VERSION ""

NS_ :

BS_:

BU_: AGSM BCM BSM CADM DMSM DTCM ECM EVCU2 GNMM HCP IPC RFHM SGW TCM
BO_ 1474 IPC_VEHICLE_SETUP2: 48 IPC
 SG_ AUX1_HLEnbl : 9|1@0+ (1,0) [0|1] "" BCM,SGW
 SG_ AUX1_PWRMD : 213|1@0+ (1,0) [0|1] "" BCM,SGW
 SG_ AUX1_TYPE : 13|1@0+ (1,0) [0|1] "" BCM,SGW
 SG_ AUX2_HLEnbl : 8|1@0+ (1,0) [0|1] "" BCM,SGW
 SG_ AUX2_PWRMD : 0|1@0+ (1,0) [0|1] "" BCM,SGW
 SG_ AUX2_TYPE : 12|1@0+ (1,0) [0|1] "" BCM,SGW
 SG_ AUX3_HLEnbl : 23|1@0+ (1,0) [0|1] "" BCM,SGW
 SG_ AUX3_PWRMD : 15|1@0+ (1,0) [0|1] "" BCM,SGW
 SG_ AUX3_TYPE : 11|1@0+ (1,0) [0|1] "" BCM,SGW
 SG_ AUX4_HLEnbl : 22|1@0+ (1,0) [0|1] "" BCM,SGW
 SG_ AUX4_PWRMD : 14|1@0+ (1,0) [0|1] "" BCM,SGW
 SG_ AUX4_TYPE : 10|1@0+ (1,0) [0|1] "" BCM,SGW
 SG_ AUX5_HLEnbl : 55|1@0+ (1,0) [0|1] "" BCM,SGW
 SG_ AUX5_PWRMD : 43|1@0+ (1,0) [0|1] "" BCM,SGW
 SG_ AUX5_TYPE : 41|1@0+ (1,0) [0|1] "" BCM,SGW
 SG_ AUX6_HLEnbl : 54|1@0+ (1,0) [0|1] "" BCM,SGW
 SG_ AUX6_PWRMD : 42|1@0+ (1,0) [0|1] "" BCM,SGW
 SG_ AUX6_TYPE : 40|1@0+ (1,0) [0|1] "" BCM,SGW
 SG_ CRC_IPCVS2 : 319|8@0+ (1,0) [0|255] "-" EVCU2
 SG_ Default_Ride_Height : 44|1@0+ (1,0) [0|1] "" BCM,SGW
 SG_ Display_Synch : 59|1@0+ (1,0) [0|1] "" SGW
 SG_ FOA_Alert_Type : 6|2@0+ (1,0) [0|3] "" BCM,SGW
 SG_ Fuel_Saver_Display : 26|1@0+ (1,0) [0|1] "" BCM,SGW
 SG_ MessageCounter_IPCVS2 : 307|4@0+ (1,0) [0|15] "-" EVCU2
 SG_ ParkSenseSignalView : 37|1@0+ (1,0) [0|1] "" BCM,SGW
 SG_ PFTM_Alert : 95|1@0+ (1,0) [0|1] "" BCM,SGW
 SG_ PFTM_Enable : 94|1@0+ (1,0) [0|1] "" SGW
 SG_ Power_Tailgate_Enable : 53|1@0+ (1,0) [0|1] "" BCM,SGW
 SG_ Rear_G_LGT_with_Cargo_Lights : 47|1@0+ (1,0) [0|1] "" BCM,SGW
 SG_ Rear_Guidance_Light_Status : 62|1@0+ (1,0) [0|1] "" BCM,SGW
 SG_ Rear_Lights_with_Approach : 50|1@0+ (1,0) [0|1] "" BCM,SGW
 SG_ SignatureLightingEnable : 93|1@0+ (1,0) [0|1] "" BCM,SGW
 SG_ Trailer_Light_Check : 7|1@0+ (1,0) [0|1] "" BCM,SGW
 SG_ TSI_Offset_Kph : 31|4@0+ (1,0) [0|15] "" BCM,SGW
 SG_ TSI_Offset_Mph : 19|4@0+ (1,0) [0|15] "" BCM,SGW
 SG_ TurnSignalView : 34|2@0+ (1,0) [0|3] "" BCM,SGW
 SG_ WorksiteINVM_Audible_LFW : 61|1@0+ (1,0) [0|1] "" BCM,SGW
 SG_ WorksiteINVM_Visual_LFW : 60|1@0+ (1,0) [0|1] "" BCM,SGW

BO_ 753 LV_CHARGER1: 32 HCP
 SG_ CRC_LV_CHARGER1 : 191|8@0+ (1,0) [0|255] "-" ECM
 SG_ DCDC_OperationModeSts : 7|4@0+ (1,0) [0|0] "-" ECM
 SG_ HVDC_CurrentFeedback : 3|12@0+ (0.1,-149) [-149|150] "Amp" ECM
 SG_ HVDC_VoltageFeedback : 35|12@0+ (0.125,0) [0|510] "V" ECM
 SG_ LVDC_CurrentFeedback : 19|12@0+ (0.15,-299) [-299|299.5] "Amp" ECM
 SG_ MessageCounter_LV_CHARGER1 : 179|4@0+ (1,0) [0|15] "-" ECM

BO_ 1062 MCPA_DATA2: 64 EVCU2
 SG_ MCPA_Temp : 7|8@0+ (1,-40) [-40|215] "°C" SGW

BO_ 125 MESS_TTPM1: 32 BCM
 SG_ MESS_TTPM1 : 7|64@0+ (1,0) [0|0] "" SGW

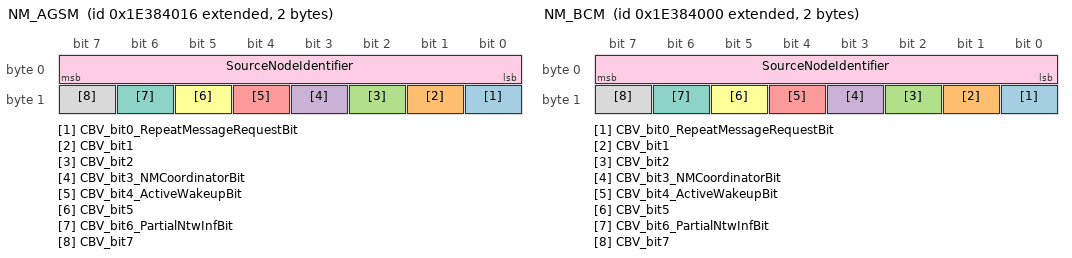
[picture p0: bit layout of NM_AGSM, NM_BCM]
BO_ 2654486550 NM_AGSM: 2 AGSM
 SG_ CBV_bit0_RepeatMessageRequestBit : 8|1@0+ (1,0) [0|1] "" BCM,BSM,CADM,DTCM,ECM,EVCU2,GNMM,HCP,IPC,RFHM,SGW,TCM
 SG_ CBV_bit1 : 9|1@0+ (1,0) [0|1] "" BCM,BSM,CADM,DTCM,ECM,EVCU2,GNMM,HCP,IPC,RFHM,SGW,TCM
 SG_ CBV_bit2 : 10|1@0+ (1,0) [0|1] "" BCM,BSM,CADM,DTCM,ECM,EVCU2,GNMM,HCP,IPC,RFHM,SGW,TCM
 SG_ CBV_bit3_NMCoordinatorBit : 11|1@0+ (1,0) [0|1] "" BCM,BSM,CADM,DTCM,ECM,EVCU2,GNMM,HCP,IPC,RFHM,SGW,TCM
 SG_ CBV_bit4_ActiveWakeupBit : 12|1@0+ (1,0) [0|1] "" BCM,BSM,CADM,DTCM,ECM,EVCU2,GNMM,HCP,IPC,RFHM,SGW,TCM
 SG_ CBV_bit5 : 13|1@0+ (1,0) [0|1] "" BCM,BSM,CADM,DTCM,ECM,EVCU2,GNMM,HCP,IPC,RFHM,SGW,TCM
 SG_ CBV_bit6_PartialNtwInfBit : 14|1@0+ (1,0) [0|1] "" BCM,BSM,CADM,DTCM,ECM,EVCU2,GNMM,HCP,IPC,RFHM,SGW,TCM
 SG_ CBV_bit7 : 15|1@0+ (1,0) [0|1] "" BCM,BSM,CADM,DTCM,ECM,EVCU2,GNMM,HCP,IPC,RFHM,SGW,TCM
 SG_ SourceNodeIdentifier : 7|8@0+ (1,0) [0|63] "-" BCM,BSM,CADM,DTCM,ECM,EVCU2,GNMM,HCP,IPC,RFHM,SGW,TCM

BO_ 2654486528 NM_BCM: 2 BCM
 SG_ CBV_bit0_RepeatMessageRequestBit : 8|1@0+ (1,0) [0|1] "" AGSM,BSM,CADM,DTCM,ECM,EVCU2,GNMM,HCP,IPC,RFHM,SGW,TCM
 SG_ CBV_bit1 : 9|1@0+ (1,0) [0|1] "" AGSM,BSM,CADM,DTCM,ECM,EVCU2,GNMM,HCP,IPC,RFHM,SGW,TCM
 SG_ CBV_bit2 : 10|1@0+ (1,0) [0|1] "" AGSM,BSM,CADM,DTCM,ECM,EVCU2,GNMM,HCP,IPC,RFHM,SGW,TCM
 SG_ CBV_bit3_NMCoordinatorBit : 11|1@0+ (1,0) [0|1] "" AGSM,BSM,CADM,DTCM,ECM,EVCU2,GNMM,HCP,IPC,RFHM,SGW,TCM
 SG_ CBV_bit4_ActiveWakeupBit : 12|1@0+ (1,0) [0|1] "" AGSM,BSM,CADM,DTCM,ECM,EVCU2,GNMM,HCP,IPC,RFHM,SGW,TCM
 SG_ CBV_bit5 : 13|1@0+ (1,0) [0|1] "" AGSM,BSM,CADM,DTCM,ECM,EVCU2,GNMM,HCP,IPC,RFHM,SGW,TCM
 SG_ CBV_bit6_PartialNtwInfBit : 14|1@0+ (1,0) [0|1] "" AGSM,BSM,CADM,DTCM,ECM,EVCU2,GNMM,HCP,IPC,RFHM,SGW,TCM
 SG_ CBV_bit7 : 15|1@0+ (1,0) [0|1] "" AGSM,BSM,CADM,DTCM,ECM,EVCU2,GNMM,HCP,IPC,RFHM,SGW,TCM
 SG_ SourceNodeIdentifier : 7|8@0+ (1,0) [0|255] "-" AGSM,BSM,CADM,DTCM,ECM,EVCU2,GNMM,HCP,IPC,RFHM,SGW,TCM

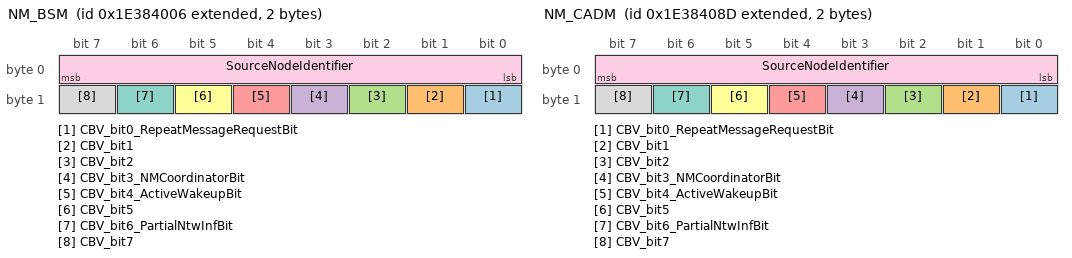
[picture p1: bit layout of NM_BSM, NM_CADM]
BO_ 2654486534 NM_BSM: 2 BSM
 SG_ CBV_bit0_RepeatMessageRequestBit : 8|1@0+ (1,0) [0|1] "" AGSM,BCM,CADM,DTCM,ECM,EVCU2,GNMM,HCP,IPC,RFHM,SGW,TCM
 SG_ CBV_bit1 : 9|1@0+ (1,0) [0|1] "" AGSM,BCM,CADM,DTCM,ECM,EVCU2,GNMM,HCP,IPC,RFHM,SGW,TCM
 SG_ CBV_bit2 : 10|1@0+ (1,0) [0|1] "" AGSM,BCM,CADM,DTCM,ECM,EVCU2,GNMM,HCP,IPC,RFHM,SGW,TCM
 SG_ CBV_bit3_NMCoordinatorBit : 11|1@0+ (1,0) [0|1] "" AGSM,BCM,CADM,DTCM,ECM,EVCU2,GNMM,HCP,IPC,RFHM,SGW,TCM
 SG_ CBV_bit4_ActiveWakeupBit : 12|1@0+ (1,0) [0|1] "" AGSM,BCM,CADM,DTCM,ECM,EVCU2,GNMM,HCP,IPC,RFHM,SGW,TCM
 SG_ CBV_bit5 : 13|1@0+ (1,0) [0|1] "" AGSM,BCM,CADM,DTCM,ECM,EVCU2,GNMM,HCP,IPC,RFHM,SGW,TCM
 SG_ CBV_bit6_PartialNtwInfBit : 14|1@0+ (1,0) [0|1] "" AGSM,BCM,CADM,DTCM,ECM,EVCU2,GNMM,HCP,IPC,RFHM,SGW,TCM
 SG_ CBV_bit7 : 15|1@0+ (1,0) [0|1] "" AGSM,BCM,CADM,DTCM,ECM,EVCU2,GNMM,HCP,IPC,RFHM,SGW,TCM
 SG_ SourceNodeIdentifier : 7|8@0+ (1,0) [0|255] "-" AGSM,BCM,CADM,DTCM,ECM,EVCU2,GNMM,HCP,IPC,RFHM,SGW,TCM

BO_ 2654486669 NM_CADM: 2 CADM
 SG_ CBV_bit0_RepeatMessageRequestBit : 8|1@0+ (1,0) [0|1] "" AGSM,BCM,BSM,DTCM,ECM,EVCU2,GNMM,HCP,IPC,RFHM,SGW,TCM
 SG_ CBV_bit1 : 9|1@0+ (1,0) [0|1] "" AGSM,BCM,BSM,DTCM,ECM,EVCU2,GNMM,HCP,IPC,RFHM,SGW,TCM
 SG_ CBV_bit2 : 10|1@0+ (1,0) [0|1] "" AGSM,BCM,BSM,DTCM,ECM,EVCU2,GNMM,HCP,IPC,RFHM,SGW,TCM
 SG_ CBV_bit3_NMCoordinatorBit : 11|1@0+ (1,0) [0|1] "" AGSM,BCM,BSM,DTCM,ECM,EVCU2,GNMM,HCP,IPC,RFHM,SGW,TCM
 SG_ CBV_bit4_ActiveWakeupBit : 12|1@0+ (1,0) [0|1] "" AGSM,BCM,BSM,DTCM,ECM,EVCU2,GNMM,HCP,IPC,RFHM,SGW,TCM
 SG_ CBV_bit5 : 13|1@0+ (1,0) [0|1] "" AGSM,BCM,BSM,DTCM,ECM,EVCU2,GNMM,HCP,IPC,RFHM,SGW,TCM
 SG_ CBV_bit6_PartialNtwInfBit : 14|1@0+ (1,0) [0|1] "" AGSM,BCM,BSM,DTCM,ECM,EVCU2,GNMM,HCP,IPC,RFHM,SGW,TCM
 SG_ CBV_bit7 : 15|1@0+ (1,0) [0|1] "" AGSM,BCM,BSM,DTCM,ECM,EVCU2,GNMM,HCP,IPC,RFHM,SGW,TCM
 SG_ SourceNodeIdentifier : 7|8@0+ (1,0) [0|255] "-" AGSM,BCM,BSM,DTCM,ECM,EVCU2,GNMM,HCP,IPC,RFHM,SGW,TCM

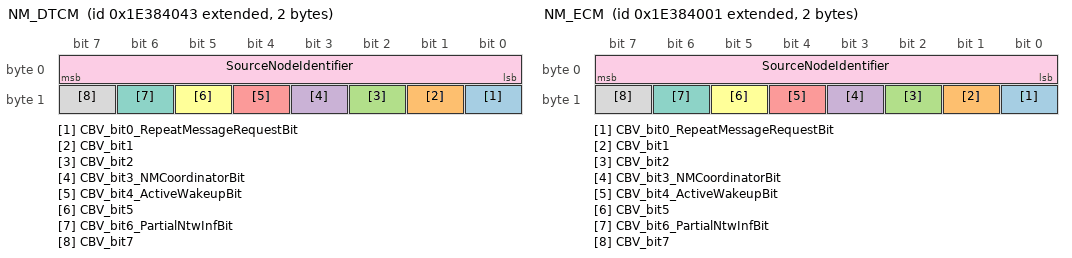
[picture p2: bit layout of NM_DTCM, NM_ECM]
BO_ 2654486595 NM_DTCM: 2 DTCM
 SG_ CBV_bit0_RepeatMessageRequestBit : 8|1@0+ (1,0) [0|1] "" AGSM,BCM,BSM,CADM,ECM,EVCU2,GNMM,HCP,IPC,RFHM,SGW,TCM
 SG_ CBV_bit1 : 9|1@0+ (1,0) [0|1] "" AGSM,BCM,BSM,CADM,ECM,EVCU2,GNMM,HCP,IPC,RFHM,SGW,TCM
 SG_ CBV_bit2 : 10|1@0+ (1,0) [0|1] "" AGSM,BCM,BSM,CADM,ECM,EVCU2,GNMM,HCP,IPC,RFHM,SGW,TCM
 SG_ CBV_bit3_NMCoordinatorBit : 11|1@0+ (1,0) [0|1] "" AGSM,BCM,BSM,CADM,ECM,EVCU2,GNMM,HCP,IPC,RFHM,SGW,TCM
 SG_ CBV_bit4_ActiveWakeupBit : 12|1@0+ (1,0) [0|1] "" AGSM,BCM,BSM,CADM,ECM,EVCU2,GNMM,HCP,IPC,RFHM,SGW,TCM
 SG_ CBV_bit5 : 13|1@0+ (1,0) [0|1] "" AGSM,BCM,BSM,CADM,ECM,EVCU2,GNMM,HCP,IPC,RFHM,SGW,TCM
 SG_ CBV_bit6_PartialNtwInfBit : 14|1@0+ (1,0) [0|1] "" AGSM,BCM,BSM,CADM,ECM,EVCU2,GNMM,HCP,IPC,RFHM,SGW,TCM
 SG_ CBV_bit7 : 15|1@0+ (1,0) [0|1] "" AGSM,BCM,BSM,CADM,ECM,EVCU2,GNMM,HCP,IPC,RFHM,SGW,TCM
 SG_ SourceNodeIdentifier : 7|8@0+ (1,0) [0|255] "-" AGSM,BCM,BSM,CADM,ECM,EVCU2,GNMM,HCP,IPC,RFHM,SGW,TCM

BO_ 2654486529 NM_ECM: 2 ECM
 SG_ CBV_bit0_RepeatMessageRequestBit : 8|1@0+ (1,0) [0|1] "" AGSM,BCM,BSM,CADM,DTCM,EVCU2,GNMM,HCP,IPC,RFHM,SGW,TCM
 SG_ CBV_bit1 : 9|1@0+ (1,0) [0|1] "" AGSM,BCM,BSM,CADM,DTCM,EVCU2,GNMM,HCP,IPC,RFHM,SGW,TCM
 SG_ CBV_bit2 : 10|1@0+ (1,0) [0|1] "" AGSM,BCM,BSM,CADM,DTCM,EVCU2,GNMM,HCP,IPC,RFHM,SGW,TCM
 SG_ CBV_bit3_NMCoordinatorBit : 11|1@0+ (1,0) [0|1] "" AGSM,BCM,BSM,CADM,DTCM,EVCU2,GNMM,HCP,IPC,RFHM,SGW,TCM
 SG_ CBV_bit4_ActiveWakeupBit : 12|1@0+ (1,0) [0|1] "" AGSM,BCM,BSM,CADM,DTCM,EVCU2,GNMM,HCP,IPC,RFHM,SGW,TCM
 SG_ CBV_bit5 : 13|1@0+ (1,0) [0|1] "" AGSM,BCM,BSM,CADM,DTCM,EVCU2,GNMM,HCP,IPC,RFHM,SGW,TCM
 SG_ CBV_bit6_PartialNtwInfBit : 14|1@0+ (1,0) [0|1] "" AGSM,BCM,BSM,CADM,DTCM,EVCU2,GNMM,HCP,IPC,RFHM,SGW,TCM
 SG_ CBV_bit7 : 15|1@0+ (1,0) [0|1] "" AGSM,BCM,BSM,CADM,DTCM,EVCU2,GNMM,HCP,IPC,RFHM,SGW,TCM
 SG_ SourceNodeIdentifier : 7|8@0+ (1,0) [0|255] "-" AGSM,BCM,BSM,CADM,DTCM,EVCU2,GNMM,HCP,IPC,RFHM,SGW,TCM

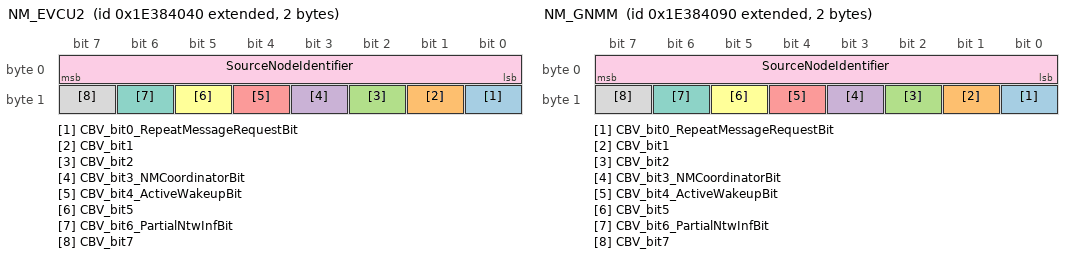
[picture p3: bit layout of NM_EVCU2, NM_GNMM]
BO_ 2654486592 NM_EVCU2: 2 EVCU2
 SG_ CBV_bit0_RepeatMessageRequestBit : 8|1@0+ (1,0) [0|1] "" AGSM,BCM,BSM,CADM,DTCM,ECM,GNMM,HCP,IPC,RFHM,SGW,TCM
 SG_ CBV_bit1 : 9|1@0+ (1,0) [0|1] "" AGSM,BCM,BSM,CADM,DTCM,ECM,GNMM,HCP,IPC,RFHM,SGW,TCM
 SG_ CBV_bit2 : 10|1@0+ (1,0) [0|1] "" AGSM,BCM,BSM,CADM,DTCM,ECM,GNMM,HCP,IPC,RFHM,SGW,TCM
 SG_ CBV_bit3_NMCoordinatorBit : 11|1@0+ (1,0) [0|1] "" AGSM,BCM,BSM,CADM,DTCM,ECM,GNMM,HCP,IPC,RFHM,SGW,TCM
 SG_ CBV_bit4_ActiveWakeupBit : 12|1@0+ (1,0) [0|1] "" AGSM,BCM,BSM,CADM,DTCM,ECM,GNMM,HCP,IPC,RFHM,SGW,TCM
 SG_ CBV_bit5 : 13|1@0+ (1,0) [0|1] "" AGSM,BCM,BSM,CADM,DTCM,ECM,GNMM,HCP,IPC,RFHM,SGW,TCM
 SG_ CBV_bit6_PartialNtwInfBit : 14|1@0+ (1,0) [0|1] "" AGSM,BCM,BSM,CADM,DTCM,ECM,GNMM,HCP,IPC,RFHM,SGW,TCM
 SG_ CBV_bit7 : 15|1@0+ (1,0) [0|1] "" AGSM,BCM,BSM,CADM,DTCM,ECM,GNMM,HCP,IPC,RFHM,SGW,TCM
 SG_ SourceNodeIdentifier : 7|8@0+ (1,0) [0|255] "-" AGSM,BCM,BSM,CADM,DTCM,ECM,GNMM,HCP,IPC,RFHM,SGW,TCM

BO_ 2654486672 NM_GNMM: 2 GNMM
 SG_ CBV_bit0_RepeatMessageRequestBit : 8|1@0+ (1,0) [0|1] "" AGSM,BCM,BSM,CADM,DTCM,ECM,EVCU2,HCP,IPC,RFHM,SGW,TCM
 SG_ CBV_bit1 : 9|1@0+ (1,0) [0|1] "" AGSM,BCM,BSM,CADM,DTCM,ECM,EVCU2,HCP,IPC,RFHM,SGW,TCM
 SG_ CBV_bit2 : 10|1@0+ (1,0) [0|1] "" AGSM,BCM,BSM,CADM,DTCM,ECM,EVCU2,HCP,IPC,RFHM,SGW,TCM
 SG_ CBV_bit3_NMCoordinatorBit : 11|1@0+ (1,0) [0|1] "" AGSM,BCM,BSM,CADM,DTCM,ECM,EVCU2,HCP,IPC,RFHM,SGW,TCM
 SG_ CBV_bit4_ActiveWakeupBit : 12|1@0+ (1,0) [0|1] "" AGSM,BCM,BSM,CADM,DTCM,ECM,EVCU2,HCP,IPC,RFHM,SGW,TCM
 SG_ CBV_bit5 : 13|1@0+ (1,0) [0|1] "" AGSM,BCM,BSM,CADM,DTCM,ECM,EVCU2,HCP,IPC,RFHM,SGW,TCM
 SG_ CBV_bit6_PartialNtwInfBit : 14|1@0+ (1,0) [0|1] "" AGSM,BCM,BSM,CADM,DTCM,ECM,EVCU2,HCP,IPC,RFHM,SGW,TCM
 SG_ CBV_bit7 : 15|1@0+ (1,0) [0|1] "" AGSM,BCM,BSM,CADM,DTCM,ECM,EVCU2,HCP,IPC,RFHM,SGW,TCM
 SG_ SourceNodeIdentifier : 7|8@0+ (1,0) [0|255] "-" AGSM,BCM,BSM,CADM,DTCM,ECM,EVCU2,HCP,IPC,RFHM,SGW,TCM

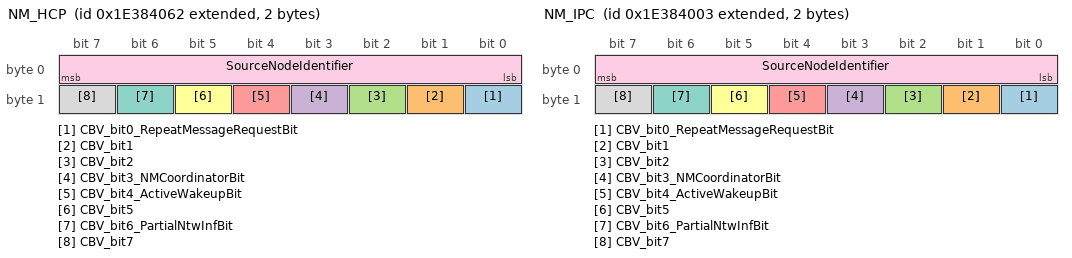
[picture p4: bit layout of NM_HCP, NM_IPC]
BO_ 2654486626 NM_HCP: 2 HCP
 SG_ CBV_bit0_RepeatMessageRequestBit : 8|1@0+ (1,0) [0|1] "" AGSM,BCM,BSM,CADM,DTCM,ECM,EVCU2,GNMM,IPC,RFHM,SGW,TCM
 SG_ CBV_bit1 : 9|1@0+ (1,0) [0|1] "" AGSM,BCM,BSM,CADM,DTCM,ECM,EVCU2,GNMM,IPC,RFHM,SGW,TCM
 SG_ CBV_bit2 : 10|1@0+ (1,0) [0|1] "" AGSM,BCM,BSM,CADM,DTCM,ECM,EVCU2,GNMM,IPC,RFHM,SGW,TCM
 SG_ CBV_bit3_NMCoordinatorBit : 11|1@0+ (1,0) [0|1] "" AGSM,BCM,BSM,CADM,DTCM,ECM,EVCU2,GNMM,IPC,RFHM,SGW,TCM
 SG_ CBV_bit4_ActiveWakeupBit : 12|1@0+ (1,0) [0|1] "" AGSM,BCM,BSM,CADM,DTCM,ECM,EVCU2,GNMM,IPC,RFHM,SGW,TCM
 SG_ CBV_bit5 : 13|1@0+ (1,0) [0|1] "" AGSM,BCM,BSM,CADM,DTCM,ECM,EVCU2,GNMM,IPC,RFHM,SGW,TCM
 SG_ CBV_bit6_PartialNtwInfBit : 14|1@0+ (1,0) [0|1] "" AGSM,BCM,BSM,CADM,DTCM,ECM,EVCU2,GNMM,IPC,RFHM,SGW,TCM
 SG_ CBV_bit7 : 15|1@0+ (1,0) [0|1] "" AGSM,BCM,BSM,CADM,DTCM,ECM,EVCU2,GNMM,IPC,RFHM,SGW,TCM
 SG_ SourceNodeIdentifier : 7|8@0+ (1,0) [0|255] "-" AGSM,BCM,BSM,CADM,DTCM,ECM,EVCU2,GNMM,IPC,RFHM,SGW,TCM

BO_ 2654486531 NM_IPC: 2 IPC
 SG_ CBV_bit0_RepeatMessageRequestBit : 8|1@0+ (1,0) [0|1] "" AGSM,BCM,BSM,CADM,DTCM,ECM,EVCU2,GNMM,HCP,RFHM,SGW,TCM
 SG_ CBV_bit1 : 9|1@0+ (1,0) [0|1] "" AGSM,BCM,BSM,CADM,DTCM,ECM,EVCU2,GNMM,HCP,RFHM,SGW,TCM
 SG_ CBV_bit2 : 10|1@0+ (1,0) [0|1] "" AGSM,BCM,BSM,CADM,DTCM,ECM,EVCU2,GNMM,HCP,RFHM,SGW,TCM
 SG_ CBV_bit3_NMCoordinatorBit : 11|1@0+ (1,0) [0|1] "" AGSM,BCM,BSM,CADM,DTCM,ECM,EVCU2,GNMM,HCP,RFHM,SGW,TCM
 SG_ CBV_bit4_ActiveWakeupBit : 12|1@0+ (1,0) [0|1] "" AGSM,BCM,BSM,CADM,DTCM,ECM,EVCU2,GNMM,HCP,RFHM,SGW,TCM
 SG_ CBV_bit5 : 13|1@0+ (1,0) [0|1] "" AGSM,BCM,BSM,CADM,DTCM,ECM,EVCU2,GNMM,HCP,RFHM,SGW,TCM
 SG_ CBV_bit6_PartialNtwInfBit : 14|1@0+ (1,0) [0|1] "" AGSM,BCM,BSM,CADM,DTCM,ECM,EVCU2,GNMM,HCP,RFHM,SGW,TCM
 SG_ CBV_bit7 : 15|1@0+ (1,0) [0|1] "" AGSM,BCM,BSM,CADM,DTCM,ECM,EVCU2,GNMM,HCP,RFHM,SGW,TCM
 SG_ SourceNodeIdentifier : 7|8@0+ (1,0) [0|255] "-" AGSM,BCM,BSM,CADM,DTCM,ECM,EVCU2,GNMM,HCP,RFHM,SGW,TCM

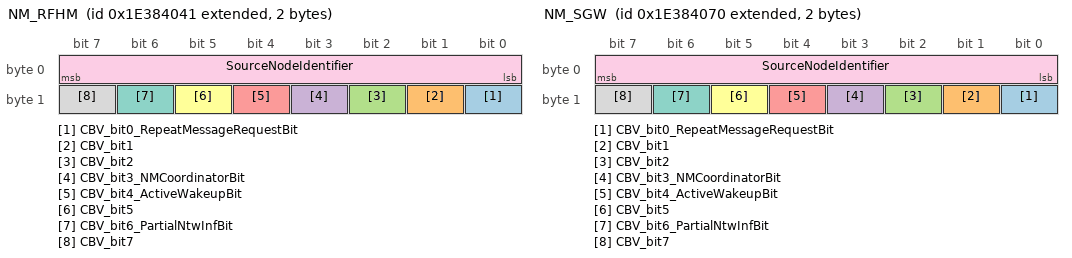
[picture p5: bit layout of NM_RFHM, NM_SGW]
BO_ 2654486593 NM_RFHM: 2 RFHM
 SG_ CBV_bit0_RepeatMessageRequestBit : 8|1@0+ (1,0) [0|1] "" AGSM,BCM,BSM,CADM,DTCM,ECM,EVCU2,GNMM,HCP,IPC,SGW,TCM
 SG_ CBV_bit1 : 9|1@0+ (1,0) [0|1] "" AGSM,BCM,BSM,CADM,DTCM,ECM,EVCU2,GNMM,HCP,IPC,SGW,TCM
 SG_ CBV_bit2 : 10|1@0+ (1,0) [0|1] "" AGSM,BCM,BSM,CADM,DTCM,ECM,EVCU2,GNMM,HCP,IPC,SGW,TCM
 SG_ CBV_bit3_NMCoordinatorBit : 11|1@0+ (1,0) [0|1] "" AGSM,BCM,BSM,CADM,DTCM,ECM,EVCU2,GNMM,HCP,IPC,SGW,TCM
 SG_ CBV_bit4_ActiveWakeupBit : 12|1@0+ (1,0) [0|1] "" AGSM,BCM,BSM,CADM,DTCM,ECM,EVCU2,GNMM,HCP,IPC,SGW,TCM
 SG_ CBV_bit5 : 13|1@0+ (1,0) [0|1] "" AGSM,BCM,BSM,CADM,DTCM,ECM,EVCU2,GNMM,HCP,IPC,SGW,TCM
 SG_ CBV_bit6_PartialNtwInfBit : 14|1@0+ (1,0) [0|1] "" AGSM,BCM,BSM,CADM,DTCM,ECM,EVCU2,GNMM,HCP,IPC,SGW,TCM
 SG_ CBV_bit7 : 15|1@0+ (1,0) [0|1] "" AGSM,BCM,BSM,CADM,DTCM,ECM,EVCU2,GNMM,HCP,IPC,SGW,TCM
 SG_ SourceNodeIdentifier : 7|8@0+ (1,0) [0|255] "-" AGSM,BCM,BSM,CADM,DTCM,ECM,EVCU2,GNMM,HCP,IPC,SGW,TCM

BO_ 2654486640 NM_SGW: 2 SGW
 SG_ CBV_bit0_RepeatMessageRequestBit : 8|1@0+ (1,0) [0|1] "" AGSM,BCM,BSM,CADM,DTCM,ECM,EVCU2,GNMM,HCP,IPC,RFHM,TCM
 SG_ CBV_bit1 : 9|1@0+ (1,0) [0|1] "" AGSM,BCM,BSM,CADM,DTCM,ECM,EVCU2,GNMM,HCP,IPC,RFHM,TCM
 SG_ CBV_bit2 : 10|1@0+ (1,0) [0|1] "" AGSM,BCM,BSM,CADM,DTCM,ECM,EVCU2,GNMM,HCP,IPC,RFHM,TCM
 SG_ CBV_bit3_NMCoordinatorBit : 11|1@0+ (1,0) [0|1] "" AGSM,BCM,BSM,CADM,DTCM,ECM,EVCU2,GNMM,HCP,IPC,RFHM,TCM
 SG_ CBV_bit4_ActiveWakeupBit : 12|1@0+ (1,0) [0|1] "" AGSM,BCM,BSM,CADM,DTCM,ECM,EVCU2,GNMM,HCP,IPC,RFHM,TCM
 SG_ CBV_bit5 : 13|1@0+ (1,0) [0|1] "" AGSM,BCM,BSM,CADM,DTCM,ECM,EVCU2,GNMM,HCP,IPC,RFHM,TCM
 SG_ CBV_bit6_PartialNtwInfBit : 14|1@0+ (1,0) [0|1] "" AGSM,BCM,BSM,CADM,DTCM,ECM,EVCU2,GNMM,HCP,IPC,RFHM,TCM
 SG_ CBV_bit7 : 15|1@0+ (1,0) [0|1] "" AGSM,BCM,BSM,CADM,DTCM,ECM,EVCU2,GNMM,HCP,IPC,RFHM,TCM
 SG_ SourceNodeIdentifier : 7|8@0+ (1,0) [0|255] "-" AGSM,BCM,BSM,CADM,DTCM,ECM,EVCU2,GNMM,HCP,IPC,RFHM,TCM

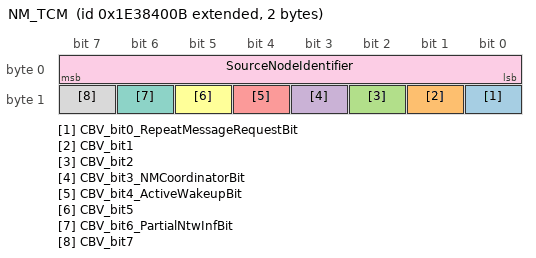
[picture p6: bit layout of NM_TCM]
BO_ 2654486539 NM_TCM: 2 TCM
 SG_ CBV_bit0_RepeatMessageRequestBit : 8|1@0+ (1,0) [0|1] "" AGSM,BCM,BSM,CADM,DTCM,ECM,EVCU2,GNMM,HCP,IPC,RFHM,SGW
 SG_ CBV_bit1 : 9|1@0+ (1,0) [0|1] "" AGSM,BCM,BSM,CADM,DTCM,ECM,EVCU2,GNMM,HCP,IPC,RFHM,SGW
 SG_ CBV_bit2 : 10|1@0+ (1,0) [0|1] "" AGSM,BCM,BSM,CADM,DTCM,ECM,EVCU2,GNMM,HCP,IPC,RFHM,SGW
 SG_ CBV_bit3_NMCoordinatorBit : 11|1@0+ (1,0) [0|1] "" AGSM,BCM,BSM,CADM,DTCM,ECM,EVCU2,GNMM,HCP,IPC,RFHM,SGW
 SG_ CBV_bit4_ActiveWakeupBit : 12|1@0+ (1,0) [0|1] "" AGSM,BCM,BSM,CADM,DTCM,ECM,EVCU2,GNMM,HCP,IPC,RFHM,SGW
 SG_ CBV_bit5 : 13|1@0+ (1,0) [0|1] "" AGSM,BCM,BSM,CADM,DTCM,ECM,EVCU2,GNMM,HCP,IPC,RFHM,SGW
 SG_ CBV_bit6_PartialNtwInfBit : 14|1@0+ (1,0) [0|1] "" AGSM,BCM,BSM,CADM,DTCM,ECM,EVCU2,GNMM,HCP,IPC,RFHM,SGW
 SG_ CBV_bit7 : 15|1@0+ (1,0) [0|1] "" AGSM,BCM,BSM,CADM,DTCM,ECM,EVCU2,GNMM,HCP,IPC,RFHM,SGW
 SG_ SourceNodeIdentifier : 7|8@0+ (1,0) [0|255] "-" AGSM,BCM,BSM,CADM,DTCM,ECM,EVCU2,GNMM,HCP,IPC,RFHM,SGW

BO_TX_BU_ 125 : BCM,RFHM;
CM_ SG_ 1474 AUX1_HLEnbl "AUX Switch 1 Hold Last State";
CM_ SG_ 1474 AUX1_PWRMD "AUX Switch 1 Power Mode";
CM_ SG_ 1474 AUX1_TYPE "AUX Switch 1 Switch Type";
CM_ SG_ 1474 AUX2_HLEnbl "AUX Switch 2 Hold Last State";
CM_ SG_ 1474 AUX2_PWRMD "AUX Switch 2 Power Mode";
CM_ SG_ 1474 AUX2_TYPE "AUX Switch 2 Switch Type";
CM_ SG_ 1474 AUX3_HLEnbl "AUX Switch 3 Hold Last State";
CM_ SG_ 1474 AUX3_PWRMD "AUX Switch 3 Power Mode";
CM_ SG_ 1474 AUX3_TYPE "AUX Switch 3 Switch Type";
CM_ SG_ 1474 AUX4_HLEnbl "AUX Switch 4 Hold Last State";
CM_ SG_ 1474 AUX4_PWRMD "AUX Switch 4 Power Mode";
CM_ SG_ 1474 AUX4_TYPE "AUX Switch 4 Switch Type";
CM_ SG_ 1474 AUX5_HLEnbl "Aux switch 5 enable holding last state; enabled = [1]";
CM_ SG_ 1474 AUX5_PWRMD "Aux switch 5 power mode; ignition = [0], battery = [1]";
CM_ SG_ 1474 AUX5_TYPE "Aux switch 5 behavior; Latching = [0], Momentary = [1]";
CM_ SG_ 1474 AUX6_HLEnbl "Aux switch 6 enable holding last state; enabled = [1]";
CM_ SG_ 1474 AUX6_PWRMD "Aux switch 6 power mode; ignition = [0], battery = [1]";
CM_ SG_ 1474 AUX6_TYPE "Aux switch 6 behavior; Latching = [0], Momentary = [1]";
CM_ SG_ 1474 CRC_IPCVS2 "CRC according to SAE J1850 standard at each frame transmission.";
CM_ SG_ 1474 Default_Ride_Height "Default Ride Height setting; Enable Default Ride Height mode = [1]";
CM_ SG_ 1474 Display_Synch "Display Synch Customer Setting; ON = [1]";
CM_ SG_ 1474 FOA_Alert_Type "Forgotten Object Alert Type";
CM_ SG_ 1474 Fuel_Saver_Display "Fuel saver display indicator status (1=enabled)";
CM_ SG_ 1474 MessageCounter_IPCVS2 "This signal is a counter used for safety checks strategies. This counter is incremented of 1 (one) unit at each frame transmission.";
CM_ SG_ 1474 ParkSenseSignalView "ParkSense Based Camera Activation settings";
CM_ SG_ 1474 PFTM_Alert "Power Front Trunk Audible Alert Enable status, enabled =[1]";
CM_ SG_ 1474 PFTM_Enable "Power Front Trunk Enable status, enabled =[1]";
CM_ SG_ 1474 Power_Tailgate_Enable "Tailgate enable status; enabled = [1]";
CM_ SG_ 1474 Rear_G_LGT_with_Cargo_Lights "Rear Guidance Lights status information, Enable= 1";
CM_ SG_ 1474 Rear_Guidance_Light_Status "Rear Guidance Light Status Setting; ON = [1]";
CM_ SG_ 1474 Rear_Lights_with_Approach "Rear Guidance Lighting with approach setting; On with Approach = [1]";
CM_ SG_ 1474 SignatureLightingEnable "Signature Lighting Enable/Disable";
CM_ SG_ 1474 Trailer_Light_Check "Automatic trailer light sequence activation on connect";
CM_ SG_ 1474 TSI_Offset_Kph "TSI_Offset_Kph";
CM_ SG_ 1474 TSI_Offset_Mph "TSI_Offset_Mph";
CM_ SG_ 1474 TurnSignalView "Turn Signal Activated Blind Spot Camera View with and without Trailer Options";
CM_ SG_ 1474 WorksiteINVM_Audible_LFW "Worksite Inverter Low Fuel Warning audible setting; ON = [1]";
CM_ SG_ 1474 WorksiteINVM_Visual_LFW "Worksite Inverter Low Fuel Warning visual setting; ON = [1]";
CM_ SG_ 753 CRC_LV_CHARGER1 "CRC according to SAE J1850 standard at each frame transmission.";
CM_ SG_ 753 DCDC_OperationModeSts "APM Operation  mode  Status";
CM_ SG_ 753 HVDC_CurrentFeedback "High side current feedback";
CM_ SG_ 753 HVDC_VoltageFeedback "High side  voltage feedback";
CM_ SG_ 753 LVDC_CurrentFeedback "Low side current feedback";
CM_ SG_ 753 MessageCounter_LV_CHARGER1 "This signal is a counter used for safety checks strategies. This counter is incremented of 1 (one) unit at each frame transmission.";
CM_ SG_ 1062 MCPA_Temp "Motor A temperature";
CM_ SG_ 125 MESS_TTPM1 "Measurement data";
CM_ SG_ 2654486550 CBV_bit0_RepeatMessageRequestBit "Repeat Message Request Bit";
CM_ SG_ 2654486550 CBV_bit3_NMCoordinatorBit "NM Coordinator Sleep Bit";
CM_ SG_ 2654486550 CBV_bit4_ActiveWakeupBit "Active Wakeup Bit";
CM_ SG_ 2654486550 CBV_bit6_PartialNtwInfBit "Partial Network Information Bit (PNI)";
CM_ SG_ 2654486550 SourceNodeIdentifier "Source Node Identifier";
CM_ SG_ 2654486528 CBV_bit0_RepeatMessageRequestBit "Repeat Message Request Bit";
CM_ SG_ 2654486528 CBV_bit3_NMCoordinatorBit "NM Coordinator Sleep Bit";
CM_ SG_ 2654486528 CBV_bit4_ActiveWakeupBit "Active Wakeup Bit";
CM_ SG_ 2654486528 CBV_bit6_PartialNtwInfBit "Partial Network Information Bit (PNI)";
CM_ SG_ 2654486528 SourceNodeIdentifier "Source Node Identifier";
CM_ SG_ 2654486534 CBV_bit0_RepeatMessageRequestBit "Repeat Message Request Bit";
CM_ SG_ 2654486534 CBV_bit3_NMCoordinatorBit "NM Coordinator Sleep Bit";
CM_ SG_ 2654486534 CBV_bit4_ActiveWakeupBit "Active Wakeup Bit";
CM_ SG_ 2654486534 CBV_bit6_PartialNtwInfBit "Partial Network Information Bit (PNI)";
CM_ SG_ 2654486534 SourceNodeIdentifier "Source Node Identifier";
CM_ SG_ 2654486669 CBV_bit0_RepeatMessageRequestBit "Repeat Message Request Bit";
CM_ SG_ 2654486669 CBV_bit3_NMCoordinatorBit "NM Coordinator Sleep Bit";
CM_ SG_ 2654486669 CBV_bit4_ActiveWakeupBit "Active Wakeup Bit";
CM_ SG_ 2654486669 CBV_bit6_PartialNtwInfBit "Partial Network Information Bit (PNI)";
CM_ SG_ 2654486669 SourceNodeIdentifier "Source Node Identifier";
CM_ SG_ 2654486595 CBV_bit0_RepeatMessageRequestBit "Repeat Message Request Bit";
CM_ SG_ 2654486595 CBV_bit3_NMCoordinatorBit "NM Coordinator Sleep Bit";
CM_ SG_ 2654486595 CBV_bit4_ActiveWakeupBit "Active Wakeup Bit";
CM_ SG_ 2654486595 CBV_bit6_PartialNtwInfBit "Partial Network Information Bit (PNI)";
CM_ SG_ 2654486595 SourceNodeIdentifier "Source Node Identifier";
CM_ SG_ 2654486529 CBV_bit0_RepeatMessageRequestBit "Repeat Message Request Bit";
CM_ SG_ 2654486529 CBV_bit3_NMCoordinatorBit "NM Coordinator Sleep Bit";
CM_ SG_ 2654486529 CBV_bit4_ActiveWakeupBit "Active Wakeup Bit";
CM_ SG_ 2654486529 CBV_bit6_PartialNtwInfBit "Partial Network Information Bit (PNI)";
CM_ SG_ 2654486529 SourceNodeIdentifier "Source Node Identifier";
CM_ SG_ 2654486672 CBV_bit0_RepeatMessageRequestBit "Repeat Message Request Bit";
CM_ SG_ 2654486672 CBV_bit3_NMCoordinatorBit "NM Coordinator Sleep Bit";
CM_ SG_ 2654486672 CBV_bit4_ActiveWakeupBit "Active Wakeup Bit";
CM_ SG_ 2654486672 CBV_bit6_PartialNtwInfBit "Partial Network Information Bit (PNI)";
CM_ SG_ 2654486672 SourceNodeIdentifier "Source Node Identifier";
CM_ SG_ 2654486626 CBV_bit0_RepeatMessageRequestBit "Repeat Message Request Bit";
CM_ SG_ 2654486626 CBV_bit3_NMCoordinatorBit "NM Coordinator Sleep Bit";
CM_ SG_ 2654486626 CBV_bit4_ActiveWakeupBit "Active Wakeup Bit";
CM_ SG_ 2654486626 CBV_bit6_PartialNtwInfBit "Partial Network Information Bit (PNI)";
CM_ SG_ 2654486626 SourceNodeIdentifier "Source Node Identifier";
CM_ SG_ 2654486531 CBV_bit0_RepeatMessageRequestBit "Repeat Message Request Bit";
CM_ SG_ 2654486531 CBV_bit3_NMCoordinatorBit "NM Coordinator Sleep Bit";
CM_ SG_ 2654486531 CBV_bit4_ActiveWakeupBit "Active Wakeup Bit";
CM_ SG_ 2654486531 CBV_bit6_PartialNtwInfBit "Partial Network Information Bit (PNI)";
CM_ SG_ 2654486531 SourceNodeIdentifier "Source Node Identifier";
CM_ SG_ 2654486593 CBV_bit0_RepeatMessageRequestBit "Repeat Message Request Bit";
CM_ SG_ 2654486593 CBV_bit3_NMCoordinatorBit "NM Coordinator Sleep Bit";
CM_ SG_ 2654486593 CBV_bit4_ActiveWakeupBit "Active Wakeup Bit";
CM_ SG_ 2654486593 CBV_bit6_PartialNtwInfBit "Partial Network Information Bit (PNI)";
CM_ SG_ 2654486593 SourceNodeIdentifier "Source Node Identifier";
CM_ SG_ 2654486640 CBV_bit0_RepeatMessageRequestBit "Repeat Message Request Bit";
CM_ SG_ 2654486640 CBV_bit3_NMCoordinatorBit "NM Coordinator Sleep Bit";
CM_ SG_ 2654486640 CBV_bit4_ActiveWakeupBit "Active Wakeup Bit";
CM_ SG_ 2654486640 CBV_bit6_PartialNtwInfBit "Partial Network Information Bit (PNI)";
CM_ SG_ 2654486640 SourceNodeIdentifier "Source Node Identifier";
CM_ SG_ 2654486539 CBV_bit0_RepeatMessageRequestBit "Repeat Message Request Bit";
CM_ SG_ 2654486539 CBV_bit3_NMCoordinatorBit "NM Coordinator Sleep Bit";
CM_ SG_ 2654486539 CBV_bit4_ActiveWakeupBit "Active Wakeup Bit";
CM_ SG_ 2654486539 CBV_bit6_PartialNtwInfBit "Partial Network Information Bit (PNI)";
CM_ SG_ 2654486539 SourceNodeIdentifier "Source Node Identifier";

BA_DEF_ SG_ "GenSigStartValue" INT 0 2147483647;
BA_DEF_ SG_ "GenSigInactiveValue" INT 0 2147483647;
BA_DEF_ SG_ "GenSigSendType" ENUM "NotUsed","OnWrite","OnWriteWithRepetition","OnChange","OnChangeWithRepetition","IfActive","IfActiveWithRepetition","NoSigSendType";
BA_DEF_ SG_ "SystemSignalLongSymbol" STRING ;
BA_DEF_ SG_ "GenSigTimeoutTime_AGSM" INT 0 65535;
BA_DEF_ SG_ "GenSigTimeoutTime_BCM" INT 0 65535;
BA_DEF_ SG_ "GenSigTimeoutTime_BSM" INT 0 65535;
BA_DEF_ SG_ "GenSigTimeoutTime_CADM" INT 0 65535;
BA_DEF_ SG_ "GenSigTimeoutTime_DMSM" INT 0 65535;
BA_DEF_ SG_ "GenSigTimeoutTime_DTCM" INT 0 65535;
BA_DEF_ SG_ "GenSigTimeoutTime_ECM" INT 0 65535;
BA_DEF_ SG_ "GenSigTimeoutTime_EVCU2" INT 0 65535;
BA_DEF_ SG_ "GenSigTimeoutTime_GNMM" INT 0 65535;
BA_DEF_ SG_ "GenSigTimeoutTime_HCP" INT 0 65535;
BA_DEF_ SG_ "GenSigTimeoutTime_IPC" INT 0 65535;
BA_DEF_ SG_ "GenSigTimeoutTime_RFHM" INT 0 65535;
BA_DEF_ SG_ "GenSigTimeoutTime_SGW" INT 0 65535;
BA_DEF_ SG_ "GenSigTimeoutTime_TCM" INT 0 65535;
BA_DEF_ BO_ "DiagRequest" ENUM "No","Yes";
BA_DEF_ BO_ "Type" ENUM "P","C","PE","COC","PE_Cntrl","E","E_Cntrl","OC","S","BAF","DC","EM","MM","ISO-TP","-";
BA_DEF_ BO_ "DiagResponse" ENUM "No","Yes";
BA_DEF_ BO_ "NmMessage" ENUM "No","Yes";
BA_DEF_ BO_ "GenMsgSendType" ENUM "Cyclic","NotUsed","NotUsed","NotUsed","NotUsed","NotUsed","NotUsed","NotUsed","NoMsgSendType";
BA_DEF_ BO_ "GenMsgNrOfRepetition" INT 0 255;
BA_DEF_ BO_ "GenMsgILSupport" ENUM "No","Yes";
BA_DEF_ BO_ "GenMsgStartDelayTime" INT 0 65535;
BA_DEF_ BO_ "GenMsgCycleTimeFast" INT 0 65535;
BA_DEF_ BO_ "GenMsgCycleTime" INT 0 65535;
BA_DEF_ BO_ "GenMsgDelayTime" INT 0 65535;
BA_DEF_ BO_ "NmAsrMessage" ENUM "No","Yes";
BA_DEF_ BO_ "DiagState" ENUM "No","Yes";
BA_DEF_ BO_ "DiagConnection" HEX 0 65535;
BA_DEF_ BO_ "VFrameFormat" ENUM "StandardCAN","ExtendedCAN","reserved","reserved","reserved","reserved","reserved","reserved","reserved","reserved","reserved","reserved","reserved","reserved","StandardCAN_FD","ExtendedCAN_FD";
BA_DEF_ BO_ "CANFD_BRS" ENUM "0","1";
BA_DEF_DEF_ "DiagRequest" "No";
BA_DEF_DEF_ "Type" "-";
BA_DEF_DEF_ "DiagResponse" "No";
BA_DEF_DEF_ "NmMessage" "No";
BA_DEF_DEF_ "GenMsgSendType" "NoMsgSendType";
BA_DEF_DEF_ "GenMsgNrOfRepetition" 0;
BA_DEF_DEF_ "GenMsgILSupport" "No";
BA_DEF_DEF_ "GenMsgStartDelayTime" 0;
BA_DEF_DEF_ "GenMsgCycleTimeFast" 0;
BA_DEF_DEF_ "GenMsgCycleTime" 0;
BA_DEF_DEF_ "GenMsgDelayTime" 0;
BA_DEF_DEF_ "NmAsrMessage" "No";
BA_DEF_DEF_ "DiagState" "No";
BA_DEF_DEF_ "DiagConnection" 0;
BA_DEF_DEF_ "VFrameFormat" "StandardCAN_FD";
BA_DEF_DEF_ "CANFD_BRS" "0";
BA_DEF_DEF_ "GenSigStartValue" 0;
BA_DEF_DEF_ "GenSigInactiveValue" 0;
BA_DEF_DEF_ "GenSigSendType" "NoSigSendType";
BA_DEF_DEF_ "SystemSignalLongSymbol" "";
BA_DEF_DEF_ "GenSigTimeoutTime_AGSM" 2500;
BA_DEF_DEF_ "GenSigTimeoutTime_BCM" 2500;
BA_DEF_DEF_ "GenSigTimeoutTime_BSM" 2500;
BA_DEF_DEF_ "GenSigTimeoutTime_CADM" 2500;
BA_DEF_DEF_ "GenSigTimeoutTime_DMSM" 2500;
BA_DEF_DEF_ "GenSigTimeoutTime_DTCM" 2500;
BA_DEF_DEF_ "GenSigTimeoutTime_ECM" 2500;
BA_DEF_DEF_ "GenSigTimeoutTime_EVCU2" 2500;
BA_DEF_DEF_ "GenSigTimeoutTime_GNMM" 2500;
BA_DEF_DEF_ "GenSigTimeoutTime_HCP" 2500;
BA_DEF_DEF_ "GenSigTimeoutTime_IPC" 2500;
BA_DEF_DEF_ "GenSigTimeoutTime_RFHM" 2500;
BA_DEF_DEF_ "GenSigTimeoutTime_SGW" 2500;
BA_DEF_DEF_ "GenSigTimeoutTime_TCM" 2500;
BA_ "Type" BO_ 1474 3;
BA_ "GenMsgSendType" BO_ 1474 0;
BA_ "GenMsgNrOfRepetition" BO_ 1474 2;
BA_ "GenMsgILSupport" BO_ 1474 1;
BA_ "GenMsgCycleTimeFast" BO_ 1474 20;
BA_ "GenMsgCycleTime" BO_ 1474 1000;
BA_ "GenMsgDelayTime" BO_ 1474 20;
BA_ "CANFD_BRS" BO_ 1474 1;
BA_ "Type" BO_ 753 1;
BA_ "GenMsgSendType" BO_ 753 0;
BA_ "GenMsgILSupport" BO_ 753 1;
BA_ "GenMsgCycleTime" BO_ 753 50;
BA_ "CANFD_BRS" BO_ 753 1;
BA_ "Type" BO_ 1062 1;
BA_ "GenMsgSendType" BO_ 1062 0;
BA_ "GenMsgILSupport" BO_ 1062 1;
BA_ "GenMsgCycleTime" BO_ 1062 100;
BA_ "CANFD_BRS" BO_ 1062 1;
BA_ "Type" BO_ 125 8;
BA_ "GenMsgNrOfRepetition" BO_ 125 2;
BA_ "GenMsgILSupport" BO_ 125 1;
BA_ "GenMsgCycleTimeFast" BO_ 125 20;
BA_ "GenMsgDelayTime" BO_ 125 20;
BA_ "CANFD_BRS" BO_ 125 1;
BA_ "Type" BO_ 2654486550 8;
BA_ "NmMessage" BO_ 2654486550 1;
BA_ "NmAsrMessage" BO_ 2654486550 1;
BA_ "VFrameFormat" BO_ 2654486550 15;
BA_ "CANFD_BRS" BO_ 2654486550 1;
BA_ "Type" BO_ 2654486528 8;
BA_ "NmMessage" BO_ 2654486528 1;
BA_ "NmAsrMessage" BO_ 2654486528 1;
BA_ "VFrameFormat" BO_ 2654486528 15;
BA_ "CANFD_BRS" BO_ 2654486528 1;
BA_ "Type" BO_ 2654486534 8;
BA_ "NmMessage" BO_ 2654486534 1;
BA_ "NmAsrMessage" BO_ 2654486534 1;
BA_ "VFrameFormat" BO_ 2654486534 15;
BA_ "CANFD_BRS" BO_ 2654486534 1;
BA_ "Type" BO_ 2654486669 8;
BA_ "NmMessage" BO_ 2654486669 1;
BA_ "NmAsrMessage" BO_ 2654486669 1;
BA_ "VFrameFormat" BO_ 2654486669 15;
BA_ "CANFD_BRS" BO_ 2654486669 1;
BA_ "Type" BO_ 2654486595 8;
BA_ "NmMessage" BO_ 2654486595 1;
BA_ "NmAsrMessage" BO_ 2654486595 1;
BA_ "VFrameFormat" BO_ 2654486595 15;
BA_ "CANFD_BRS" BO_ 2654486595 1;
BA_ "Type" BO_ 2654486529 8;
BA_ "NmMessage" BO_ 2654486529 1;
BA_ "NmAsrMessage" BO_ 2654486529 1;
BA_ "VFrameFormat" BO_ 2654486529 15;
BA_ "CANFD_BRS" BO_ 2654486529 1;
BA_ "Type" BO_ 2654486592 8;
BA_ "NmMessage" BO_ 2654486592 1;
BA_ "NmAsrMessage" BO_ 2654486592 1;
BA_ "VFrameFormat" BO_ 2654486592 15;
BA_ "CANFD_BRS" BO_ 2654486592 1;
BA_ "Type" BO_ 2654486672 8;
BA_ "NmMessage" BO_ 2654486672 1;
BA_ "NmAsrMessage" BO_ 2654486672 1;
BA_ "VFrameFormat" BO_ 2654486672 15;
BA_ "CANFD_BRS" BO_ 2654486672 1;
BA_ "Type" BO_ 2654486626 8;
BA_ "NmMessage" BO_ 2654486626 1;
BA_ "NmAsrMessage" BO_ 2654486626 1;
BA_ "VFrameFormat" BO_ 2654486626 15;
BA_ "CANFD_BRS" BO_ 2654486626 1;
BA_ "Type" BO_ 2654486531 8;
BA_ "NmMessage" BO_ 2654486531 1;
BA_ "NmAsrMessage" BO_ 2654486531 1;
BA_ "VFrameFormat" BO_ 2654486531 15;
BA_ "CANFD_BRS" BO_ 2654486531 1;
BA_ "Type" BO_ 2654486593 8;
BA_ "NmMessage" BO_ 2654486593 1;
BA_ "NmAsrMessage" BO_ 2654486593 1;
BA_ "VFrameFormat" BO_ 2654486593 15;
BA_ "CANFD_BRS" BO_ 2654486593 1;
BA_ "Type" BO_ 2654486640 8;
BA_ "NmMessage" BO_ 2654486640 1;
BA_ "NmAsrMessage" BO_ 2654486640 1;
BA_ "VFrameFormat" BO_ 2654486640 15;
BA_ "CANFD_BRS" BO_ 2654486640 1;
BA_ "Type" BO_ 2654486539 8;
BA_ "NmMessage" BO_ 2654486539 1;
BA_ "NmAsrMessage" BO_ 2654486539 1;
BA_ "VFrameFormat" BO_ 2654486539 15;
BA_ "CANFD_BRS" BO_ 2654486539 1;
BA_ "GenSigSendType" SG_ 1474 AUX1_HLEnbl 3;
BA_ "GenSigTimeoutTime_AGSM" SG_ 1474 AUX1_HLEnbl 0;
BA_ "GenSigTimeoutTime_BSM" SG_ 1474 AUX1_HLEnbl 0;
BA_ "GenSigTimeoutTime_CADM" SG_ 1474 AUX1_HLEnbl 0;
BA_ "GenSigTimeoutTime_DMSM" SG_ 1474 AUX1_HLEnbl 0;
BA_ "GenSigTimeoutTime_DTCM" SG_ 1474 AUX1_HLEnbl 0;
BA_ "GenSigTimeoutTime_ECM" SG_ 1474 AUX1_HLEnbl 0;
BA_ "GenSigTimeoutTime_EVCU2" SG_ 1474 AUX1_HLEnbl 0;
BA_ "GenSigTimeoutTime_GNMM" SG_ 1474 AUX1_HLEnbl 0;
BA_ "GenSigTimeoutTime_HCP" SG_ 1474 AUX1_HLEnbl 0;
BA_ "GenSigTimeoutTime_IPC" SG_ 1474 AUX1_HLEnbl 0;
BA_ "GenSigTimeoutTime_RFHM" SG_ 1474 AUX1_HLEnbl 0;
BA_ "GenSigTimeoutTime_TCM" SG_ 1474 AUX1_HLEnbl 0;
BA_ "GenSigSendType" SG_ 1474 AUX1_PWRMD 3;
BA_ "GenSigTimeoutTime_AGSM" SG_ 1474 AUX1_PWRMD 0;
BA_ "GenSigTimeoutTime_BSM" SG_ 1474 AUX1_PWRMD 0;
BA_ "GenSigTimeoutTime_CADM" SG_ 1474 AUX1_PWRMD 0;
BA_ "GenSigTimeoutTime_DMSM" SG_ 1474 AUX1_PWRMD 0;
BA_ "GenSigTimeoutTime_DTCM" SG_ 1474 AUX1_PWRMD 0;
BA_ "GenSigTimeoutTime_ECM" SG_ 1474 AUX1_PWRMD 0;
BA_ "GenSigTimeoutTime_EVCU2" SG_ 1474 AUX1_PWRMD 0;
BA_ "GenSigTimeoutTime_GNMM" SG_ 1474 AUX1_PWRMD 0;
BA_ "GenSigTimeoutTime_HCP" SG_ 1474 AUX1_PWRMD 0;
BA_ "GenSigTimeoutTime_IPC" SG_ 1474 AUX1_PWRMD 0;
BA_ "GenSigTimeoutTime_RFHM" SG_ 1474 AUX1_PWRMD 0;
BA_ "GenSigTimeoutTime_TCM" SG_ 1474 AUX1_PWRMD 0;
BA_ "GenSigSendType" SG_ 1474 AUX1_TYPE 3;
BA_ "GenSigTimeoutTime_AGSM" SG_ 1474 AUX1_TYPE 0;
BA_ "GenSigTimeoutTime_BSM" SG_ 1474 AUX1_TYPE 0;
BA_ "GenSigTimeoutTime_CADM" SG_ 1474 AUX1_TYPE 0;
BA_ "GenSigTimeoutTime_DMSM" SG_ 1474 AUX1_TYPE 0;
BA_ "GenSigTimeoutTime_DTCM" SG_ 1474 AUX1_TYPE 0;
BA_ "GenSigTimeoutTime_ECM" SG_ 1474 AUX1_TYPE 0;
BA_ "GenSigTimeoutTime_EVCU2" SG_ 1474 AUX1_TYPE 0;
BA_ "GenSigTimeoutTime_GNMM" SG_ 1474 AUX1_TYPE 0;
BA_ "GenSigTimeoutTime_HCP" SG_ 1474 AUX1_TYPE 0;
BA_ "GenSigTimeoutTime_IPC" SG_ 1474 AUX1_TYPE 0;
BA_ "GenSigTimeoutTime_RFHM" SG_ 1474 AUX1_TYPE 0;
BA_ "GenSigTimeoutTime_TCM" SG_ 1474 AUX1_TYPE 0;
BA_ "GenSigSendType" SG_ 1474 AUX2_HLEnbl 3;
BA_ "GenSigTimeoutTime_AGSM" SG_ 1474 AUX2_HLEnbl 0;
BA_ "GenSigTimeoutTime_BSM" SG_ 1474 AUX2_HLEnbl 0;
BA_ "GenSigTimeoutTime_CADM" SG_ 1474 AUX2_HLEnbl 0;
BA_ "GenSigTimeoutTime_DMSM" SG_ 1474 AUX2_HLEnbl 0;
BA_ "GenSigTimeoutTime_DTCM" SG_ 1474 AUX2_HLEnbl 0;
BA_ "GenSigTimeoutTime_ECM" SG_ 1474 AUX2_HLEnbl 0;
BA_ "GenSigTimeoutTime_EVCU2" SG_ 1474 AUX2_HLEnbl 0;
BA_ "GenSigTimeoutTime_GNMM" SG_ 1474 AUX2_HLEnbl 0;
BA_ "GenSigTimeoutTime_HCP" SG_ 1474 AUX2_HLEnbl 0;
BA_ "GenSigTimeoutTime_IPC" SG_ 1474 AUX2_HLEnbl 0;
BA_ "GenSigTimeoutTime_RFHM" SG_ 1474 AUX2_HLEnbl 0;
BA_ "GenSigTimeoutTime_TCM" SG_ 1474 AUX2_HLEnbl 0;
BA_ "GenSigSendType" SG_ 1474 AUX2_PWRMD 3;
BA_ "GenSigTimeoutTime_AGSM" SG_ 1474 AUX2_PWRMD 0;
BA_ "GenSigTimeoutTime_BSM" SG_ 1474 AUX2_PWRMD 0;
BA_ "GenSigTimeoutTime_CADM" SG_ 1474 AUX2_PWRMD 0;
BA_ "GenSigTimeoutTime_DMSM" SG_ 1474 AUX2_PWRMD 0;
BA_ "GenSigTimeoutTime_DTCM" SG_ 1474 AUX2_PWRMD 0;
BA_ "GenSigTimeoutTime_ECM" SG_ 1474 AUX2_PWRMD 0;
BA_ "GenSigTimeoutTime_EVCU2" SG_ 1474 AUX2_PWRMD 0;
BA_ "GenSigTimeoutTime_GNMM" SG_ 1474 AUX2_PWRMD 0;
BA_ "GenSigTimeoutTime_HCP" SG_ 1474 AUX2_PWRMD 0;
BA_ "GenSigTimeoutTime_IPC" SG_ 1474 AUX2_PWRMD 0;
BA_ "GenSigTimeoutTime_RFHM" SG_ 1474 AUX2_PWRMD 0;
BA_ "GenSigTimeoutTime_TCM" SG_ 1474 AUX2_PWRMD 0;
BA_ "GenSigSendType" SG_ 1474 AUX2_TYPE 3;
BA_ "GenSigTimeoutTime_AGSM" SG_ 1474 AUX2_TYPE 0;
BA_ "GenSigTimeoutTime_BSM" SG_ 1474 AUX2_TYPE 0;
BA_ "GenSigTimeoutTime_CADM" SG_ 1474 AUX2_TYPE 0;
BA_ "GenSigTimeoutTime_DMSM" SG_ 1474 AUX2_TYPE 0;
BA_ "GenSigTimeoutTime_DTCM" SG_ 1474 AUX2_TYPE 0;
BA_ "GenSigTimeoutTime_ECM" SG_ 1474 AUX2_TYPE 0;
BA_ "GenSigTimeoutTime_EVCU2" SG_ 1474 AUX2_TYPE 0;
BA_ "GenSigTimeoutTime_GNMM" SG_ 1474 AUX2_TYPE 0;
BA_ "GenSigTimeoutTime_HCP" SG_ 1474 AUX2_TYPE 0;
BA_ "GenSigTimeoutTime_IPC" SG_ 1474 AUX2_TYPE 0;
BA_ "GenSigTimeoutTime_RFHM" SG_ 1474 AUX2_TYPE 0;
BA_ "GenSigTimeoutTime_TCM" SG_ 1474 AUX2_TYPE 0;
BA_ "GenSigSendType" SG_ 1474 AUX3_HLEnbl 3;
BA_ "GenSigTimeoutTime_AGSM" SG_ 1474 AUX3_HLEnbl 0;
BA_ "GenSigTimeoutTime_BSM" SG_ 1474 AUX3_HLEnbl 0;
BA_ "GenSigTimeoutTime_CADM" SG_ 1474 AUX3_HLEnbl 0;
BA_ "GenSigTimeoutTime_DMSM" SG_ 1474 AUX3_HLEnbl 0;
BA_ "GenSigTimeoutTime_DTCM" SG_ 1474 AUX3_HLEnbl 0;
BA_ "GenSigTimeoutTime_ECM" SG_ 1474 AUX3_HLEnbl 0;
BA_ "GenSigTimeoutTime_EVCU2" SG_ 1474 AUX3_HLEnbl 0;
BA_ "GenSigTimeoutTime_GNMM" SG_ 1474 AUX3_HLEnbl 0;
BA_ "GenSigTimeoutTime_HCP" SG_ 1474 AUX3_HLEnbl 0;
BA_ "GenSigTimeoutTime_IPC" SG_ 1474 AUX3_HLEnbl 0;
BA_ "GenSigTimeoutTime_RFHM" SG_ 1474 AUX3_HLEnbl 0;
BA_ "GenSigTimeoutTime_TCM" SG_ 1474 AUX3_HLEnbl 0;
BA_ "GenSigSendType" SG_ 1474 AUX3_PWRMD 3;
BA_ "GenSigTimeoutTime_AGSM" SG_ 1474 AUX3_PWRMD 0;
BA_ "GenSigTimeoutTime_BSM" SG_ 1474 AUX3_PWRMD 0;
BA_ "GenSigTimeoutTime_CADM" SG_ 1474 AUX3_PWRMD 0;
BA_ "GenSigTimeoutTime_DMSM" SG_ 1474 AUX3_PWRMD 0;
BA_ "GenSigTimeoutTime_DTCM" SG_ 1474 AUX3_PWRMD 0;
BA_ "GenSigTimeoutTime_ECM" SG_ 1474 AUX3_PWRMD 0;
BA_ "GenSigTimeoutTime_EVCU2" SG_ 1474 AUX3_PWRMD 0;
BA_ "GenSigTimeoutTime_GNMM" SG_ 1474 AUX3_PWRMD 0;
BA_ "GenSigTimeoutTime_HCP" SG_ 1474 AUX3_PWRMD 0;
BA_ "GenSigTimeoutTime_IPC" SG_ 1474 AUX3_PWRMD 0;
BA_ "GenSigTimeoutTime_RFHM" SG_ 1474 AUX3_PWRMD 0;
BA_ "GenSigTimeoutTime_TCM" SG_ 1474 AUX3_PWRMD 0;
BA_ "GenSigSendType" SG_ 1474 AUX3_TYPE 3;
BA_ "GenSigTimeoutTime_AGSM" SG_ 1474 AUX3_TYPE 0;
BA_ "GenSigTimeoutTime_BSM" SG_ 1474 AUX3_TYPE 0;
BA_ "GenSigTimeoutTime_CADM" SG_ 1474 AUX3_TYPE 0;
BA_ "GenSigTimeoutTime_DMSM" SG_ 1474 AUX3_TYPE 0;
BA_ "GenSigTimeoutTime_DTCM" SG_ 1474 AUX3_TYPE 0;
BA_ "GenSigTimeoutTime_ECM" SG_ 1474 AUX3_TYPE 0;
BA_ "GenSigTimeoutTime_EVCU2" SG_ 1474 AUX3_TYPE 0;
BA_ "GenSigTimeoutTime_GNMM" SG_ 1474 AUX3_TYPE 0;
BA_ "GenSigTimeoutTime_HCP" SG_ 1474 AUX3_TYPE 0;
BA_ "GenSigTimeoutTime_IPC" SG_ 1474 AUX3_TYPE 0;
BA_ "GenSigTimeoutTime_RFHM" SG_ 1474 AUX3_TYPE 0;
BA_ "GenSigTimeoutTime_TCM" SG_ 1474 AUX3_TYPE 0;
BA_ "GenSigSendType" SG_ 1474 AUX4_HLEnbl 3;
BA_ "GenSigTimeoutTime_AGSM" SG_ 1474 AUX4_HLEnbl 0;
BA_ "GenSigTimeoutTime_BSM" SG_ 1474 AUX4_HLEnbl 0;
BA_ "GenSigTimeoutTime_CADM" SG_ 1474 AUX4_HLEnbl 0;
BA_ "GenSigTimeoutTime_DMSM" SG_ 1474 AUX4_HLEnbl 0;
BA_ "GenSigTimeoutTime_DTCM" SG_ 1474 AUX4_HLEnbl 0;
BA_ "GenSigTimeoutTime_ECM" SG_ 1474 AUX4_HLEnbl 0;
BA_ "GenSigTimeoutTime_EVCU2" SG_ 1474 AUX4_HLEnbl 0;
BA_ "GenSigTimeoutTime_GNMM" SG_ 1474 AUX4_HLEnbl 0;
BA_ "GenSigTimeoutTime_HCP" SG_ 1474 AUX4_HLEnbl 0;
BA_ "GenSigTimeoutTime_IPC" SG_ 1474 AUX4_HLEnbl 0;
BA_ "GenSigTimeoutTime_RFHM" SG_ 1474 AUX4_HLEnbl 0;
BA_ "GenSigTimeoutTime_TCM" SG_ 1474 AUX4_HLEnbl 0;
BA_ "GenSigSendType" SG_ 1474 AUX4_PWRMD 3;
BA_ "GenSigTimeoutTime_AGSM" SG_ 1474 AUX4_PWRMD 0;
BA_ "GenSigTimeoutTime_BSM" SG_ 1474 AUX4_PWRMD 0;
BA_ "GenSigTimeoutTime_CADM" SG_ 1474 AUX4_PWRMD 0;
BA_ "GenSigTimeoutTime_DMSM" SG_ 1474 AUX4_PWRMD 0;
BA_ "GenSigTimeoutTime_DTCM" SG_ 1474 AUX4_PWRMD 0;
BA_ "GenSigTimeoutTime_ECM" SG_ 1474 AUX4_PWRMD 0;
BA_ "GenSigTimeoutTime_EVCU2" SG_ 1474 AUX4_PWRMD 0;
BA_ "GenSigTimeoutTime_GNMM" SG_ 1474 AUX4_PWRMD 0;
BA_ "GenSigTimeoutTime_HCP" SG_ 1474 AUX4_PWRMD 0;
BA_ "GenSigTimeoutTime_IPC" SG_ 1474 AUX4_PWRMD 0;
BA_ "GenSigTimeoutTime_RFHM" SG_ 1474 AUX4_PWRMD 0;
BA_ "GenSigTimeoutTime_TCM" SG_ 1474 AUX4_PWRMD 0;
BA_ "GenSigSendType" SG_ 1474 AUX4_TYPE 3;
BA_ "GenSigTimeoutTime_AGSM" SG_ 1474 AUX4_TYPE 0;
BA_ "GenSigTimeoutTime_BSM" SG_ 1474 AUX4_TYPE 0;
BA_ "GenSigTimeoutTime_CADM" SG_ 1474 AUX4_TYPE 0;
BA_ "GenSigTimeoutTime_DMSM" SG_ 1474 AUX4_TYPE 0;
BA_ "GenSigTimeoutTime_DTCM" SG_ 1474 AUX4_TYPE 0;
BA_ "GenSigTimeoutTime_ECM" SG_ 1474 AUX4_TYPE 0;
BA_ "GenSigTimeoutTime_EVCU2" SG_ 1474 AUX4_TYPE 0;
BA_ "GenSigTimeoutTime_GNMM" SG_ 1474 AUX4_TYPE 0;
BA_ "GenSigTimeoutTime_HCP" SG_ 1474 AUX4_TYPE 0;
BA_ "GenSigTimeoutTime_IPC" SG_ 1474 AUX4_TYPE 0;
BA_ "GenSigTimeoutTime_RFHM" SG_ 1474 AUX4_TYPE 0;
BA_ "GenSigTimeoutTime_TCM" SG_ 1474 AUX4_TYPE 0;
BA_ "GenSigSendType" SG_ 1474 AUX5_HLEnbl 4;
BA_ "GenSigTimeoutTime_AGSM" SG_ 1474 AUX5_HLEnbl 0;
BA_ "GenSigTimeoutTime_BSM" SG_ 1474 AUX5_HLEnbl 0;
BA_ "GenSigTimeoutTime_CADM" SG_ 1474 AUX5_HLEnbl 0;
BA_ "GenSigTimeoutTime_DMSM" SG_ 1474 AUX5_HLEnbl 0;
BA_ "GenSigTimeoutTime_DTCM" SG_ 1474 AUX5_HLEnbl 0;
BA_ "GenSigTimeoutTime_ECM" SG_ 1474 AUX5_HLEnbl 0;
BA_ "GenSigTimeoutTime_EVCU2" SG_ 1474 AUX5_HLEnbl 0;
BA_ "GenSigTimeoutTime_GNMM" SG_ 1474 AUX5_HLEnbl 0;
BA_ "GenSigTimeoutTime_HCP" SG_ 1474 AUX5_HLEnbl 0;
BA_ "GenSigTimeoutTime_IPC" SG_ 1474 AUX5_HLEnbl 0;
BA_ "GenSigTimeoutTime_RFHM" SG_ 1474 AUX5_HLEnbl 0;
BA_ "GenSigTimeoutTime_TCM" SG_ 1474 AUX5_HLEnbl 0;
BA_ "GenSigStartValue" SG_ 1474 AUX5_PWRMD 1;
BA_ "GenSigSendType" SG_ 1474 AUX5_PWRMD 4;
BA_ "GenSigTimeoutTime_AGSM" SG_ 1474 AUX5_PWRMD 0;
BA_ "GenSigTimeoutTime_BSM" SG_ 1474 AUX5_PWRMD 0;
BA_ "GenSigTimeoutTime_CADM" SG_ 1474 AUX5_PWRMD 0;
BA_ "GenSigTimeoutTime_DMSM" SG_ 1474 AUX5_PWRMD 0;
BA_ "GenSigTimeoutTime_DTCM" SG_ 1474 AUX5_PWRMD 0;
BA_ "GenSigTimeoutTime_ECM" SG_ 1474 AUX5_PWRMD 0;
BA_ "GenSigTimeoutTime_EVCU2" SG_ 1474 AUX5_PWRMD 0;
BA_ "GenSigTimeoutTime_GNMM" SG_ 1474 AUX5_PWRMD 0;
BA_ "GenSigTimeoutTime_HCP" SG_ 1474 AUX5_PWRMD 0;
BA_ "GenSigTimeoutTime_IPC" SG_ 1474 AUX5_PWRMD 0;
BA_ "GenSigTimeoutTime_RFHM" SG_ 1474 AUX5_PWRMD 0;
BA_ "GenSigTimeoutTime_TCM" SG_ 1474 AUX5_PWRMD 0;
BA_ "GenSigStartValue" SG_ 1474 AUX5_TYPE 1;
BA_ "GenSigSendType" SG_ 1474 AUX5_TYPE 4;
BA_ "GenSigTimeoutTime_AGSM" SG_ 1474 AUX5_TYPE 0;
BA_ "GenSigTimeoutTime_BSM" SG_ 1474 AUX5_TYPE 0;
BA_ "GenSigTimeoutTime_CADM" SG_ 1474 AUX5_TYPE 0;
BA_ "GenSigTimeoutTime_DMSM" SG_ 1474 AUX5_TYPE 0;
BA_ "GenSigTimeoutTime_DTCM" SG_ 1474 AUX5_TYPE 0;
BA_ "GenSigTimeoutTime_ECM" SG_ 1474 AUX5_TYPE 0;
BA_ "GenSigTimeoutTime_EVCU2" SG_ 1474 AUX5_TYPE 0;
BA_ "GenSigTimeoutTime_GNMM" SG_ 1474 AUX5_TYPE 0;
BA_ "GenSigTimeoutTime_HCP" SG_ 1474 AUX5_TYPE 0;
BA_ "GenSigTimeoutTime_IPC" SG_ 1474 AUX5_TYPE 0;
BA_ "GenSigTimeoutTime_RFHM" SG_ 1474 AUX5_TYPE 0;
BA_ "GenSigTimeoutTime_TCM" SG_ 1474 AUX5_TYPE 0;
BA_ "GenSigSendType" SG_ 1474 AUX6_HLEnbl 4;
BA_ "GenSigTimeoutTime_AGSM" SG_ 1474 AUX6_HLEnbl 0;
BA_ "GenSigTimeoutTime_BSM" SG_ 1474 AUX6_HLEnbl 0;
BA_ "GenSigTimeoutTime_CADM" SG_ 1474 AUX6_HLEnbl 0;
BA_ "GenSigTimeoutTime_DMSM" SG_ 1474 AUX6_HLEnbl 0;
BA_ "GenSigTimeoutTime_DTCM" SG_ 1474 AUX6_HLEnbl 0;
BA_ "GenSigTimeoutTime_ECM" SG_ 1474 AUX6_HLEnbl 0;
BA_ "GenSigTimeoutTime_EVCU2" SG_ 1474 AUX6_HLEnbl 0;
BA_ "GenSigTimeoutTime_GNMM" SG_ 1474 AUX6_HLEnbl 0;
BA_ "GenSigTimeoutTime_HCP" SG_ 1474 AUX6_HLEnbl 0;
BA_ "GenSigTimeoutTime_IPC" SG_ 1474 AUX6_HLEnbl 0;
BA_ "GenSigTimeoutTime_RFHM" SG_ 1474 AUX6_HLEnbl 0;
BA_ "GenSigTimeoutTime_TCM" SG_ 1474 AUX6_HLEnbl 0;
BA_ "GenSigStartValue" SG_ 1474 AUX6_PWRMD 1;
BA_ "GenSigSendType" SG_ 1474 AUX6_PWRMD 4;
BA_ "GenSigTimeoutTime_AGSM" SG_ 1474 AUX6_PWRMD 0;
BA_ "GenSigTimeoutTime_BSM" SG_ 1474 AUX6_PWRMD 0;
BA_ "GenSigTimeoutTime_CADM" SG_ 1474 AUX6_PWRMD 0;
BA_ "GenSigTimeoutTime_DMSM" SG_ 1474 AUX6_PWRMD 0;
BA_ "GenSigTimeoutTime_DTCM" SG_ 1474 AUX6_PWRMD 0;
BA_ "GenSigTimeoutTime_ECM" SG_ 1474 AUX6_PWRMD 0;
BA_ "GenSigTimeoutTime_EVCU2" SG_ 1474 AUX6_PWRMD 0;
BA_ "GenSigTimeoutTime_GNMM" SG_ 1474 AUX6_PWRMD 0;
BA_ "GenSigTimeoutTime_HCP" SG_ 1474 AUX6_PWRMD 0;
BA_ "GenSigTimeoutTime_IPC" SG_ 1474 AUX6_PWRMD 0;
BA_ "GenSigTimeoutTime_RFHM" SG_ 1474 AUX6_PWRMD 0;
BA_ "GenSigTimeoutTime_TCM" SG_ 1474 AUX6_PWRMD 0;
BA_ "GenSigStartValue" SG_ 1474 AUX6_TYPE 1;
BA_ "GenSigSendType" SG_ 1474 AUX6_TYPE 4;
BA_ "GenSigTimeoutTime_AGSM" SG_ 1474 AUX6_TYPE 0;
BA_ "GenSigTimeoutTime_BSM" SG_ 1474 AUX6_TYPE 0;
BA_ "GenSigTimeoutTime_CADM" SG_ 1474 AUX6_TYPE 0;
BA_ "GenSigTimeoutTime_DMSM" SG_ 1474 AUX6_TYPE 0;
BA_ "GenSigTimeoutTime_DTCM" SG_ 1474 AUX6_TYPE 0;
BA_ "GenSigTimeoutTime_ECM" SG_ 1474 AUX6_TYPE 0;
BA_ "GenSigTimeoutTime_EVCU2" SG_ 1474 AUX6_TYPE 0;
BA_ "GenSigTimeoutTime_GNMM" SG_ 1474 AUX6_TYPE 0;
BA_ "GenSigTimeoutTime_HCP" SG_ 1474 AUX6_TYPE 0;
BA_ "GenSigTimeoutTime_IPC" SG_ 1474 AUX6_TYPE 0;
BA_ "GenSigTimeoutTime_RFHM" SG_ 1474 AUX6_TYPE 0;
BA_ "GenSigTimeoutTime_TCM" SG_ 1474 AUX6_TYPE 0;
BA_ "GenSigTimeoutTime_AGSM" SG_ 1474 CRC_IPCVS2 0;
BA_ "GenSigTimeoutTime_BCM" SG_ 1474 CRC_IPCVS2 0;
BA_ "GenSigTimeoutTime_BSM" SG_ 1474 CRC_IPCVS2 0;
BA_ "GenSigTimeoutTime_CADM" SG_ 1474 CRC_IPCVS2 0;
BA_ "GenSigTimeoutTime_DMSM" SG_ 1474 CRC_IPCVS2 0;
BA_ "GenSigTimeoutTime_DTCM" SG_ 1474 CRC_IPCVS2 0;
BA_ "GenSigTimeoutTime_ECM" SG_ 1474 CRC_IPCVS2 0;
BA_ "GenSigTimeoutTime_GNMM" SG_ 1474 CRC_IPCVS2 0;
BA_ "GenSigTimeoutTime_HCP" SG_ 1474 CRC_IPCVS2 0;
BA_ "GenSigTimeoutTime_IPC" SG_ 1474 CRC_IPCVS2 0;
BA_ "GenSigTimeoutTime_RFHM" SG_ 1474 CRC_IPCVS2 0;
BA_ "GenSigTimeoutTime_SGW" SG_ 1474 CRC_IPCVS2 0;
BA_ "GenSigTimeoutTime_TCM" SG_ 1474 CRC_IPCVS2 0;
BA_ "GenSigSendType" SG_ 1474 Default_Ride_Height 4;
BA_ "GenSigTimeoutTime_AGSM" SG_ 1474 Default_Ride_Height 0;
BA_ "GenSigTimeoutTime_BSM" SG_ 1474 Default_Ride_Height 0;
BA_ "GenSigTimeoutTime_CADM" SG_ 1474 Default_Ride_Height 0;
BA_ "GenSigTimeoutTime_DMSM" SG_ 1474 Default_Ride_Height 0;
BA_ "GenSigTimeoutTime_DTCM" SG_ 1474 Default_Ride_Height 0;
BA_ "GenSigTimeoutTime_ECM" SG_ 1474 Default_Ride_Height 0;
BA_ "GenSigTimeoutTime_EVCU2" SG_ 1474 Default_Ride_Height 0;
BA_ "GenSigTimeoutTime_GNMM" SG_ 1474 Default_Ride_Height 0;
BA_ "GenSigTimeoutTime_HCP" SG_ 1474 Default_Ride_Height 0;
BA_ "GenSigTimeoutTime_IPC" SG_ 1474 Default_Ride_Height 0;
BA_ "GenSigTimeoutTime_RFHM" SG_ 1474 Default_Ride_Height 0;
BA_ "GenSigTimeoutTime_TCM" SG_ 1474 Default_Ride_Height 0;
BA_ "GenSigStartValue" SG_ 1474 Display_Synch 1;
BA_ "GenSigSendType" SG_ 1474 Display_Synch 4;
BA_ "GenSigTimeoutTime_AGSM" SG_ 1474 Display_Synch 0;
BA_ "GenSigTimeoutTime_BCM" SG_ 1474 Display_Synch 0;
BA_ "GenSigTimeoutTime_BSM" SG_ 1474 Display_Synch 0;
BA_ "GenSigTimeoutTime_CADM" SG_ 1474 Display_Synch 0;
BA_ "GenSigTimeoutTime_DMSM" SG_ 1474 Display_Synch 0;
BA_ "GenSigTimeoutTime_DTCM" SG_ 1474 Display_Synch 0;
BA_ "GenSigTimeoutTime_ECM" SG_ 1474 Display_Synch 0;
BA_ "GenSigTimeoutTime_EVCU2" SG_ 1474 Display_Synch 0;
BA_ "GenSigTimeoutTime_GNMM" SG_ 1474 Display_Synch 0;
BA_ "GenSigTimeoutTime_HCP" SG_ 1474 Display_Synch 0;
BA_ "GenSigTimeoutTime_IPC" SG_ 1474 Display_Synch 0;
BA_ "GenSigTimeoutTime_RFHM" SG_ 1474 Display_Synch 0;
BA_ "GenSigTimeoutTime_TCM" SG_ 1474 Display_Synch 0;
BA_ "GenSigStartValue" SG_ 1474 FOA_Alert_Type 1;
BA_ "GenSigSendType" SG_ 1474 FOA_Alert_Type 3;
BA_ "GenSigTimeoutTime_AGSM" SG_ 1474 FOA_Alert_Type 0;
BA_ "GenSigTimeoutTime_BSM" SG_ 1474 FOA_Alert_Type 0;
BA_ "GenSigTimeoutTime_CADM" SG_ 1474 FOA_Alert_Type 0;
BA_ "GenSigTimeoutTime_DMSM" SG_ 1474 FOA_Alert_Type 0;
BA_ "GenSigTimeoutTime_DTCM" SG_ 1474 FOA_Alert_Type 0;
BA_ "GenSigTimeoutTime_ECM" SG_ 1474 FOA_Alert_Type 0;
BA_ "GenSigTimeoutTime_EVCU2" SG_ 1474 FOA_Alert_Type 0;
BA_ "GenSigTimeoutTime_GNMM" SG_ 1474 FOA_Alert_Type 0;
BA_ "GenSigTimeoutTime_HCP" SG_ 1474 FOA_Alert_Type 0;
BA_ "GenSigTimeoutTime_IPC" SG_ 1474 FOA_Alert_Type 0;
BA_ "GenSigTimeoutTime_RFHM" SG_ 1474 FOA_Alert_Type 0;
BA_ "GenSigTimeoutTime_TCM" SG_ 1474 FOA_Alert_Type 0;
BA_ "GenSigSendType" SG_ 1474 Fuel_Saver_Display 4;
BA_ "GenSigTimeoutTime_AGSM" SG_ 1474 Fuel_Saver_Display 0;
BA_ "GenSigTimeoutTime_BSM" SG_ 1474 Fuel_Saver_Display 0;
BA_ "GenSigTimeoutTime_CADM" SG_ 1474 Fuel_Saver_Display 0;
BA_ "GenSigTimeoutTime_DMSM" SG_ 1474 Fuel_Saver_Display 0;
BA_ "GenSigTimeoutTime_DTCM" SG_ 1474 Fuel_Saver_Display 0;
BA_ "GenSigTimeoutTime_ECM" SG_ 1474 Fuel_Saver_Display 0;
BA_ "GenSigTimeoutTime_EVCU2" SG_ 1474 Fuel_Saver_Display 0;
BA_ "GenSigTimeoutTime_GNMM" SG_ 1474 Fuel_Saver_Display 0;
BA_ "GenSigTimeoutTime_HCP" SG_ 1474 Fuel_Saver_Display 0;
BA_ "GenSigTimeoutTime_IPC" SG_ 1474 Fuel_Saver_Display 0;
BA_ "GenSigTimeoutTime_RFHM" SG_ 1474 Fuel_Saver_Display 0;
BA_ "GenSigTimeoutTime_TCM" SG_ 1474 Fuel_Saver_Display 0;
BA_ "GenSigTimeoutTime_AGSM" SG_ 1474 MessageCounter_IPCVS2 0;
BA_ "GenSigTimeoutTime_BCM" SG_ 1474 MessageCounter_IPCVS2 0;
BA_ "GenSigTimeoutTime_BSM" SG_ 1474 MessageCounter_IPCVS2 0;
BA_ "GenSigTimeoutTime_CADM" SG_ 1474 MessageCounter_IPCVS2 0;
BA_ "GenSigTimeoutTime_DMSM" SG_ 1474 MessageCounter_IPCVS2 0;
BA_ "GenSigTimeoutTime_DTCM" SG_ 1474 MessageCounter_IPCVS2 0;
BA_ "GenSigTimeoutTime_ECM" SG_ 1474 MessageCounter_IPCVS2 0;
BA_ "GenSigTimeoutTime_GNMM" SG_ 1474 MessageCounter_IPCVS2 0;
BA_ "GenSigTimeoutTime_HCP" SG_ 1474 MessageCounter_IPCVS2 0;
BA_ "GenSigTimeoutTime_IPC" SG_ 1474 MessageCounter_IPCVS2 0;
BA_ "GenSigTimeoutTime_RFHM" SG_ 1474 MessageCounter_IPCVS2 0;
BA_ "GenSigTimeoutTime_SGW" SG_ 1474 MessageCounter_IPCVS2 0;
BA_ "GenSigTimeoutTime_TCM" SG_ 1474 MessageCounter_IPCVS2 0;
BA_ "GenSigSendType" SG_ 1474 ParkSenseSignalView 4;
BA_ "GenSigTimeoutTime_AGSM" SG_ 1474 ParkSenseSignalView 0;
BA_ "GenSigTimeoutTime_BSM" SG_ 1474 ParkSenseSignalView 0;
BA_ "GenSigTimeoutTime_CADM" SG_ 1474 ParkSenseSignalView 0;
BA_ "GenSigTimeoutTime_DMSM" SG_ 1474 ParkSenseSignalView 0;
BA_ "GenSigTimeoutTime_DTCM" SG_ 1474 ParkSenseSignalView 0;
BA_ "GenSigTimeoutTime_ECM" SG_ 1474 ParkSenseSignalView 0;
BA_ "GenSigTimeoutTime_EVCU2" SG_ 1474 ParkSenseSignalView 0;
BA_ "GenSigTimeoutTime_GNMM" SG_ 1474 ParkSenseSignalView 0;
BA_ "GenSigTimeoutTime_HCP" SG_ 1474 ParkSenseSignalView 0;
BA_ "GenSigTimeoutTime_IPC" SG_ 1474 ParkSenseSignalView 0;
BA_ "GenSigTimeoutTime_RFHM" SG_ 1474 ParkSenseSignalView 0;
BA_ "GenSigTimeoutTime_TCM" SG_ 1474 ParkSenseSignalView 0;
BA_ "GenSigStartValue" SG_ 1474 PFTM_Alert 1;
BA_ "GenSigSendType" SG_ 1474 PFTM_Alert 4;
BA_ "GenSigTimeoutTime_AGSM" SG_ 1474 PFTM_Alert 0;
BA_ "GenSigTimeoutTime_BSM" SG_ 1474 PFTM_Alert 0;
BA_ "GenSigTimeoutTime_CADM" SG_ 1474 PFTM_Alert 0;
BA_ "GenSigTimeoutTime_DMSM" SG_ 1474 PFTM_Alert 0;
BA_ "GenSigTimeoutTime_DTCM" SG_ 1474 PFTM_Alert 0;
BA_ "GenSigTimeoutTime_ECM" SG_ 1474 PFTM_Alert 0;
BA_ "GenSigTimeoutTime_EVCU2" SG_ 1474 PFTM_Alert 0;
BA_ "GenSigTimeoutTime_GNMM" SG_ 1474 PFTM_Alert 0;
BA_ "GenSigTimeoutTime_HCP" SG_ 1474 PFTM_Alert 0;
BA_ "GenSigTimeoutTime_IPC" SG_ 1474 PFTM_Alert 0;
BA_ "GenSigTimeoutTime_RFHM" SG_ 1474 PFTM_Alert 0;
BA_ "GenSigTimeoutTime_TCM" SG_ 1474 PFTM_Alert 0;
BA_ "GenSigStartValue" SG_ 1474 PFTM_Enable 1;
BA_ "GenSigSendType" SG_ 1474 PFTM_Enable 4;
BA_ "GenSigTimeoutTime_AGSM" SG_ 1474 PFTM_Enable 0;
BA_ "GenSigTimeoutTime_BCM" SG_ 1474 PFTM_Enable 0;
BA_ "GenSigTimeoutTime_BSM" SG_ 1474 PFTM_Enable 0;
BA_ "GenSigTimeoutTime_CADM" SG_ 1474 PFTM_Enable 0;
BA_ "GenSigTimeoutTime_DMSM" SG_ 1474 PFTM_Enable 0;
BA_ "GenSigTimeoutTime_DTCM" SG_ 1474 PFTM_Enable 0;
BA_ "GenSigTimeoutTime_ECM" SG_ 1474 PFTM_Enable 0;
BA_ "GenSigTimeoutTime_EVCU2" SG_ 1474 PFTM_Enable 0;
BA_ "GenSigTimeoutTime_GNMM" SG_ 1474 PFTM_Enable 0;
BA_ "GenSigTimeoutTime_HCP" SG_ 1474 PFTM_Enable 0;
BA_ "GenSigTimeoutTime_IPC" SG_ 1474 PFTM_Enable 0;
BA_ "GenSigTimeoutTime_RFHM" SG_ 1474 PFTM_Enable 0;
BA_ "GenSigTimeoutTime_TCM" SG_ 1474 PFTM_Enable 0;
BA_ "GenSigStartValue" SG_ 1474 Power_Tailgate_Enable 1;
BA_ "GenSigSendType" SG_ 1474 Power_Tailgate_Enable 4;
BA_ "GenSigTimeoutTime_AGSM" SG_ 1474 Power_Tailgate_Enable 0;
BA_ "GenSigTimeoutTime_BSM" SG_ 1474 Power_Tailgate_Enable 0;
BA_ "GenSigTimeoutTime_CADM" SG_ 1474 Power_Tailgate_Enable 0;
BA_ "GenSigTimeoutTime_DMSM" SG_ 1474 Power_Tailgate_Enable 0;
BA_ "GenSigTimeoutTime_DTCM" SG_ 1474 Power_Tailgate_Enable 0;
BA_ "GenSigTimeoutTime_ECM" SG_ 1474 Power_Tailgate_Enable 0;
BA_ "GenSigTimeoutTime_EVCU2" SG_ 1474 Power_Tailgate_Enable 0;
BA_ "GenSigTimeoutTime_GNMM" SG_ 1474 Power_Tailgate_Enable 0;
BA_ "GenSigTimeoutTime_HCP" SG_ 1474 Power_Tailgate_Enable 0;
BA_ "GenSigTimeoutTime_IPC" SG_ 1474 Power_Tailgate_Enable 0;
BA_ "GenSigTimeoutTime_RFHM" SG_ 1474 Power_Tailgate_Enable 0;
BA_ "GenSigTimeoutTime_TCM" SG_ 1474 Power_Tailgate_Enable 0;
BA_ "GenSigStartValue" SG_ 1474 Rear_G_LGT_with_Cargo_Lights 1;
BA_ "GenSigSendType" SG_ 1474 Rear_G_LGT_with_Cargo_Lights 4;
BA_ "GenSigTimeoutTime_AGSM" SG_ 1474 Rear_G_LGT_with_Cargo_Lights 0;
BA_ "GenSigTimeoutTime_BSM" SG_ 1474 Rear_G_LGT_with_Cargo_Lights 0;
BA_ "GenSigTimeoutTime_CADM" SG_ 1474 Rear_G_LGT_with_Cargo_Lights 0;
BA_ "GenSigTimeoutTime_DMSM" SG_ 1474 Rear_G_LGT_with_Cargo_Lights 0;
BA_ "GenSigTimeoutTime_DTCM" SG_ 1474 Rear_G_LGT_with_Cargo_Lights 0;
BA_ "GenSigTimeoutTime_ECM" SG_ 1474 Rear_G_LGT_with_Cargo_Lights 0;
BA_ "GenSigTimeoutTime_EVCU2" SG_ 1474 Rear_G_LGT_with_Cargo_Lights 0;
BA_ "GenSigTimeoutTime_GNMM" SG_ 1474 Rear_G_LGT_with_Cargo_Lights 0;
BA_ "GenSigTimeoutTime_HCP" SG_ 1474 Rear_G_LGT_with_Cargo_Lights 0;
BA_ "GenSigTimeoutTime_IPC" SG_ 1474 Rear_G_LGT_with_Cargo_Lights 0;
BA_ "GenSigTimeoutTime_RFHM" SG_ 1474 Rear_G_LGT_with_Cargo_Lights 0;
BA_ "GenSigTimeoutTime_TCM" SG_ 1474 Rear_G_LGT_with_Cargo_Lights 0;
BA_ "GenSigSendType" SG_ 1474 Rear_Guidance_Light_Status 4;
BA_ "GenSigTimeoutTime_AGSM" SG_ 1474 Rear_Guidance_Light_Status 0;
BA_ "GenSigTimeoutTime_BSM" SG_ 1474 Rear_Guidance_Light_Status 0;
BA_ "GenSigTimeoutTime_CADM" SG_ 1474 Rear_Guidance_Light_Status 0;
BA_ "GenSigTimeoutTime_DMSM" SG_ 1474 Rear_Guidance_Light_Status 0;
BA_ "GenSigTimeoutTime_DTCM" SG_ 1474 Rear_Guidance_Light_Status 0;
BA_ "GenSigTimeoutTime_ECM" SG_ 1474 Rear_Guidance_Light_Status 0;
BA_ "GenSigTimeoutTime_EVCU2" SG_ 1474 Rear_Guidance_Light_Status 0;
BA_ "GenSigTimeoutTime_GNMM" SG_ 1474 Rear_Guidance_Light_Status 0;
BA_ "GenSigTimeoutTime_HCP" SG_ 1474 Rear_Guidance_Light_Status 0;
BA_ "GenSigTimeoutTime_IPC" SG_ 1474 Rear_Guidance_Light_Status 0;
BA_ "GenSigTimeoutTime_RFHM" SG_ 1474 Rear_Guidance_Light_Status 0;
BA_ "GenSigTimeoutTime_TCM" SG_ 1474 Rear_Guidance_Light_Status 0;
BA_ "GenSigSendType" SG_ 1474 Rear_Lights_with_Approach 4;
BA_ "GenSigTimeoutTime_AGSM" SG_ 1474 Rear_Lights_with_Approach 0;
BA_ "GenSigTimeoutTime_BSM" SG_ 1474 Rear_Lights_with_Approach 0;
BA_ "GenSigTimeoutTime_CADM" SG_ 1474 Rear_Lights_with_Approach 0;
BA_ "GenSigTimeoutTime_DMSM" SG_ 1474 Rear_Lights_with_Approach 0;
BA_ "GenSigTimeoutTime_DTCM" SG_ 1474 Rear_Lights_with_Approach 0;
BA_ "GenSigTimeoutTime_ECM" SG_ 1474 Rear_Lights_with_Approach 0;
BA_ "GenSigTimeoutTime_EVCU2" SG_ 1474 Rear_Lights_with_Approach 0;
BA_ "GenSigTimeoutTime_GNMM" SG_ 1474 Rear_Lights_with_Approach 0;
BA_ "GenSigTimeoutTime_HCP" SG_ 1474 Rear_Lights_with_Approach 0;
BA_ "GenSigTimeoutTime_IPC" SG_ 1474 Rear_Lights_with_Approach 0;
BA_ "GenSigTimeoutTime_RFHM" SG_ 1474 Rear_Lights_with_Approach 0;
BA_ "GenSigTimeoutTime_TCM" SG_ 1474 Rear_Lights_with_Approach 0;
BA_ "GenSigStartValue" SG_ 1474 SignatureLightingEnable 1;
BA_ "GenSigSendType" SG_ 1474 SignatureLightingEnable 4;
BA_ "GenSigTimeoutTime_AGSM" SG_ 1474 SignatureLightingEnable 0;
BA_ "GenSigTimeoutTime_BSM" SG_ 1474 SignatureLightingEnable 0;
BA_ "GenSigTimeoutTime_CADM" SG_ 1474 SignatureLightingEnable 0;
BA_ "GenSigTimeoutTime_DMSM" SG_ 1474 SignatureLightingEnable 0;
BA_ "GenSigTimeoutTime_DTCM" SG_ 1474 SignatureLightingEnable 0;
BA_ "GenSigTimeoutTime_ECM" SG_ 1474 SignatureLightingEnable 0;
BA_ "GenSigTimeoutTime_EVCU2" SG_ 1474 SignatureLightingEnable 0;
BA_ "GenSigTimeoutTime_GNMM" SG_ 1474 SignatureLightingEnable 0;
BA_ "GenSigTimeoutTime_HCP" SG_ 1474 SignatureLightingEnable 0;
BA_ "GenSigTimeoutTime_IPC" SG_ 1474 SignatureLightingEnable 0;
BA_ "GenSigTimeoutTime_RFHM" SG_ 1474 SignatureLightingEnable 0;
BA_ "GenSigTimeoutTime_TCM" SG_ 1474 SignatureLightingEnable 0;
BA_ "GenSigStartValue" SG_ 1474 Trailer_Light_Check 1;
BA_ "GenSigSendType" SG_ 1474 Trailer_Light_Check 3;
BA_ "GenSigTimeoutTime_AGSM" SG_ 1474 Trailer_Light_Check 0;
BA_ "GenSigTimeoutTime_BSM" SG_ 1474 Trailer_Light_Check 0;
BA_ "GenSigTimeoutTime_CADM" SG_ 1474 Trailer_Light_Check 0;
BA_ "GenSigTimeoutTime_DMSM" SG_ 1474 Trailer_Light_Check 0;
BA_ "GenSigTimeoutTime_DTCM" SG_ 1474 Trailer_Light_Check 0;
BA_ "GenSigTimeoutTime_ECM" SG_ 1474 Trailer_Light_Check 0;
BA_ "GenSigTimeoutTime_EVCU2" SG_ 1474 Trailer_Light_Check 0;
BA_ "GenSigTimeoutTime_GNMM" SG_ 1474 Trailer_Light_Check 0;
BA_ "GenSigTimeoutTime_HCP" SG_ 1474 Trailer_Light_Check 0;
BA_ "GenSigTimeoutTime_IPC" SG_ 1474 Trailer_Light_Check 0;
BA_ "GenSigTimeoutTime_RFHM" SG_ 1474 Trailer_Light_Check 0;
BA_ "GenSigTimeoutTime_TCM" SG_ 1474 Trailer_Light_Check 0;
BA_ "GenSigStartValue" SG_ 1474 TSI_Offset_Kph 1;
BA_ "GenSigSendType" SG_ 1474 TSI_Offset_Kph 3;
BA_ "GenSigTimeoutTime_AGSM" SG_ 1474 TSI_Offset_Kph 0;
BA_ "GenSigTimeoutTime_BSM" SG_ 1474 TSI_Offset_Kph 0;
BA_ "GenSigTimeoutTime_CADM" SG_ 1474 TSI_Offset_Kph 0;
BA_ "GenSigTimeoutTime_DMSM" SG_ 1474 TSI_Offset_Kph 0;
BA_ "GenSigTimeoutTime_DTCM" SG_ 1474 TSI_Offset_Kph 0;
BA_ "GenSigTimeoutTime_ECM" SG_ 1474 TSI_Offset_Kph 0;
BA_ "GenSigTimeoutTime_EVCU2" SG_ 1474 TSI_Offset_Kph 0;
BA_ "GenSigTimeoutTime_GNMM" SG_ 1474 TSI_Offset_Kph 0;
BA_ "GenSigTimeoutTime_HCP" SG_ 1474 TSI_Offset_Kph 0;
BA_ "GenSigTimeoutTime_IPC" SG_ 1474 TSI_Offset_Kph 0;
BA_ "GenSigTimeoutTime_RFHM" SG_ 1474 TSI_Offset_Kph 0;
BA_ "GenSigTimeoutTime_TCM" SG_ 1474 TSI_Offset_Kph 0;
BA_ "GenSigStartValue" SG_ 1474 TSI_Offset_Mph 1;
BA_ "GenSigSendType" SG_ 1474 TSI_Offset_Mph 3;
BA_ "GenSigTimeoutTime_AGSM" SG_ 1474 TSI_Offset_Mph 0;
BA_ "GenSigTimeoutTime_BSM" SG_ 1474 TSI_Offset_Mph 0;
BA_ "GenSigTimeoutTime_CADM" SG_ 1474 TSI_Offset_Mph 0;
BA_ "GenSigTimeoutTime_DMSM" SG_ 1474 TSI_Offset_Mph 0;
BA_ "GenSigTimeoutTime_DTCM" SG_ 1474 TSI_Offset_Mph 0;
BA_ "GenSigTimeoutTime_ECM" SG_ 1474 TSI_Offset_Mph 0;
BA_ "GenSigTimeoutTime_EVCU2" SG_ 1474 TSI_Offset_Mph 0;
BA_ "GenSigTimeoutTime_GNMM" SG_ 1474 TSI_Offset_Mph 0;
BA_ "GenSigTimeoutTime_HCP" SG_ 1474 TSI_Offset_Mph 0;
BA_ "GenSigTimeoutTime_IPC" SG_ 1474 TSI_Offset_Mph 0;
BA_ "GenSigTimeoutTime_RFHM" SG_ 1474 TSI_Offset_Mph 0;
BA_ "GenSigTimeoutTime_TCM" SG_ 1474 TSI_Offset_Mph 0;
BA_ "GenSigSendType" SG_ 1474 TurnSignalView 4;
BA_ "GenSigTimeoutTime_AGSM" SG_ 1474 TurnSignalView 0;
BA_ "GenSigTimeoutTime_BSM" SG_ 1474 TurnSignalView 0;
BA_ "GenSigTimeoutTime_CADM" SG_ 1474 TurnSignalView 0;
BA_ "GenSigTimeoutTime_DMSM" SG_ 1474 TurnSignalView 0;
BA_ "GenSigTimeoutTime_DTCM" SG_ 1474 TurnSignalView 0;
BA_ "GenSigTimeoutTime_ECM" SG_ 1474 TurnSignalView 0;
BA_ "GenSigTimeoutTime_EVCU2" SG_ 1474 TurnSignalView 0;
BA_ "GenSigTimeoutTime_GNMM" SG_ 1474 TurnSignalView 0;
BA_ "GenSigTimeoutTime_HCP" SG_ 1474 TurnSignalView 0;
BA_ "GenSigTimeoutTime_IPC" SG_ 1474 TurnSignalView 0;
BA_ "GenSigTimeoutTime_RFHM" SG_ 1474 TurnSignalView 0;
BA_ "GenSigTimeoutTime_TCM" SG_ 1474 TurnSignalView 0;
BA_ "GenSigStartValue" SG_ 1474 WorksiteINVM_Audible_LFW 1;
BA_ "GenSigSendType" SG_ 1474 WorksiteINVM_Audible_LFW 4;
BA_ "GenSigTimeoutTime_AGSM" SG_ 1474 WorksiteINVM_Audible_LFW 0;
BA_ "GenSigTimeoutTime_BSM" SG_ 1474 WorksiteINVM_Audible_LFW 0;
BA_ "GenSigTimeoutTime_CADM" SG_ 1474 WorksiteINVM_Audible_LFW 0;
BA_ "GenSigTimeoutTime_DMSM" SG_ 1474 WorksiteINVM_Audible_LFW 0;
BA_ "GenSigTimeoutTime_DTCM" SG_ 1474 WorksiteINVM_Audible_LFW 0;
BA_ "GenSigTimeoutTime_ECM" SG_ 1474 WorksiteINVM_Audible_LFW 0;
BA_ "GenSigTimeoutTime_EVCU2" SG_ 1474 WorksiteINVM_Audible_LFW 0;
BA_ "GenSigTimeoutTime_GNMM" SG_ 1474 WorksiteINVM_Audible_LFW 0;
BA_ "GenSigTimeoutTime_HCP" SG_ 1474 WorksiteINVM_Audible_LFW 0;
BA_ "GenSigTimeoutTime_IPC" SG_ 1474 WorksiteINVM_Audible_LFW 0;
BA_ "GenSigTimeoutTime_RFHM" SG_ 1474 WorksiteINVM_Audible_LFW 0;
BA_ "GenSigTimeoutTime_TCM" SG_ 1474 WorksiteINVM_Audible_LFW 0;
BA_ "GenSigStartValue" SG_ 1474 WorksiteINVM_Visual_LFW 1;
BA_ "GenSigSendType" SG_ 1474 WorksiteINVM_Visual_LFW 4;
BA_ "GenSigTimeoutTime_AGSM" SG_ 1474 WorksiteINVM_Visual_LFW 0;
BA_ "GenSigTimeoutTime_BSM" SG_ 1474 WorksiteINVM_Visual_LFW 0;
BA_ "GenSigTimeoutTime_CADM" SG_ 1474 WorksiteINVM_Visual_LFW 0;
BA_ "GenSigTimeoutTime_DMSM" SG_ 1474 WorksiteINVM_Visual_LFW 0;
BA_ "GenSigTimeoutTime_DTCM" SG_ 1474 WorksiteINVM_Visual_LFW 0;
BA_ "GenSigTimeoutTime_ECM" SG_ 1474 WorksiteINVM_Visual_LFW 0;
BA_ "GenSigTimeoutTime_EVCU2" SG_ 1474 WorksiteINVM_Visual_LFW 0;
BA_ "GenSigTimeoutTime_GNMM" SG_ 1474 WorksiteINVM_Visual_LFW 0;
BA_ "GenSigTimeoutTime_HCP" SG_ 1474 WorksiteINVM_Visual_LFW 0;
BA_ "GenSigTimeoutTime_IPC" SG_ 1474 WorksiteINVM_Visual_LFW 0;
BA_ "GenSigTimeoutTime_RFHM" SG_ 1474 WorksiteINVM_Visual_LFW 0;
BA_ "GenSigTimeoutTime_TCM" SG_ 1474 WorksiteINVM_Visual_LFW 0;
BA_ "GenSigTimeoutTime_AGSM" SG_ 753 CRC_LV_CHARGER1 0;
BA_ "GenSigTimeoutTime_BCM" SG_ 753 CRC_LV_CHARGER1 0;
BA_ "GenSigTimeoutTime_BSM" SG_ 753 CRC_LV_CHARGER1 0;
BA_ "GenSigTimeoutTime_CADM" SG_ 753 CRC_LV_CHARGER1 0;
BA_ "GenSigTimeoutTime_DMSM" SG_ 753 CRC_LV_CHARGER1 0;
BA_ "GenSigTimeoutTime_DTCM" SG_ 753 CRC_LV_CHARGER1 0;
BA_ "GenSigTimeoutTime_EVCU2" SG_ 753 CRC_LV_CHARGER1 0;
BA_ "GenSigTimeoutTime_GNMM" SG_ 753 CRC_LV_CHARGER1 0;
BA_ "GenSigTimeoutTime_HCP" SG_ 753 CRC_LV_CHARGER1 0;
BA_ "GenSigTimeoutTime_IPC" SG_ 753 CRC_LV_CHARGER1 0;
BA_ "GenSigTimeoutTime_RFHM" SG_ 753 CRC_LV_CHARGER1 0;
BA_ "GenSigTimeoutTime_SGW" SG_ 753 CRC_LV_CHARGER1 0;
BA_ "GenSigTimeoutTime_TCM" SG_ 753 CRC_LV_CHARGER1 0;
BA_ "GenSigTimeoutTime_AGSM" SG_ 753 DCDC_OperationModeSts 0;
BA_ "GenSigTimeoutTime_BCM" SG_ 753 DCDC_OperationModeSts 0;
BA_ "GenSigTimeoutTime_BSM" SG_ 753 DCDC_OperationModeSts 0;
BA_ "GenSigTimeoutTime_CADM" SG_ 753 DCDC_OperationModeSts 0;
BA_ "GenSigTimeoutTime_DMSM" SG_ 753 DCDC_OperationModeSts 0;
BA_ "GenSigTimeoutTime_DTCM" SG_ 753 DCDC_OperationModeSts 0;
BA_ "GenSigTimeoutTime_EVCU2" SG_ 753 DCDC_OperationModeSts 0;
BA_ "GenSigTimeoutTime_GNMM" SG_ 753 DCDC_OperationModeSts 0;
BA_ "GenSigTimeoutTime_HCP" SG_ 753 DCDC_OperationModeSts 0;
BA_ "GenSigTimeoutTime_IPC" SG_ 753 DCDC_OperationModeSts 0;
BA_ "GenSigTimeoutTime_RFHM" SG_ 753 DCDC_OperationModeSts 0;
BA_ "GenSigTimeoutTime_SGW" SG_ 753 DCDC_OperationModeSts 0;
BA_ "GenSigTimeoutTime_TCM" SG_ 753 DCDC_OperationModeSts 0;
BA_ "GenSigStartValue" SG_ 753 HVDC_CurrentFeedback 1021;
BA_ "GenSigTimeoutTime_AGSM" SG_ 753 HVDC_CurrentFeedback 0;
BA_ "GenSigTimeoutTime_BCM" SG_ 753 HVDC_CurrentFeedback 0;
BA_ "GenSigTimeoutTime_BSM" SG_ 753 HVDC_CurrentFeedback 0;
BA_ "GenSigTimeoutTime_CADM" SG_ 753 HVDC_CurrentFeedback 0;
BA_ "GenSigTimeoutTime_DMSM" SG_ 753 HVDC_CurrentFeedback 0;
BA_ "GenSigTimeoutTime_DTCM" SG_ 753 HVDC_CurrentFeedback 0;
BA_ "GenSigTimeoutTime_EVCU2" SG_ 753 HVDC_CurrentFeedback 0;
BA_ "GenSigTimeoutTime_GNMM" SG_ 753 HVDC_CurrentFeedback 0;
BA_ "GenSigTimeoutTime_HCP" SG_ 753 HVDC_CurrentFeedback 0;
BA_ "GenSigTimeoutTime_IPC" SG_ 753 HVDC_CurrentFeedback 0;
BA_ "GenSigTimeoutTime_RFHM" SG_ 753 HVDC_CurrentFeedback 0;
BA_ "GenSigTimeoutTime_SGW" SG_ 753 HVDC_CurrentFeedback 0;
BA_ "GenSigTimeoutTime_TCM" SG_ 753 HVDC_CurrentFeedback 0;
BA_ "GenSigTimeoutTime_AGSM" SG_ 753 HVDC_VoltageFeedback 0;
BA_ "GenSigTimeoutTime_BCM" SG_ 753 HVDC_VoltageFeedback 0;
BA_ "GenSigTimeoutTime_BSM" SG_ 753 HVDC_VoltageFeedback 0;
BA_ "GenSigTimeoutTime_CADM" SG_ 753 HVDC_VoltageFeedback 0;
BA_ "GenSigTimeoutTime_DMSM" SG_ 753 HVDC_VoltageFeedback 0;
BA_ "GenSigTimeoutTime_DTCM" SG_ 753 HVDC_VoltageFeedback 0;
BA_ "GenSigTimeoutTime_EVCU2" SG_ 753 HVDC_VoltageFeedback 0;
BA_ "GenSigTimeoutTime_GNMM" SG_ 753 HVDC_VoltageFeedback 0;
BA_ "GenSigTimeoutTime_HCP" SG_ 753 HVDC_VoltageFeedback 0;
BA_ "GenSigTimeoutTime_IPC" SG_ 753 HVDC_VoltageFeedback 0;
BA_ "GenSigTimeoutTime_RFHM" SG_ 753 HVDC_VoltageFeedback 0;
BA_ "GenSigTimeoutTime_SGW" SG_ 753 HVDC_VoltageFeedback 0;
BA_ "GenSigTimeoutTime_TCM" SG_ 753 HVDC_VoltageFeedback 0;
BA_ "GenSigStartValue" SG_ 753 LVDC_CurrentFeedback 4095;
BA_ "GenSigTimeoutTime_AGSM" SG_ 753 LVDC_CurrentFeedback 0;
BA_ "GenSigTimeoutTime_BCM" SG_ 753 LVDC_CurrentFeedback 0;
BA_ "GenSigTimeoutTime_BSM" SG_ 753 LVDC_CurrentFeedback 0;
BA_ "GenSigTimeoutTime_CADM" SG_ 753 LVDC_CurrentFeedback 0;
BA_ "GenSigTimeoutTime_DMSM" SG_ 753 LVDC_CurrentFeedback 0;
BA_ "GenSigTimeoutTime_DTCM" SG_ 753 LVDC_CurrentFeedback 0;
BA_ "GenSigTimeoutTime_EVCU2" SG_ 753 LVDC_CurrentFeedback 0;
BA_ "GenSigTimeoutTime_GNMM" SG_ 753 LVDC_CurrentFeedback 0;
BA_ "GenSigTimeoutTime_HCP" SG_ 753 LVDC_CurrentFeedback 0;
BA_ "GenSigTimeoutTime_IPC" SG_ 753 LVDC_CurrentFeedback 0;
BA_ "GenSigTimeoutTime_RFHM" SG_ 753 LVDC_CurrentFeedback 0;
BA_ "GenSigTimeoutTime_SGW" SG_ 753 LVDC_CurrentFeedback 0;
BA_ "GenSigTimeoutTime_TCM" SG_ 753 LVDC_CurrentFeedback 0;
BA_ "GenSigTimeoutTime_AGSM" SG_ 753 MessageCounter_LV_CHARGER1 0;
BA_ "GenSigTimeoutTime_BCM" SG_ 753 MessageCounter_LV_CHARGER1 0;
BA_ "GenSigTimeoutTime_BSM" SG_ 753 MessageCounter_LV_CHARGER1 0;
BA_ "GenSigTimeoutTime_CADM" SG_ 753 MessageCounter_LV_CHARGER1 0;
BA_ "GenSigTimeoutTime_DMSM" SG_ 753 MessageCounter_LV_CHARGER1 0;
BA_ "GenSigTimeoutTime_DTCM" SG_ 753 MessageCounter_LV_CHARGER1 0;
BA_ "GenSigTimeoutTime_EVCU2" SG_ 753 MessageCounter_LV_CHARGER1 0;
BA_ "GenSigTimeoutTime_GNMM" SG_ 753 MessageCounter_LV_CHARGER1 0;
BA_ "GenSigTimeoutTime_HCP" SG_ 753 MessageCounter_LV_CHARGER1 0;
BA_ "GenSigTimeoutTime_IPC" SG_ 753 MessageCounter_LV_CHARGER1 0;
BA_ "GenSigTimeoutTime_RFHM" SG_ 753 MessageCounter_LV_CHARGER1 0;
BA_ "GenSigTimeoutTime_SGW" SG_ 753 MessageCounter_LV_CHARGER1 0;
BA_ "GenSigTimeoutTime_TCM" SG_ 753 MessageCounter_LV_CHARGER1 0;
BA_ "GenSigStartValue" SG_ 1062 MCPA_Temp 40;
BA_ "GenSigTimeoutTime_AGSM" SG_ 1062 MCPA_Temp 0;
BA_ "GenSigTimeoutTime_BCM" SG_ 1062 MCPA_Temp 0;
BA_ "GenSigTimeoutTime_BSM" SG_ 1062 MCPA_Temp 0;
BA_ "GenSigTimeoutTime_CADM" SG_ 1062 MCPA_Temp 0;
BA_ "GenSigTimeoutTime_DMSM" SG_ 1062 MCPA_Temp 0;
BA_ "GenSigTimeoutTime_DTCM" SG_ 1062 MCPA_Temp 0;
BA_ "GenSigTimeoutTime_ECM" SG_ 1062 MCPA_Temp 0;
BA_ "GenSigTimeoutTime_EVCU2" SG_ 1062 MCPA_Temp 0;
BA_ "GenSigTimeoutTime_GNMM" SG_ 1062 MCPA_Temp 0;
BA_ "GenSigTimeoutTime_HCP" SG_ 1062 MCPA_Temp 0;
BA_ "GenSigTimeoutTime_IPC" SG_ 1062 MCPA_Temp 0;
BA_ "GenSigTimeoutTime_RFHM" SG_ 1062 MCPA_Temp 0;
BA_ "GenSigTimeoutTime_TCM" SG_ 1062 MCPA_Temp 0;
BA_ "GenSigSendType" SG_ 125 MESS_TTPM1 1;
BA_ "GenSigTimeoutTime_AGSM" SG_ 125 MESS_TTPM1 0;
BA_ "GenSigTimeoutTime_BCM" SG_ 125 MESS_TTPM1 0;
BA_ "GenSigTimeoutTime_BSM" SG_ 125 MESS_TTPM1 0;
BA_ "GenSigTimeoutTime_CADM" SG_ 125 MESS_TTPM1 0;
BA_ "GenSigTimeoutTime_DMSM" SG_ 125 MESS_TTPM1 0;
BA_ "GenSigTimeoutTime_DTCM" SG_ 125 MESS_TTPM1 0;
BA_ "GenSigTimeoutTime_ECM" SG_ 125 MESS_TTPM1 0;
BA_ "GenSigTimeoutTime_EVCU2" SG_ 125 MESS_TTPM1 0;
BA_ "GenSigTimeoutTime_GNMM" SG_ 125 MESS_TTPM1 0;
BA_ "GenSigTimeoutTime_HCP" SG_ 125 MESS_TTPM1 0;
BA_ "GenSigTimeoutTime_IPC" SG_ 125 MESS_TTPM1 0;
BA_ "GenSigTimeoutTime_RFHM" SG_ 125 MESS_TTPM1 0;
BA_ "GenSigTimeoutTime_TCM" SG_ 125 MESS_TTPM1 0;
BA_ "GenSigTimeoutTime_AGSM" SG_ 2654486550 CBV_bit0_RepeatMessageRequestBit 0;
BA_ "GenSigTimeoutTime_BCM" SG_ 2654486550 CBV_bit0_RepeatMessageRequestBit 0;
BA_ "GenSigTimeoutTime_BSM" SG_ 2654486550 CBV_bit0_RepeatMessageRequestBit 0;
BA_ "GenSigTimeoutTime_CADM" SG_ 2654486550 CBV_bit0_RepeatMessageRequestBit 0;
BA_ "GenSigTimeoutTime_DMSM" SG_ 2654486550 CBV_bit0_RepeatMessageRequestBit 0;
BA_ "GenSigTimeoutTime_DTCM" SG_ 2654486550 CBV_bit0_RepeatMessageRequestBit 0;
BA_ "GenSigTimeoutTime_ECM" SG_ 2654486550 CBV_bit0_RepeatMessageRequestBit 0;
BA_ "GenSigTimeoutTime_EVCU2" SG_ 2654486550 CBV_bit0_RepeatMessageRequestBit 0;
BA_ "GenSigTimeoutTime_GNMM" SG_ 2654486550 CBV_bit0_RepeatMessageRequestBit 0;
BA_ "GenSigTimeoutTime_HCP" SG_ 2654486550 CBV_bit0_RepeatMessageRequestBit 0;
BA_ "GenSigTimeoutTime_IPC" SG_ 2654486550 CBV_bit0_RepeatMessageRequestBit 0;
BA_ "GenSigTimeoutTime_RFHM" SG_ 2654486550 CBV_bit0_RepeatMessageRequestBit 0;
BA_ "GenSigTimeoutTime_SGW" SG_ 2654486550 CBV_bit0_RepeatMessageRequestBit 0;
BA_ "GenSigTimeoutTime_TCM" SG_ 2654486550 CBV_bit0_RepeatMessageRequestBit 0;
BA_ "GenSigTimeoutTime_AGSM" SG_ 2654486550 CBV_bit1 0;
BA_ "GenSigTimeoutTime_BCM" SG_ 2654486550 CBV_bit1 0;
BA_ "GenSigTimeoutTime_BSM" SG_ 2654486550 CBV_bit1 0;
BA_ "GenSigTimeoutTime_CADM" SG_ 2654486550 CBV_bit1 0;
BA_ "GenSigTimeoutTime_DMSM" SG_ 2654486550 CBV_bit1 0;
BA_ "GenSigTimeoutTime_DTCM" SG_ 2654486550 CBV_bit1 0;
BA_ "GenSigTimeoutTime_ECM" SG_ 2654486550 CBV_bit1 0;
BA_ "GenSigTimeoutTime_EVCU2" SG_ 2654486550 CBV_bit1 0;
BA_ "GenSigTimeoutTime_GNMM" SG_ 2654486550 CBV_bit1 0;
BA_ "GenSigTimeoutTime_HCP" SG_ 2654486550 CBV_bit1 0;
BA_ "GenSigTimeoutTime_IPC" SG_ 2654486550 CBV_bit1 0;
BA_ "GenSigTimeoutTime_RFHM" SG_ 2654486550 CBV_bit1 0;
BA_ "GenSigTimeoutTime_SGW" SG_ 2654486550 CBV_bit1 0;
BA_ "GenSigTimeoutTime_TCM" SG_ 2654486550 CBV_bit1 0;
BA_ "GenSigTimeoutTime_AGSM" SG_ 2654486550 CBV_bit2 0;
BA_ "GenSigTimeoutTime_BCM" SG_ 2654486550 CBV_bit2 0;
BA_ "GenSigTimeoutTime_BSM" SG_ 2654486550 CBV_bit2 0;
BA_ "GenSigTimeoutTime_CADM" SG_ 2654486550 CBV_bit2 0;
BA_ "GenSigTimeoutTime_DMSM" SG_ 2654486550 CBV_bit2 0;
BA_ "GenSigTimeoutTime_DTCM" SG_ 2654486550 CBV_bit2 0;
BA_ "GenSigTimeoutTime_ECM" SG_ 2654486550 CBV_bit2 0;
BA_ "GenSigTimeoutTime_EVCU2" SG_ 2654486550 CBV_bit2 0;
BA_ "GenSigTimeoutTime_GNMM" SG_ 2654486550 CBV_bit2 0;
BA_ "GenSigTimeoutTime_HCP" SG_ 2654486550 CBV_bit2 0;
BA_ "GenSigTimeoutTime_IPC" SG_ 2654486550 CBV_bit2 0;
BA_ "GenSigTimeoutTime_RFHM" SG_ 2654486550 CBV_bit2 0;
BA_ "GenSigTimeoutTime_SGW" SG_ 2654486550 CBV_bit2 0;
BA_ "GenSigTimeoutTime_TCM" SG_ 2654486550 CBV_bit2 0;
BA_ "GenSigTimeoutTime_AGSM" SG_ 2654486550 CBV_bit3_NMCoordinatorBit 0;
BA_ "GenSigTimeoutTime_BCM" SG_ 2654486550 CBV_bit3_NMCoordinatorBit 0;
BA_ "GenSigTimeoutTime_BSM" SG_ 2654486550 CBV_bit3_NMCoordinatorBit 0;
BA_ "GenSigTimeoutTime_CADM" SG_ 2654486550 CBV_bit3_NMCoordinatorBit 0;
BA_ "GenSigTimeoutTime_DMSM" SG_ 2654486550 CBV_bit3_NMCoordinatorBit 0;
BA_ "GenSigTimeoutTime_DTCM" SG_ 2654486550 CBV_bit3_NMCoordinatorBit 0;
BA_ "GenSigTimeoutTime_ECM" SG_ 2654486550 CBV_bit3_NMCoordinatorBit 0;
BA_ "GenSigTimeoutTime_EVCU2" SG_ 2654486550 CBV_bit3_NMCoordinatorBit 0;
BA_ "GenSigTimeoutTime_GNMM" SG_ 2654486550 CBV_bit3_NMCoordinatorBit 0;
BA_ "GenSigTimeoutTime_HCP" SG_ 2654486550 CBV_bit3_NMCoordinatorBit 0;
BA_ "GenSigTimeoutTime_IPC" SG_ 2654486550 CBV_bit3_NMCoordinatorBit 0;
BA_ "GenSigTimeoutTime_RFHM" SG_ 2654486550 CBV_bit3_NMCoordinatorBit 0;
BA_ "GenSigTimeoutTime_SGW" SG_ 2654486550 CBV_bit3_NMCoordinatorBit 0;
BA_ "GenSigTimeoutTime_TCM" SG_ 2654486550 CBV_bit3_NMCoordinatorBit 0;
BA_ "GenSigTimeoutTime_AGSM" SG_ 2654486550 CBV_bit4_ActiveWakeupBit 0;
BA_ "GenSigTimeoutTime_BCM" SG_ 2654486550 CBV_bit4_ActiveWakeupBit 0;
BA_ "GenSigTimeoutTime_BSM" SG_ 2654486550 CBV_bit4_ActiveWakeupBit 0;
BA_ "GenSigTimeoutTime_CADM" SG_ 2654486550 CBV_bit4_ActiveWakeupBit 0;
BA_ "GenSigTimeoutTime_DMSM" SG_ 2654486550 CBV_bit4_ActiveWakeupBit 0;
BA_ "GenSigTimeoutTime_DTCM" SG_ 2654486550 CBV_bit4_ActiveWakeupBit 0;
BA_ "GenSigTimeoutTime_ECM" SG_ 2654486550 CBV_bit4_ActiveWakeupBit 0;
BA_ "GenSigTimeoutTime_EVCU2" SG_ 2654486550 CBV_bit4_ActiveWakeupBit 0;
BA_ "GenSigTimeoutTime_GNMM" SG_ 2654486550 CBV_bit4_ActiveWakeupBit 0;
BA_ "GenSigTimeoutTime_HCP" SG_ 2654486550 CBV_bit4_ActiveWakeupBit 0;
BA_ "GenSigTimeoutTime_IPC" SG_ 2654486550 CBV_bit4_ActiveWakeupBit 0;
BA_ "GenSigTimeoutTime_RFHM" SG_ 2654486550 CBV_bit4_ActiveWakeupBit 0;
BA_ "GenSigTimeoutTime_SGW" SG_ 2654486550 CBV_bit4_ActiveWakeupBit 0;
BA_ "GenSigTimeoutTime_TCM" SG_ 2654486550 CBV_bit4_ActiveWakeupBit 0;
BA_ "GenSigTimeoutTime_AGSM" SG_ 2654486550 CBV_bit5 0;
BA_ "GenSigTimeoutTime_BCM" SG_ 2654486550 CBV_bit5 0;
BA_ "GenSigTimeoutTime_BSM" SG_ 2654486550 CBV_bit5 0;
BA_ "GenSigTimeoutTime_CADM" SG_ 2654486550 CBV_bit5 0;
BA_ "GenSigTimeoutTime_DMSM" SG_ 2654486550 CBV_bit5 0;
BA_ "GenSigTimeoutTime_DTCM" SG_ 2654486550 CBV_bit5 0;
BA_ "GenSigTimeoutTime_ECM" SG_ 2654486550 CBV_bit5 0;
BA_ "GenSigTimeoutTime_EVCU2" SG_ 2654486550 CBV_bit5 0;
BA_ "GenSigTimeoutTime_GNMM" SG_ 2654486550 CBV_bit5 0;
BA_ "GenSigTimeoutTime_HCP" SG_ 2654486550 CBV_bit5 0;
BA_ "GenSigTimeoutTime_IPC" SG_ 2654486550 CBV_bit5 0;
BA_ "GenSigTimeoutTime_RFHM" SG_ 2654486550 CBV_bit5 0;
BA_ "GenSigTimeoutTime_SGW" SG_ 2654486550 CBV_bit5 0;
BA_ "GenSigTimeoutTime_TCM" SG_ 2654486550 CBV_bit5 0;
BA_ "GenSigTimeoutTime_AGSM" SG_ 2654486550 CBV_bit6_PartialNtwInfBit 0;
BA_ "GenSigTimeoutTime_BCM" SG_ 2654486550 CBV_bit6_PartialNtwInfBit 0;
BA_ "GenSigTimeoutTime_BSM" SG_ 2654486550 CBV_bit6_PartialNtwInfBit 0;
BA_ "GenSigTimeoutTime_CADM" SG_ 2654486550 CBV_bit6_PartialNtwInfBit 0;
BA_ "GenSigTimeoutTime_DMSM" SG_ 2654486550 CBV_bit6_PartialNtwInfBit 0;
BA_ "GenSigTimeoutTime_DTCM" SG_ 2654486550 CBV_bit6_PartialNtwInfBit 0;
BA_ "GenSigTimeoutTime_ECM" SG_ 2654486550 CBV_bit6_PartialNtwInfBit 0;
BA_ "GenSigTimeoutTime_EVCU2" SG_ 2654486550 CBV_bit6_PartialNtwInfBit 0;
BA_ "GenSigTimeoutTime_GNMM" SG_ 2654486550 CBV_bit6_PartialNtwInfBit 0;
BA_ "GenSigTimeoutTime_HCP" SG_ 2654486550 CBV_bit6_PartialNtwInfBit 0;
BA_ "GenSigTimeoutTime_IPC" SG_ 2654486550 CBV_bit6_PartialNtwInfBit 0;
BA_ "GenSigTimeoutTime_RFHM" SG_ 2654486550 CBV_bit6_PartialNtwInfBit 0;
BA_ "GenSigTimeoutTime_SGW" SG_ 2654486550 CBV_bit6_PartialNtwInfBit 0;
BA_ "GenSigTimeoutTime_TCM" SG_ 2654486550 CBV_bit6_PartialNtwInfBit 0;
BA_ "GenSigTimeoutTime_AGSM" SG_ 2654486550 CBV_bit7 0;
BA_ "GenSigTimeoutTime_BCM" SG_ 2654486550 CBV_bit7 0;
BA_ "GenSigTimeoutTime_BSM" SG_ 2654486550 CBV_bit7 0;
BA_ "GenSigTimeoutTime_CADM" SG_ 2654486550 CBV_bit7 0;
BA_ "GenSigTimeoutTime_DMSM" SG_ 2654486550 CBV_bit7 0;
BA_ "GenSigTimeoutTime_DTCM" SG_ 2654486550 CBV_bit7 0;
BA_ "GenSigTimeoutTime_ECM" SG_ 2654486550 CBV_bit7 0;
BA_ "GenSigTimeoutTime_EVCU2" SG_ 2654486550 CBV_bit7 0;
BA_ "GenSigTimeoutTime_GNMM" SG_ 2654486550 CBV_bit7 0;
BA_ "GenSigTimeoutTime_HCP" SG_ 2654486550 CBV_bit7 0;
BA_ "GenSigTimeoutTime_IPC" SG_ 2654486550 CBV_bit7 0;
BA_ "GenSigTimeoutTime_RFHM" SG_ 2654486550 CBV_bit7 0;
BA_ "GenSigTimeoutTime_SGW" SG_ 2654486550 CBV_bit7 0;
BA_ "GenSigTimeoutTime_TCM" SG_ 2654486550 CBV_bit7 0;
BA_ "GenSigTimeoutTime_AGSM" SG_ 2654486550 SourceNodeIdentifier 0;
BA_ "GenSigTimeoutTime_BCM" SG_ 2654486550 SourceNodeIdentifier 0;
BA_ "GenSigTimeoutTime_BSM" SG_ 2654486550 SourceNodeIdentifier 0;
BA_ "GenSigTimeoutTime_CADM" SG_ 2654486550 SourceNodeIdentifier 0;
BA_ "GenSigTimeoutTime_DMSM" SG_ 2654486550 SourceNodeIdentifier 0;
BA_ "GenSigTimeoutTime_DTCM" SG_ 2654486550 SourceNodeIdentifier 0;
BA_ "GenSigTimeoutTime_ECM" SG_ 2654486550 SourceNodeIdentifier 0;
BA_ "GenSigTimeoutTime_EVCU2" SG_ 2654486550 SourceNodeIdentifier 0;
BA_ "GenSigTimeoutTime_GNMM" SG_ 2654486550 SourceNodeIdentifier 0;
BA_ "GenSigTimeoutTime_HCP" SG_ 2654486550 SourceNodeIdentifier 0;
BA_ "GenSigTimeoutTime_IPC" SG_ 2654486550 SourceNodeIdentifier 0;
BA_ "GenSigTimeoutTime_RFHM" SG_ 2654486550 SourceNodeIdentifier 0;
BA_ "GenSigTimeoutTime_SGW" SG_ 2654486550 SourceNodeIdentifier 0;
BA_ "GenSigTimeoutTime_TCM" SG_ 2654486550 SourceNodeIdentifier 0;
BA_ "GenSigTimeoutTime_AGSM" SG_ 2654486528 CBV_bit0_RepeatMessageRequestBit 0;
BA_ "GenSigTimeoutTime_BCM" SG_ 2654486528 CBV_bit0_RepeatMessageRequestBit 0;
BA_ "GenSigTimeoutTime_BSM" SG_ 2654486528 CBV_bit0_RepeatMessageRequestBit 0;
BA_ "GenSigTimeoutTime_CADM" SG_ 2654486528 CBV_bit0_RepeatMessageRequestBit 0;
BA_ "GenSigTimeoutTime_DMSM" SG_ 2654486528 CBV_bit0_RepeatMessageRequestBit 0;
BA_ "GenSigTimeoutTime_DTCM" SG_ 2654486528 CBV_bit0_RepeatMessageRequestBit 0;
BA_ "GenSigTimeoutTime_ECM" SG_ 2654486528 CBV_bit0_RepeatMessageRequestBit 0;
BA_ "GenSigTimeoutTime_EVCU2" SG_ 2654486528 CBV_bit0_RepeatMessageRequestBit 0;
BA_ "GenSigTimeoutTime_GNMM" SG_ 2654486528 CBV_bit0_RepeatMessageRequestBit 0;
BA_ "GenSigTimeoutTime_HCP" SG_ 2654486528 CBV_bit0_RepeatMessageRequestBit 0;
BA_ "GenSigTimeoutTime_IPC" SG_ 2654486528 CBV_bit0_RepeatMessageRequestBit 0;
BA_ "GenSigTimeoutTime_RFHM" SG_ 2654486528 CBV_bit0_RepeatMessageRequestBit 0;
BA_ "GenSigTimeoutTime_SGW" SG_ 2654486528 CBV_bit0_RepeatMessageRequestBit 0;
BA_ "GenSigTimeoutTime_TCM" SG_ 2654486528 CBV_bit0_RepeatMessageRequestBit 0;
BA_ "GenSigTimeoutTime_AGSM" SG_ 2654486528 CBV_bit1 0;
BA_ "GenSigTimeoutTime_BCM" SG_ 2654486528 CBV_bit1 0;
BA_ "GenSigTimeoutTime_BSM" SG_ 2654486528 CBV_bit1 0;
BA_ "GenSigTimeoutTime_CADM" SG_ 2654486528 CBV_bit1 0;
BA_ "GenSigTimeoutTime_DMSM" SG_ 2654486528 CBV_bit1 0;
BA_ "GenSigTimeoutTime_DTCM" SG_ 2654486528 CBV_bit1 0;
BA_ "GenSigTimeoutTime_ECM" SG_ 2654486528 CBV_bit1 0;
BA_ "GenSigTimeoutTime_EVCU2" SG_ 2654486528 CBV_bit1 0;
BA_ "GenSigTimeoutTime_GNMM" SG_ 2654486528 CBV_bit1 0;
BA_ "GenSigTimeoutTime_HCP" SG_ 2654486528 CBV_bit1 0;
BA_ "GenSigTimeoutTime_IPC" SG_ 2654486528 CBV_bit1 0;
BA_ "GenSigTimeoutTime_RFHM" SG_ 2654486528 CBV_bit1 0;
BA_ "GenSigTimeoutTime_SGW" SG_ 2654486528 CBV_bit1 0;
BA_ "GenSigTimeoutTime_TCM" SG_ 2654486528 CBV_bit1 0;
BA_ "GenSigTimeoutTime_AGSM" SG_ 2654486528 CBV_bit2 0;
BA_ "GenSigTimeoutTime_BCM" SG_ 2654486528 CBV_bit2 0;
BA_ "GenSigTimeoutTime_BSM" SG_ 2654486528 CBV_bit2 0;
BA_ "GenSigTimeoutTime_CADM" SG_ 2654486528 CBV_bit2 0;
BA_ "GenSigTimeoutTime_DMSM" SG_ 2654486528 CBV_bit2 0;
BA_ "GenSigTimeoutTime_DTCM" SG_ 2654486528 CBV_bit2 0;
BA_ "GenSigTimeoutTime_ECM" SG_ 2654486528 CBV_bit2 0;
BA_ "GenSigTimeoutTime_EVCU2" SG_ 2654486528 CBV_bit2 0;
BA_ "GenSigTimeoutTime_GNMM" SG_ 2654486528 CBV_bit2 0;
BA_ "GenSigTimeoutTime_HCP" SG_ 2654486528 CBV_bit2 0;
BA_ "GenSigTimeoutTime_IPC" SG_ 2654486528 CBV_bit2 0;
BA_ "GenSigTimeoutTime_RFHM" SG_ 2654486528 CBV_bit2 0;
BA_ "GenSigTimeoutTime_SGW" SG_ 2654486528 CBV_bit2 0;
BA_ "GenSigTimeoutTime_TCM" SG_ 2654486528 CBV_bit2 0;
BA_ "GenSigTimeoutTime_AGSM" SG_ 2654486528 CBV_bit3_NMCoordinatorBit 0;
BA_ "GenSigTimeoutTime_BCM" SG_ 2654486528 CBV_bit3_NMCoordinatorBit 0;
BA_ "GenSigTimeoutTime_BSM" SG_ 2654486528 CBV_bit3_NMCoordinatorBit 0;
BA_ "GenSigTimeoutTime_CADM" SG_ 2654486528 CBV_bit3_NMCoordinatorBit 0;
BA_ "GenSigTimeoutTime_DMSM" SG_ 2654486528 CBV_bit3_NMCoordinatorBit 0;
BA_ "GenSigTimeoutTime_DTCM" SG_ 2654486528 CBV_bit3_NMCoordinatorBit 0;
BA_ "GenSigTimeoutTime_ECM" SG_ 2654486528 CBV_bit3_NMCoordinatorBit 0;
BA_ "GenSigTimeoutTime_EVCU2" SG_ 2654486528 CBV_bit3_NMCoordinatorBit 0;
BA_ "GenSigTimeoutTime_GNMM" SG_ 2654486528 CBV_bit3_NMCoordinatorBit 0;
BA_ "GenSigTimeoutTime_HCP" SG_ 2654486528 CBV_bit3_NMCoordinatorBit 0;
BA_ "GenSigTimeoutTime_IPC" SG_ 2654486528 CBV_bit3_NMCoordinatorBit 0;
BA_ "GenSigTimeoutTime_RFHM" SG_ 2654486528 CBV_bit3_NMCoordinatorBit 0;
BA_ "GenSigTimeoutTime_SGW" SG_ 2654486528 CBV_bit3_NMCoordinatorBit 0;
BA_ "GenSigTimeoutTime_TCM" SG_ 2654486528 CBV_bit3_NMCoordinatorBit 0;
BA_ "GenSigTimeoutTime_AGSM" SG_ 2654486528 CBV_bit4_ActiveWakeupBit 0;
BA_ "GenSigTimeoutTime_BCM" SG_ 2654486528 CBV_bit4_ActiveWakeupBit 0;
BA_ "GenSigTimeoutTime_BSM" SG_ 2654486528 CBV_bit4_ActiveWakeupBit 0;
BA_ "GenSigTimeoutTime_CADM" SG_ 2654486528 CBV_bit4_ActiveWakeupBit 0;
BA_ "GenSigTimeoutTime_DMSM" SG_ 2654486528 CBV_bit4_ActiveWakeupBit 0;
BA_ "GenSigTimeoutTime_DTCM" SG_ 2654486528 CBV_bit4_ActiveWakeupBit 0;
BA_ "GenSigTimeoutTime_ECM" SG_ 2654486528 CBV_bit4_ActiveWakeupBit 0;
BA_ "GenSigTimeoutTime_EVCU2" SG_ 2654486528 CBV_bit4_ActiveWakeupBit 0;
BA_ "GenSigTimeoutTime_GNMM" SG_ 2654486528 CBV_bit4_ActiveWakeupBit 0;
BA_ "GenSigTimeoutTime_HCP" SG_ 2654486528 CBV_bit4_ActiveWakeupBit 0;
BA_ "GenSigTimeoutTime_IPC" SG_ 2654486528 CBV_bit4_ActiveWakeupBit 0;
BA_ "GenSigTimeoutTime_RFHM" SG_ 2654486528 CBV_bit4_ActiveWakeupBit 0;
BA_ "GenSigTimeoutTime_SGW" SG_ 2654486528 CBV_bit4_ActiveWakeupBit 0;
BA_ "GenSigTimeoutTime_TCM" SG_ 2654486528 CBV_bit4_ActiveWakeupBit 0;
BA_ "GenSigTimeoutTime_AGSM" SG_ 2654486528 CBV_bit5 0;
BA_ "GenSigTimeoutTime_BCM" SG_ 2654486528 CBV_bit5 0;
BA_ "GenSigTimeoutTime_BSM" SG_ 2654486528 CBV_bit5 0;
BA_ "GenSigTimeoutTime_CADM" SG_ 2654486528 CBV_bit5 0;
BA_ "GenSigTimeoutTime_DMSM" SG_ 2654486528 CBV_bit5 0;
BA_ "GenSigTimeoutTime_DTCM" SG_ 2654486528 CBV_bit5 0;
BA_ "GenSigTimeoutTime_ECM" SG_ 2654486528 CBV_bit5 0;
BA_ "GenSigTimeoutTime_EVCU2" SG_ 2654486528 CBV_bit5 0;
BA_ "GenSigTimeoutTime_GNMM" SG_ 2654486528 CBV_bit5 0;
BA_ "GenSigTimeoutTime_HCP" SG_ 2654486528 CBV_bit5 0;
BA_ "GenSigTimeoutTime_IPC" SG_ 2654486528 CBV_bit5 0;
BA_ "GenSigTimeoutTime_RFHM" SG_ 2654486528 CBV_bit5 0;
BA_ "GenSigTimeoutTime_SGW" SG_ 2654486528 CBV_bit5 0;
BA_ "GenSigTimeoutTime_TCM" SG_ 2654486528 CBV_bit5 0;
BA_ "GenSigTimeoutTime_AGSM" SG_ 2654486528 CBV_bit6_PartialNtwInfBit 0;
BA_ "GenSigTimeoutTime_BCM" SG_ 2654486528 CBV_bit6_PartialNtwInfBit 0;
BA_ "GenSigTimeoutTime_BSM" SG_ 2654486528 CBV_bit6_PartialNtwInfBit 0;
BA_ "GenSigTimeoutTime_CADM" SG_ 2654486528 CBV_bit6_PartialNtwInfBit 0;
BA_ "GenSigTimeoutTime_DMSM" SG_ 2654486528 CBV_bit6_PartialNtwInfBit 0;
BA_ "GenSigTimeoutTime_DTCM" SG_ 2654486528 CBV_bit6_PartialNtwInfBit 0;
BA_ "GenSigTimeoutTime_ECM" SG_ 2654486528 CBV_bit6_PartialNtwInfBit 0;
BA_ "GenSigTimeoutTime_EVCU2" SG_ 2654486528 CBV_bit6_PartialNtwInfBit 0;
BA_ "GenSigTimeoutTime_GNMM" SG_ 2654486528 CBV_bit6_PartialNtwInfBit 0;
BA_ "GenSigTimeoutTime_HCP" SG_ 2654486528 CBV_bit6_PartialNtwInfBit 0;
BA_ "GenSigTimeoutTime_IPC" SG_ 2654486528 CBV_bit6_PartialNtwInfBit 0;
BA_ "GenSigTimeoutTime_RFHM" SG_ 2654486528 CBV_bit6_PartialNtwInfBit 0;
BA_ "GenSigTimeoutTime_SGW" SG_ 2654486528 CBV_bit6_PartialNtwInfBit 0;
BA_ "GenSigTimeoutTime_TCM" SG_ 2654486528 CBV_bit6_PartialNtwInfBit 0;
BA_ "GenSigTimeoutTime_AGSM" SG_ 2654486528 CBV_bit7 0;
BA_ "GenSigTimeoutTime_BCM" SG_ 2654486528 CBV_bit7 0;
BA_ "GenSigTimeoutTime_BSM" SG_ 2654486528 CBV_bit7 0;
BA_ "GenSigTimeoutTime_CADM" SG_ 2654486528 CBV_bit7 0;
BA_ "GenSigTimeoutTime_DMSM" SG_ 2654486528 CBV_bit7 0;
BA_ "GenSigTimeoutTime_DTCM" SG_ 2654486528 CBV_bit7 0;
BA_ "GenSigTimeoutTime_ECM" SG_ 2654486528 CBV_bit7 0;
BA_ "GenSigTimeoutTime_EVCU2" SG_ 2654486528 CBV_bit7 0;
BA_ "GenSigTimeoutTime_GNMM" SG_ 2654486528 CBV_bit7 0;
BA_ "GenSigTimeoutTime_HCP" SG_ 2654486528 CBV_bit7 0;
BA_ "GenSigTimeoutTime_IPC" SG_ 2654486528 CBV_bit7 0;
BA_ "GenSigTimeoutTime_RFHM" SG_ 2654486528 CBV_bit7 0;
BA_ "GenSigTimeoutTime_SGW" SG_ 2654486528 CBV_bit7 0;
BA_ "GenSigTimeoutTime_TCM" SG_ 2654486528 CBV_bit7 0;
BA_ "GenSigTimeoutTime_AGSM" SG_ 2654486528 SourceNodeIdentifier 0;
BA_ "GenSigTimeoutTime_BCM" SG_ 2654486528 SourceNodeIdentifier 0;
BA_ "GenSigTimeoutTime_BSM" SG_ 2654486528 SourceNodeIdentifier 0;
BA_ "GenSigTimeoutTime_CADM" SG_ 2654486528 SourceNodeIdentifier 0;
BA_ "GenSigTimeoutTime_DMSM" SG_ 2654486528 SourceNodeIdentifier 0;
BA_ "GenSigTimeoutTime_DTCM" SG_ 2654486528 SourceNodeIdentifier 0;
BA_ "GenSigTimeoutTime_ECM" SG_ 2654486528 SourceNodeIdentifier 0;
BA_ "GenSigTimeoutTime_EVCU2" SG_ 2654486528 SourceNodeIdentifier 0;
BA_ "GenSigTimeoutTime_GNMM" SG_ 2654486528 SourceNodeIdentifier 0;
BA_ "GenSigTimeoutTime_HCP" SG_ 2654486528 SourceNodeIdentifier 0;
BA_ "GenSigTimeoutTime_IPC" SG_ 2654486528 SourceNodeIdentifier 0;
BA_ "GenSigTimeoutTime_RFHM" SG_ 2654486528 SourceNodeIdentifier 0;
BA_ "GenSigTimeoutTime_SGW" SG_ 2654486528 SourceNodeIdentifier 0;
BA_ "GenSigTimeoutTime_TCM" SG_ 2654486528 SourceNodeIdentifier 0;
BA_ "GenSigTimeoutTime_AGSM" SG_ 2654486534 CBV_bit0_RepeatMessageRequestBit 0;
BA_ "GenSigTimeoutTime_BCM" SG_ 2654486534 CBV_bit0_RepeatMessageRequestBit 0;
BA_ "GenSigTimeoutTime_BSM" SG_ 2654486534 CBV_bit0_RepeatMessageRequestBit 0;
BA_ "GenSigTimeoutTime_CADM" SG_ 2654486534 CBV_bit0_RepeatMessageRequestBit 0;
BA_ "GenSigTimeoutTime_DMSM" SG_ 2654486534 CBV_bit0_RepeatMessageRequestBit 0;
BA_ "GenSigTimeoutTime_DTCM" SG_ 2654486534 CBV_bit0_RepeatMessageRequestBit 0;
BA_ "GenSigTimeoutTime_ECM" SG_ 2654486534 CBV_bit0_RepeatMessageRequestBit 0;
BA_ "GenSigTimeoutTime_EVCU2" SG_ 2654486534 CBV_bit0_RepeatMessageRequestBit 0;
BA_ "GenSigTimeoutTime_GNMM" SG_ 2654486534 CBV_bit0_RepeatMessageRequestBit 0;
BA_ "GenSigTimeoutTime_HCP" SG_ 2654486534 CBV_bit0_RepeatMessageRequestBit 0;
BA_ "GenSigTimeoutTime_IPC" SG_ 2654486534 CBV_bit0_RepeatMessageRequestBit 0;
BA_ "GenSigTimeoutTime_RFHM" SG_ 2654486534 CBV_bit0_RepeatMessageRequestBit 0;
BA_ "GenSigTimeoutTime_SGW" SG_ 2654486534 CBV_bit0_RepeatMessageRequestBit 0;
BA_ "GenSigTimeoutTime_TCM" SG_ 2654486534 CBV_bit0_RepeatMessageRequestBit 0;
BA_ "GenSigTimeoutTime_AGSM" SG_ 2654486534 CBV_bit1 0;
BA_ "GenSigTimeoutTime_BCM" SG_ 2654486534 CBV_bit1 0;
BA_ "GenSigTimeoutTime_BSM" SG_ 2654486534 CBV_bit1 0;
BA_ "GenSigTimeoutTime_CADM" SG_ 2654486534 CBV_bit1 0;
BA_ "GenSigTimeoutTime_DMSM" SG_ 2654486534 CBV_bit1 0;
BA_ "GenSigTimeoutTime_DTCM" SG_ 2654486534 CBV_bit1 0;
BA_ "GenSigTimeoutTime_ECM" SG_ 2654486534 CBV_bit1 0;
BA_ "GenSigTimeoutTime_EVCU2" SG_ 2654486534 CBV_bit1 0;
BA_ "GenSigTimeoutTime_GNMM" SG_ 2654486534 CBV_bit1 0;
BA_ "GenSigTimeoutTime_HCP" SG_ 2654486534 CBV_bit1 0;
BA_ "GenSigTimeoutTime_IPC" SG_ 2654486534 CBV_bit1 0;
BA_ "GenSigTimeoutTime_RFHM" SG_ 2654486534 CBV_bit1 0;
BA_ "GenSigTimeoutTime_SGW" SG_ 2654486534 CBV_bit1 0;
BA_ "GenSigTimeoutTime_TCM" SG_ 2654486534 CBV_bit1 0;
BA_ "GenSigTimeoutTime_AGSM" SG_ 2654486534 CBV_bit2 0;
BA_ "GenSigTimeoutTime_BCM" SG_ 2654486534 CBV_bit2 0;
BA_ "GenSigTimeoutTime_BSM" SG_ 2654486534 CBV_bit2 0;
BA_ "GenSigTimeoutTime_CADM" SG_ 2654486534 CBV_bit2 0;
BA_ "GenSigTimeoutTime_DMSM" SG_ 2654486534 CBV_bit2 0;
BA_ "GenSigTimeoutTime_DTCM" SG_ 2654486534 CBV_bit2 0;
BA_ "GenSigTimeoutTime_ECM" SG_ 2654486534 CBV_bit2 0;
BA_ "GenSigTimeoutTime_EVCU2" SG_ 2654486534 CBV_bit2 0;
BA_ "GenSigTimeoutTime_GNMM" SG_ 2654486534 CBV_bit2 0;
BA_ "GenSigTimeoutTime_HCP" SG_ 2654486534 CBV_bit2 0;
BA_ "GenSigTimeoutTime_IPC" SG_ 2654486534 CBV_bit2 0;
BA_ "GenSigTimeoutTime_RFHM" SG_ 2654486534 CBV_bit2 0;
BA_ "GenSigTimeoutTime_SGW" SG_ 2654486534 CBV_bit2 0;
BA_ "GenSigTimeoutTime_TCM" SG_ 2654486534 CBV_bit2 0;
BA_ "GenSigTimeoutTime_AGSM" SG_ 2654486534 CBV_bit3_NMCoordinatorBit 0;
BA_ "GenSigTimeoutTime_BCM" SG_ 2654486534 CBV_bit3_NMCoordinatorBit 0;
BA_ "GenSigTimeoutTime_BSM" SG_ 2654486534 CBV_bit3_NMCoordinatorBit 0;
BA_ "GenSigTimeoutTime_CADM" SG_ 2654486534 CBV_bit3_NMCoordinatorBit 0;
BA_ "GenSigTimeoutTime_DMSM" SG_ 2654486534 CBV_bit3_NMCoordinatorBit 0;
BA_ "GenSigTimeoutTime_DTCM" SG_ 2654486534 CBV_bit3_NMCoordinatorBit 0;
BA_ "GenSigTimeoutTime_ECM" SG_ 2654486534 CBV_bit3_NMCoordinatorBit 0;
BA_ "GenSigTimeoutTime_EVCU2" SG_ 2654486534 CBV_bit3_NMCoordinatorBit 0;
BA_ "GenSigTimeoutTime_GNMM" SG_ 2654486534 CBV_bit3_NMCoordinatorBit 0;
BA_ "GenSigTimeoutTime_HCP" SG_ 2654486534 CBV_bit3_NMCoordinatorBit 0;
BA_ "GenSigTimeoutTime_IPC" SG_ 2654486534 CBV_bit3_NMCoordinatorBit 0;
BA_ "GenSigTimeoutTime_RFHM" SG_ 2654486534 CBV_bit3_NMCoordinatorBit 0;
BA_ "GenSigTimeoutTime_SGW" SG_ 2654486534 CBV_bit3_NMCoordinatorBit 0;
BA_ "GenSigTimeoutTime_TCM" SG_ 2654486534 CBV_bit3_NMCoordinatorBit 0;
BA_ "GenSigTimeoutTime_AGSM" SG_ 2654486534 CBV_bit4_ActiveWakeupBit 0;
BA_ "GenSigTimeoutTime_BCM" SG_ 2654486534 CBV_bit4_ActiveWakeupBit 0;
BA_ "GenSigTimeoutTime_BSM" SG_ 2654486534 CBV_bit4_ActiveWakeupBit 0;
BA_ "GenSigTimeoutTime_CADM" SG_ 2654486534 CBV_bit4_ActiveWakeupBit 0;
BA_ "GenSigTimeoutTime_DMSM" SG_ 2654486534 CBV_bit4_ActiveWakeupBit 0;
BA_ "GenSigTimeoutTime_DTCM" SG_ 2654486534 CBV_bit4_ActiveWakeupBit 0;
BA_ "GenSigTimeoutTime_ECM" SG_ 2654486534 CBV_bit4_ActiveWakeupBit 0;
BA_ "GenSigTimeoutTime_EVCU2" SG_ 2654486534 CBV_bit4_ActiveWakeupBit 0;
BA_ "GenSigTimeoutTime_GNMM" SG_ 2654486534 CBV_bit4_ActiveWakeupBit 0;
BA_ "GenSigTimeoutTime_HCP" SG_ 2654486534 CBV_bit4_ActiveWakeupBit 0;
BA_ "GenSigTimeoutTime_IPC" SG_ 2654486534 CBV_bit4_ActiveWakeupBit 0;
BA_ "GenSigTimeoutTime_RFHM" SG_ 2654486534 CBV_bit4_ActiveWakeupBit 0;
BA_ "GenSigTimeoutTime_SGW" SG_ 2654486534 CBV_bit4_ActiveWakeupBit 0;
BA_ "GenSigTimeoutTime_TCM" SG_ 2654486534 CBV_bit4_ActiveWakeupBit 0;
BA_ "GenSigTimeoutTime_AGSM" SG_ 2654486534 CBV_bit5 0;
BA_ "GenSigTimeoutTime_BCM" SG_ 2654486534 CBV_bit5 0;
BA_ "GenSigTimeoutTime_BSM" SG_ 2654486534 CBV_bit5 0;
BA_ "GenSigTimeoutTime_CADM" SG_ 2654486534 CBV_bit5 0;
BA_ "GenSigTimeoutTime_DMSM" SG_ 2654486534 CBV_bit5 0;
BA_ "GenSigTimeoutTime_DTCM" SG_ 2654486534 CBV_bit5 0;
BA_ "GenSigTimeoutTime_ECM" SG_ 2654486534 CBV_bit5 0;
BA_ "GenSigTimeoutTime_EVCU2" SG_ 2654486534 CBV_bit5 0;
BA_ "GenSigTimeoutTime_GNMM" SG_ 2654486534 CBV_bit5 0;
BA_ "GenSigTimeoutTime_HCP" SG_ 2654486534 CBV_bit5 0;
BA_ "GenSigTimeoutTime_IPC" SG_ 2654486534 CBV_bit5 0;
BA_ "GenSigTimeoutTime_RFHM" SG_ 2654486534 CBV_bit5 0;
BA_ "GenSigTimeoutTime_SGW" SG_ 2654486534 CBV_bit5 0;
BA_ "GenSigTimeoutTime_TCM" SG_ 2654486534 CBV_bit5 0;
BA_ "GenSigTimeoutTime_AGSM" SG_ 2654486534 CBV_bit6_PartialNtwInfBit 0;
BA_ "GenSigTimeoutTime_BCM" SG_ 2654486534 CBV_bit6_PartialNtwInfBit 0;
BA_ "GenSigTimeoutTime_BSM" SG_ 2654486534 CBV_bit6_PartialNtwInfBit 0;
BA_ "GenSigTimeoutTime_CADM" SG_ 2654486534 CBV_bit6_PartialNtwInfBit 0;
BA_ "GenSigTimeoutTime_DMSM" SG_ 2654486534 CBV_bit6_PartialNtwInfBit 0;
BA_ "GenSigTimeoutTime_DTCM" SG_ 2654486534 CBV_bit6_PartialNtwInfBit 0;
BA_ "GenSigTimeoutTime_ECM" SG_ 2654486534 CBV_bit6_PartialNtwInfBit 0;
BA_ "GenSigTimeoutTime_EVCU2" SG_ 2654486534 CBV_bit6_PartialNtwInfBit 0;
BA_ "GenSigTimeoutTime_GNMM" SG_ 2654486534 CBV_bit6_PartialNtwInfBit 0;
BA_ "GenSigTimeoutTime_HCP" SG_ 2654486534 CBV_bit6_PartialNtwInfBit 0;
BA_ "GenSigTimeoutTime_IPC" SG_ 2654486534 CBV_bit6_PartialNtwInfBit 0;
BA_ "GenSigTimeoutTime_RFHM" SG_ 2654486534 CBV_bit6_PartialNtwInfBit 0;
BA_ "GenSigTimeoutTime_SGW" SG_ 2654486534 CBV_bit6_PartialNtwInfBit 0;
BA_ "GenSigTimeoutTime_TCM" SG_ 2654486534 CBV_bit6_PartialNtwInfBit 0;
BA_ "GenSigTimeoutTime_AGSM" SG_ 2654486534 CBV_bit7 0;
BA_ "GenSigTimeoutTime_BCM" SG_ 2654486534 CBV_bit7 0;
BA_ "GenSigTimeoutTime_BSM" SG_ 2654486534 CBV_bit7 0;
BA_ "GenSigTimeoutTime_CADM" SG_ 2654486534 CBV_bit7 0;
BA_ "GenSigTimeoutTime_DMSM" SG_ 2654486534 CBV_bit7 0;
BA_ "GenSigTimeoutTime_DTCM" SG_ 2654486534 CBV_bit7 0;
BA_ "GenSigTimeoutTime_ECM" SG_ 2654486534 CBV_bit7 0;
BA_ "GenSigTimeoutTime_EVCU2" SG_ 2654486534 CBV_bit7 0;
BA_ "GenSigTimeoutTime_GNMM" SG_ 2654486534 CBV_bit7 0;
BA_ "GenSigTimeoutTime_HCP" SG_ 2654486534 CBV_bit7 0;
BA_ "GenSigTimeoutTime_IPC" SG_ 2654486534 CBV_bit7 0;
BA_ "GenSigTimeoutTime_RFHM" SG_ 2654486534 CBV_bit7 0;
BA_ "GenSigTimeoutTime_SGW" SG_ 2654486534 CBV_bit7 0;
BA_ "GenSigTimeoutTime_TCM" SG_ 2654486534 CBV_bit7 0;
BA_ "GenSigTimeoutTime_AGSM" SG_ 2654486534 SourceNodeIdentifier 0;
BA_ "GenSigTimeoutTime_BCM" SG_ 2654486534 SourceNodeIdentifier 0;
BA_ "GenSigTimeoutTime_BSM" SG_ 2654486534 SourceNodeIdentifier 0;
BA_ "GenSigTimeoutTime_CADM" SG_ 2654486534 SourceNodeIdentifier 0;
BA_ "GenSigTimeoutTime_DMSM" SG_ 2654486534 SourceNodeIdentifier 0;
BA_ "GenSigTimeoutTime_DTCM" SG_ 2654486534 SourceNodeIdentifier 0;
BA_ "GenSigTimeoutTime_ECM" SG_ 2654486534 SourceNodeIdentifier 0;
BA_ "GenSigTimeoutTime_EVCU2" SG_ 2654486534 SourceNodeIdentifier 0;
BA_ "GenSigTimeoutTime_GNMM" SG_ 2654486534 SourceNodeIdentifier 0;
BA_ "GenSigTimeoutTime_HCP" SG_ 2654486534 SourceNodeIdentifier 0;
BA_ "GenSigTimeoutTime_IPC" SG_ 2654486534 SourceNodeIdentifier 0;
BA_ "GenSigTimeoutTime_RFHM" SG_ 2654486534 SourceNodeIdentifier 0;
BA_ "GenSigTimeoutTime_SGW" SG_ 2654486534 SourceNodeIdentifier 0;
BA_ "GenSigTimeoutTime_TCM" SG_ 2654486534 SourceNodeIdentifier 0;
BA_ "GenSigTimeoutTime_AGSM" SG_ 2654486669 CBV_bit0_RepeatMessageRequestBit 0;
BA_ "GenSigTimeoutTime_BCM" SG_ 2654486669 CBV_bit0_RepeatMessageRequestBit 0;
BA_ "GenSigTimeoutTime_BSM" SG_ 2654486669 CBV_bit0_RepeatMessageRequestBit 0;
BA_ "GenSigTimeoutTime_CADM" SG_ 2654486669 CBV_bit0_RepeatMessageRequestBit 0;
BA_ "GenSigTimeoutTime_DMSM" SG_ 2654486669 CBV_bit0_RepeatMessageRequestBit 0;
BA_ "GenSigTimeoutTime_DTCM" SG_ 2654486669 CBV_bit0_RepeatMessageRequestBit 0;
BA_ "GenSigTimeoutTime_ECM" SG_ 2654486669 CBV_bit0_RepeatMessageRequestBit 0;
BA_ "GenSigTimeoutTime_EVCU2" SG_ 2654486669 CBV_bit0_RepeatMessageRequestBit 0;
BA_ "GenSigTimeoutTime_GNMM" SG_ 2654486669 CBV_bit0_RepeatMessageRequestBit 0;
BA_ "GenSigTimeoutTime_HCP" SG_ 2654486669 CBV_bit0_RepeatMessageRequestBit 0;
BA_ "GenSigTimeoutTime_IPC" SG_ 2654486669 CBV_bit0_RepeatMessageRequestBit 0;
BA_ "GenSigTimeoutTime_RFHM" SG_ 2654486669 CBV_bit0_RepeatMessageRequestBit 0;
BA_ "GenSigTimeoutTime_SGW" SG_ 2654486669 CBV_bit0_RepeatMessageRequestBit 0;
BA_ "GenSigTimeoutTime_TCM" SG_ 2654486669 CBV_bit0_RepeatMessageRequestBit 0;
BA_ "GenSigTimeoutTime_AGSM" SG_ 2654486669 CBV_bit1 0;
BA_ "GenSigTimeoutTime_BCM" SG_ 2654486669 CBV_bit1 0;
BA_ "GenSigTimeoutTime_BSM" SG_ 2654486669 CBV_bit1 0;
BA_ "GenSigTimeoutTime_CADM" SG_ 2654486669 CBV_bit1 0;
BA_ "GenSigTimeoutTime_DMSM" SG_ 2654486669 CBV_bit1 0;
BA_ "GenSigTimeoutTime_DTCM" SG_ 2654486669 CBV_bit1 0;
BA_ "GenSigTimeoutTime_ECM" SG_ 2654486669 CBV_bit1 0;
BA_ "GenSigTimeoutTime_EVCU2" SG_ 2654486669 CBV_bit1 0;
BA_ "GenSigTimeoutTime_GNMM" SG_ 2654486669 CBV_bit1 0;
BA_ "GenSigTimeoutTime_HCP" SG_ 2654486669 CBV_bit1 0;
BA_ "GenSigTimeoutTime_IPC" SG_ 2654486669 CBV_bit1 0;
BA_ "GenSigTimeoutTime_RFHM" SG_ 2654486669 CBV_bit1 0;
BA_ "GenSigTimeoutTime_SGW" SG_ 2654486669 CBV_bit1 0;
BA_ "GenSigTimeoutTime_TCM" SG_ 2654486669 CBV_bit1 0;
BA_ "GenSigTimeoutTime_AGSM" SG_ 2654486669 CBV_bit2 0;
BA_ "GenSigTimeoutTime_BCM" SG_ 2654486669 CBV_bit2 0;
BA_ "GenSigTimeoutTime_BSM" SG_ 2654486669 CBV_bit2 0;
BA_ "GenSigTimeoutTime_CADM" SG_ 2654486669 CBV_bit2 0;
BA_ "GenSigTimeoutTime_DMSM" SG_ 2654486669 CBV_bit2 0;
BA_ "GenSigTimeoutTime_DTCM" SG_ 2654486669 CBV_bit2 0;
BA_ "GenSigTimeoutTime_ECM" SG_ 2654486669 CBV_bit2 0;
BA_ "GenSigTimeoutTime_EVCU2" SG_ 2654486669 CBV_bit2 0;
BA_ "GenSigTimeoutTime_GNMM" SG_ 2654486669 CBV_bit2 0;
BA_ "GenSigTimeoutTime_HCP" SG_ 2654486669 CBV_bit2 0;
BA_ "GenSigTimeoutTime_IPC" SG_ 2654486669 CBV_bit2 0;
BA_ "GenSigTimeoutTime_RFHM" SG_ 2654486669 CBV_bit2 0;
BA_ "GenSigTimeoutTime_SGW" SG_ 2654486669 CBV_bit2 0;
BA_ "GenSigTimeoutTime_TCM" SG_ 2654486669 CBV_bit2 0;
BA_ "GenSigTimeoutTime_AGSM" SG_ 2654486669 CBV_bit3_NMCoordinatorBit 0;
BA_ "GenSigTimeoutTime_BCM" SG_ 2654486669 CBV_bit3_NMCoordinatorBit 0;
BA_ "GenSigTimeoutTime_BSM" SG_ 2654486669 CBV_bit3_NMCoordinatorBit 0;
BA_ "GenSigTimeoutTime_CADM" SG_ 2654486669 CBV_bit3_NMCoordinatorBit 0;
BA_ "GenSigTimeoutTime_DMSM" SG_ 2654486669 CBV_bit3_NMCoordinatorBit 0;
BA_ "GenSigTimeoutTime_DTCM" SG_ 2654486669 CBV_bit3_NMCoordinatorBit 0;
BA_ "GenSigTimeoutTime_ECM" SG_ 2654486669 CBV_bit3_NMCoordinatorBit 0;
BA_ "GenSigTimeoutTime_EVCU2" SG_ 2654486669 CBV_bit3_NMCoordinatorBit 0;
BA_ "GenSigTimeoutTime_GNMM" SG_ 2654486669 CBV_bit3_NMCoordinatorBit 0;
BA_ "GenSigTimeoutTime_HCP" SG_ 2654486669 CBV_bit3_NMCoordinatorBit 0;
BA_ "GenSigTimeoutTime_IPC" SG_ 2654486669 CBV_bit3_NMCoordinatorBit 0;
BA_ "GenSigTimeoutTime_RFHM" SG_ 2654486669 CBV_bit3_NMCoordinatorBit 0;
BA_ "GenSigTimeoutTime_SGW" SG_ 2654486669 CBV_bit3_NMCoordinatorBit 0;
BA_ "GenSigTimeoutTime_TCM" SG_ 2654486669 CBV_bit3_NMCoordinatorBit 0;
BA_ "GenSigTimeoutTime_AGSM" SG_ 2654486669 CBV_bit4_ActiveWakeupBit 0;
BA_ "GenSigTimeoutTime_BCM" SG_ 2654486669 CBV_bit4_ActiveWakeupBit 0;
BA_ "GenSigTimeoutTime_BSM" SG_ 2654486669 CBV_bit4_ActiveWakeupBit 0;
BA_ "GenSigTimeoutTime_CADM" SG_ 2654486669 CBV_bit4_ActiveWakeupBit 0;
BA_ "GenSigTimeoutTime_DMSM" SG_ 2654486669 CBV_bit4_ActiveWakeupBit 0;
BA_ "GenSigTimeoutTime_DTCM" SG_ 2654486669 CBV_bit4_ActiveWakeupBit 0;
BA_ "GenSigTimeoutTime_ECM" SG_ 2654486669 CBV_bit4_ActiveWakeupBit 0;
BA_ "GenSigTimeoutTime_EVCU2" SG_ 2654486669 CBV_bit4_ActiveWakeupBit 0;
BA_ "GenSigTimeoutTime_GNMM" SG_ 2654486669 CBV_bit4_ActiveWakeupBit 0;
BA_ "GenSigTimeoutTime_HCP" SG_ 2654486669 CBV_bit4_ActiveWakeupBit 0;
BA_ "GenSigTimeoutTime_IPC" SG_ 2654486669 CBV_bit4_ActiveWakeupBit 0;
BA_ "GenSigTimeoutTime_RFHM" SG_ 2654486669 CBV_bit4_ActiveWakeupBit 0;
BA_ "GenSigTimeoutTime_SGW" SG_ 2654486669 CBV_bit4_ActiveWakeupBit 0;
BA_ "GenSigTimeoutTime_TCM" SG_ 2654486669 CBV_bit4_ActiveWakeupBit 0;
BA_ "GenSigTimeoutTime_AGSM" SG_ 2654486669 CBV_bit5 0;
BA_ "GenSigTimeoutTime_BCM" SG_ 2654486669 CBV_bit5 0;
BA_ "GenSigTimeoutTime_BSM" SG_ 2654486669 CBV_bit5 0;
BA_ "GenSigTimeoutTime_CADM" SG_ 2654486669 CBV_bit5 0;
BA_ "GenSigTimeoutTime_DMSM" SG_ 2654486669 CBV_bit5 0;
BA_ "GenSigTimeoutTime_DTCM" SG_ 2654486669 CBV_bit5 0;
BA_ "GenSigTimeoutTime_ECM" SG_ 2654486669 CBV_bit5 0;
BA_ "GenSigTimeoutTime_EVCU2" SG_ 2654486669 CBV_bit5 0;
BA_ "GenSigTimeoutTime_GNMM" SG_ 2654486669 CBV_bit5 0;
BA_ "GenSigTimeoutTime_HCP" SG_ 2654486669 CBV_bit5 0;
BA_ "GenSigTimeoutTime_IPC" SG_ 2654486669 CBV_bit5 0;
BA_ "GenSigTimeoutTime_RFHM" SG_ 2654486669 CBV_bit5 0;
BA_ "GenSigTimeoutTime_SGW" SG_ 2654486669 CBV_bit5 0;
BA_ "GenSigTimeoutTime_TCM" SG_ 2654486669 CBV_bit5 0;
BA_ "GenSigTimeoutTime_AGSM" SG_ 2654486669 CBV_bit6_PartialNtwInfBit 0;
BA_ "GenSigTimeoutTime_BCM" SG_ 2654486669 CBV_bit6_PartialNtwInfBit 0;
BA_ "GenSigTimeoutTime_BSM" SG_ 2654486669 CBV_bit6_PartialNtwInfBit 0;
BA_ "GenSigTimeoutTime_CADM" SG_ 2654486669 CBV_bit6_PartialNtwInfBit 0;
BA_ "GenSigTimeoutTime_DMSM" SG_ 2654486669 CBV_bit6_PartialNtwInfBit 0;
BA_ "GenSigTimeoutTime_DTCM" SG_ 2654486669 CBV_bit6_PartialNtwInfBit 0;
BA_ "GenSigTimeoutTime_ECM" SG_ 2654486669 CBV_bit6_PartialNtwInfBit 0;
BA_ "GenSigTimeoutTime_EVCU2" SG_ 2654486669 CBV_bit6_PartialNtwInfBit 0;
BA_ "GenSigTimeoutTime_GNMM" SG_ 2654486669 CBV_bit6_PartialNtwInfBit 0;
BA_ "GenSigTimeoutTime_HCP" SG_ 2654486669 CBV_bit6_PartialNtwInfBit 0;
BA_ "GenSigTimeoutTime_IPC" SG_ 2654486669 CBV_bit6_PartialNtwInfBit 0;
BA_ "GenSigTimeoutTime_RFHM" SG_ 2654486669 CBV_bit6_PartialNtwInfBit 0;
BA_ "GenSigTimeoutTime_SGW" SG_ 2654486669 CBV_bit6_PartialNtwInfBit 0;
BA_ "GenSigTimeoutTime_TCM" SG_ 2654486669 CBV_bit6_PartialNtwInfBit 0;
BA_ "GenSigTimeoutTime_AGSM" SG_ 2654486669 CBV_bit7 0;
BA_ "GenSigTimeoutTime_BCM" SG_ 2654486669 CBV_bit7 0;
BA_ "GenSigTimeoutTime_BSM" SG_ 2654486669 CBV_bit7 0;
BA_ "GenSigTimeoutTime_CADM" SG_ 2654486669 CBV_bit7 0;
BA_ "GenSigTimeoutTime_DMSM" SG_ 2654486669 CBV_bit7 0;
BA_ "GenSigTimeoutTime_DTCM" SG_ 2654486669 CBV_bit7 0;
BA_ "GenSigTimeoutTime_ECM" SG_ 2654486669 CBV_bit7 0;
BA_ "GenSigTimeoutTime_EVCU2" SG_ 2654486669 CBV_bit7 0;
BA_ "GenSigTimeoutTime_GNMM" SG_ 2654486669 CBV_bit7 0;
BA_ "GenSigTimeoutTime_HCP" SG_ 2654486669 CBV_bit7 0;
BA_ "GenSigTimeoutTime_IPC" SG_ 2654486669 CBV_bit7 0;
BA_ "GenSigTimeoutTime_RFHM" SG_ 2654486669 CBV_bit7 0;
BA_ "GenSigTimeoutTime_SGW" SG_ 2654486669 CBV_bit7 0;
BA_ "GenSigTimeoutTime_TCM" SG_ 2654486669 CBV_bit7 0;
BA_ "GenSigTimeoutTime_AGSM" SG_ 2654486669 SourceNodeIdentifier 0;
BA_ "GenSigTimeoutTime_BCM" SG_ 2654486669 SourceNodeIdentifier 0;
BA_ "GenSigTimeoutTime_BSM" SG_ 2654486669 SourceNodeIdentifier 0;
BA_ "GenSigTimeoutTime_CADM" SG_ 2654486669 SourceNodeIdentifier 0;
BA_ "GenSigTimeoutTime_DMSM" SG_ 2654486669 SourceNodeIdentifier 0;
BA_ "GenSigTimeoutTime_DTCM" SG_ 2654486669 SourceNodeIdentifier 0;
BA_ "GenSigTimeoutTime_ECM" SG_ 2654486669 SourceNodeIdentifier 0;
BA_ "GenSigTimeoutTime_EVCU2" SG_ 2654486669 SourceNodeIdentifier 0;
BA_ "GenSigTimeoutTime_GNMM" SG_ 2654486669 SourceNodeIdentifier 0;
BA_ "GenSigTimeoutTime_HCP" SG_ 2654486669 SourceNodeIdentifier 0;
BA_ "GenSigTimeoutTime_IPC" SG_ 2654486669 SourceNodeIdentifier 0;
BA_ "GenSigTimeoutTime_RFHM" SG_ 2654486669 SourceNodeIdentifier 0;
BA_ "GenSigTimeoutTime_SGW" SG_ 2654486669 SourceNodeIdentifier 0;
BA_ "GenSigTimeoutTime_TCM" SG_ 2654486669 SourceNodeIdentifier 0;
BA_ "GenSigTimeoutTime_AGSM" SG_ 2654486595 CBV_bit0_RepeatMessageRequestBit 0;
BA_ "GenSigTimeoutTime_BCM" SG_ 2654486595 CBV_bit0_RepeatMessageRequestBit 0;
BA_ "GenSigTimeoutTime_BSM" SG_ 2654486595 CBV_bit0_RepeatMessageRequestBit 0;
BA_ "GenSigTimeoutTime_CADM" SG_ 2654486595 CBV_bit0_RepeatMessageRequestBit 0;
BA_ "GenSigTimeoutTime_DMSM" SG_ 2654486595 CBV_bit0_RepeatMessageRequestBit 0;
BA_ "GenSigTimeoutTime_DTCM" SG_ 2654486595 CBV_bit0_RepeatMessageRequestBit 0;
BA_ "GenSigTimeoutTime_ECM" SG_ 2654486595 CBV_bit0_RepeatMessageRequestBit 0;
BA_ "GenSigTimeoutTime_EVCU2" SG_ 2654486595 CBV_bit0_RepeatMessageRequestBit 0;
BA_ "GenSigTimeoutTime_GNMM" SG_ 2654486595 CBV_bit0_RepeatMessageRequestBit 0;
BA_ "GenSigTimeoutTime_HCP" SG_ 2654486595 CBV_bit0_RepeatMessageRequestBit 0;
BA_ "GenSigTimeoutTime_IPC" SG_ 2654486595 CBV_bit0_RepeatMessageRequestBit 0;
BA_ "GenSigTimeoutTime_RFHM" SG_ 2654486595 CBV_bit0_RepeatMessageRequestBit 0;
BA_ "GenSigTimeoutTime_SGW" SG_ 2654486595 CBV_bit0_RepeatMessageRequestBit 0;
BA_ "GenSigTimeoutTime_TCM" SG_ 2654486595 CBV_bit0_RepeatMessageRequestBit 0;
BA_ "GenSigTimeoutTime_AGSM" SG_ 2654486595 CBV_bit1 0;
BA_ "GenSigTimeoutTime_BCM" SG_ 2654486595 CBV_bit1 0;
BA_ "GenSigTimeoutTime_BSM" SG_ 2654486595 CBV_bit1 0;
BA_ "GenSigTimeoutTime_CADM" SG_ 2654486595 CBV_bit1 0;
BA_ "GenSigTimeoutTime_DMSM" SG_ 2654486595 CBV_bit1 0;
BA_ "GenSigTimeoutTime_DTCM" SG_ 2654486595 CBV_bit1 0;
BA_ "GenSigTimeoutTime_ECM" SG_ 2654486595 CBV_bit1 0;
BA_ "GenSigTimeoutTime_EVCU2" SG_ 2654486595 CBV_bit1 0;
BA_ "GenSigTimeoutTime_GNMM" SG_ 2654486595 CBV_bit1 0;
BA_ "GenSigTimeoutTime_HCP" SG_ 2654486595 CBV_bit1 0;
BA_ "GenSigTimeoutTime_IPC" SG_ 2654486595 CBV_bit1 0;
BA_ "GenSigTimeoutTime_RFHM" SG_ 2654486595 CBV_bit1 0;
BA_ "GenSigTimeoutTime_SGW" SG_ 2654486595 CBV_bit1 0;
BA_ "GenSigTimeoutTime_TCM" SG_ 2654486595 CBV_bit1 0;
BA_ "GenSigTimeoutTime_AGSM" SG_ 2654486595 CBV_bit2 0;
BA_ "GenSigTimeoutTime_BCM" SG_ 2654486595 CBV_bit2 0;
BA_ "GenSigTimeoutTime_BSM" SG_ 2654486595 CBV_bit2 0;
BA_ "GenSigTimeoutTime_CADM" SG_ 2654486595 CBV_bit2 0;
BA_ "GenSigTimeoutTime_DMSM" SG_ 2654486595 CBV_bit2 0;
BA_ "GenSigTimeoutTime_DTCM" SG_ 2654486595 CBV_bit2 0;
BA_ "GenSigTimeoutTime_ECM" SG_ 2654486595 CBV_bit2 0;
BA_ "GenSigTimeoutTime_EVCU2" SG_ 2654486595 CBV_bit2 0;
BA_ "GenSigTimeoutTime_GNMM" SG_ 2654486595 CBV_bit2 0;
BA_ "GenSigTimeoutTime_HCP" SG_ 2654486595 CBV_bit2 0;
BA_ "GenSigTimeoutTime_IPC" SG_ 2654486595 CBV_bit2 0;
BA_ "GenSigTimeoutTime_RFHM" SG_ 2654486595 CBV_bit2 0;
BA_ "GenSigTimeoutTime_SGW" SG_ 2654486595 CBV_bit2 0;
BA_ "GenSigTimeoutTime_TCM" SG_ 2654486595 CBV_bit2 0;
BA_ "GenSigTimeoutTime_AGSM" SG_ 2654486595 CBV_bit3_NMCoordinatorBit 0;
BA_ "GenSigTimeoutTime_BCM" SG_ 2654486595 CBV_bit3_NMCoordinatorBit 0;
BA_ "GenSigTimeoutTime_BSM" SG_ 2654486595 CBV_bit3_NMCoordinatorBit 0;
BA_ "GenSigTimeoutTime_CADM" SG_ 2654486595 CBV_bit3_NMCoordinatorBit 0;
BA_ "GenSigTimeoutTime_DMSM" SG_ 2654486595 CBV_bit3_NMCoordinatorBit 0;
BA_ "GenSigTimeoutTime_DTCM" SG_ 2654486595 CBV_bit3_NMCoordinatorBit 0;
BA_ "GenSigTimeoutTime_ECM" SG_ 2654486595 CBV_bit3_NMCoordinatorBit 0;
BA_ "GenSigTimeoutTime_EVCU2" SG_ 2654486595 CBV_bit3_NMCoordinatorBit 0;
BA_ "GenSigTimeoutTime_GNMM" SG_ 2654486595 CBV_bit3_NMCoordinatorBit 0;
BA_ "GenSigTimeoutTime_HCP" SG_ 2654486595 CBV_bit3_NMCoordinatorBit 0;
BA_ "GenSigTimeoutTime_IPC" SG_ 2654486595 CBV_bit3_NMCoordinatorBit 0;
BA_ "GenSigTimeoutTime_RFHM" SG_ 2654486595 CBV_bit3_NMCoordinatorBit 0;
BA_ "GenSigTimeoutTime_SGW" SG_ 2654486595 CBV_bit3_NMCoordinatorBit 0;
BA_ "GenSigTimeoutTime_TCM" SG_ 2654486595 CBV_bit3_NMCoordinatorBit 0;
BA_ "GenSigTimeoutTime_AGSM" SG_ 2654486595 CBV_bit4_ActiveWakeupBit 0;
BA_ "GenSigTimeoutTime_BCM" SG_ 2654486595 CBV_bit4_ActiveWakeupBit 0;
BA_ "GenSigTimeoutTime_BSM" SG_ 2654486595 CBV_bit4_ActiveWakeupBit 0;
BA_ "GenSigTimeoutTime_CADM" SG_ 2654486595 CBV_bit4_ActiveWakeupBit 0;
BA_ "GenSigTimeoutTime_DMSM" SG_ 2654486595 CBV_bit4_ActiveWakeupBit 0;
BA_ "GenSigTimeoutTime_DTCM" SG_ 2654486595 CBV_bit4_ActiveWakeupBit 0;
BA_ "GenSigTimeoutTime_ECM" SG_ 2654486595 CBV_bit4_ActiveWakeupBit 0;
BA_ "GenSigTimeoutTime_EVCU2" SG_ 2654486595 CBV_bit4_ActiveWakeupBit 0;
BA_ "GenSigTimeoutTime_GNMM" SG_ 2654486595 CBV_bit4_ActiveWakeupBit 0;
BA_ "GenSigTimeoutTime_HCP" SG_ 2654486595 CBV_bit4_ActiveWakeupBit 0;
BA_ "GenSigTimeoutTime_IPC" SG_ 2654486595 CBV_bit4_ActiveWakeupBit 0;
BA_ "GenSigTimeoutTime_RFHM" SG_ 2654486595 CBV_bit4_ActiveWakeupBit 0;
BA_ "GenSigTimeoutTime_SGW" SG_ 2654486595 CBV_bit4_ActiveWakeupBit 0;
BA_ "GenSigTimeoutTime_TCM" SG_ 2654486595 CBV_bit4_ActiveWakeupBit 0;
BA_ "GenSigTimeoutTime_AGSM" SG_ 2654486595 CBV_bit5 0;
BA_ "GenSigTimeoutTime_BCM" SG_ 2654486595 CBV_bit5 0;
BA_ "GenSigTimeoutTime_BSM" SG_ 2654486595 CBV_bit5 0;
BA_ "GenSigTimeoutTime_CADM" SG_ 2654486595 CBV_bit5 0;
BA_ "GenSigTimeoutTime_DMSM" SG_ 2654486595 CBV_bit5 0;
BA_ "GenSigTimeoutTime_DTCM" SG_ 2654486595 CBV_bit5 0;
BA_ "GenSigTimeoutTime_ECM" SG_ 2654486595 CBV_bit5 0;
BA_ "GenSigTimeoutTime_EVCU2" SG_ 2654486595 CBV_bit5 0;
BA_ "GenSigTimeoutTime_GNMM" SG_ 2654486595 CBV_bit5 0;
BA_ "GenSigTimeoutTime_HCP" SG_ 2654486595 CBV_bit5 0;
BA_ "GenSigTimeoutTime_IPC" SG_ 2654486595 CBV_bit5 0;
BA_ "GenSigTimeoutTime_RFHM" SG_ 2654486595 CBV_bit5 0;
BA_ "GenSigTimeoutTime_SGW" SG_ 2654486595 CBV_bit5 0;
BA_ "GenSigTimeoutTime_TCM" SG_ 2654486595 CBV_bit5 0;
BA_ "GenSigTimeoutTime_AGSM" SG_ 2654486595 CBV_bit6_PartialNtwInfBit 0;
BA_ "GenSigTimeoutTime_BCM" SG_ 2654486595 CBV_bit6_PartialNtwInfBit 0;
BA_ "GenSigTimeoutTime_BSM" SG_ 2654486595 CBV_bit6_PartialNtwInfBit 0;
BA_ "GenSigTimeoutTime_CADM" SG_ 2654486595 CBV_bit6_PartialNtwInfBit 0;
BA_ "GenSigTimeoutTime_DMSM" SG_ 2654486595 CBV_bit6_PartialNtwInfBit 0;
BA_ "GenSigTimeoutTime_DTCM" SG_ 2654486595 CBV_bit6_PartialNtwInfBit 0;
BA_ "GenSigTimeoutTime_ECM" SG_ 2654486595 CBV_bit6_PartialNtwInfBit 0;
BA_ "GenSigTimeoutTime_EVCU2" SG_ 2654486595 CBV_bit6_PartialNtwInfBit 0;
BA_ "GenSigTimeoutTime_GNMM" SG_ 2654486595 CBV_bit6_PartialNtwInfBit 0;
BA_ "GenSigTimeoutTime_HCP" SG_ 2654486595 CBV_bit6_PartialNtwInfBit 0;
BA_ "GenSigTimeoutTime_IPC" SG_ 2654486595 CBV_bit6_PartialNtwInfBit 0;
BA_ "GenSigTimeoutTime_RFHM" SG_ 2654486595 CBV_bit6_PartialNtwInfBit 0;
BA_ "GenSigTimeoutTime_SGW" SG_ 2654486595 CBV_bit6_PartialNtwInfBit 0;
BA_ "GenSigTimeoutTime_TCM" SG_ 2654486595 CBV_bit6_PartialNtwInfBit 0;
BA_ "GenSigTimeoutTime_AGSM" SG_ 2654486595 CBV_bit7 0;
BA_ "GenSigTimeoutTime_BCM" SG_ 2654486595 CBV_bit7 0;
BA_ "GenSigTimeoutTime_BSM" SG_ 2654486595 CBV_bit7 0;
BA_ "GenSigTimeoutTime_CADM" SG_ 2654486595 CBV_bit7 0;
BA_ "GenSigTimeoutTime_DMSM" SG_ 2654486595 CBV_bit7 0;
BA_ "GenSigTimeoutTime_DTCM" SG_ 2654486595 CBV_bit7 0;
BA_ "GenSigTimeoutTime_ECM" SG_ 2654486595 CBV_bit7 0;
BA_ "GenSigTimeoutTime_EVCU2" SG_ 2654486595 CBV_bit7 0;
BA_ "GenSigTimeoutTime_GNMM" SG_ 2654486595 CBV_bit7 0;
BA_ "GenSigTimeoutTime_HCP" SG_ 2654486595 CBV_bit7 0;
BA_ "GenSigTimeoutTime_IPC" SG_ 2654486595 CBV_bit7 0;
BA_ "GenSigTimeoutTime_RFHM" SG_ 2654486595 CBV_bit7 0;
BA_ "GenSigTimeoutTime_SGW" SG_ 2654486595 CBV_bit7 0;
BA_ "GenSigTimeoutTime_TCM" SG_ 2654486595 CBV_bit7 0;
BA_ "GenSigTimeoutTime_AGSM" SG_ 2654486595 SourceNodeIdentifier 0;
BA_ "GenSigTimeoutTime_BCM" SG_ 2654486595 SourceNodeIdentifier 0;
BA_ "GenSigTimeoutTime_BSM" SG_ 2654486595 SourceNodeIdentifier 0;
BA_ "GenSigTimeoutTime_CADM" SG_ 2654486595 SourceNodeIdentifier 0;
BA_ "GenSigTimeoutTime_DMSM" SG_ 2654486595 SourceNodeIdentifier 0;
BA_ "GenSigTimeoutTime_DTCM" SG_ 2654486595 SourceNodeIdentifier 0;
BA_ "GenSigTimeoutTime_ECM" SG_ 2654486595 SourceNodeIdentifier 0;
BA_ "GenSigTimeoutTime_EVCU2" SG_ 2654486595 SourceNodeIdentifier 0;
BA_ "GenSigTimeoutTime_GNMM" SG_ 2654486595 SourceNodeIdentifier 0;
BA_ "GenSigTimeoutTime_HCP" SG_ 2654486595 SourceNodeIdentifier 0;
BA_ "GenSigTimeoutTime_IPC" SG_ 2654486595 SourceNodeIdentifier 0;
BA_ "GenSigTimeoutTime_RFHM" SG_ 2654486595 SourceNodeIdentifier 0;
BA_ "GenSigTimeoutTime_SGW" SG_ 2654486595 SourceNodeIdentifier 0;
BA_ "GenSigTimeoutTime_TCM" SG_ 2654486595 SourceNodeIdentifier 0;
BA_ "GenSigTimeoutTime_AGSM" SG_ 2654486529 CBV_bit0_RepeatMessageRequestBit 0;
BA_ "GenSigTimeoutTime_BCM" SG_ 2654486529 CBV_bit0_RepeatMessageRequestBit 0;
BA_ "GenSigTimeoutTime_BSM" SG_ 2654486529 CBV_bit0_RepeatMessageRequestBit 0;
BA_ "GenSigTimeoutTime_CADM" SG_ 2654486529 CBV_bit0_RepeatMessageRequestBit 0;
BA_ "GenSigTimeoutTime_DMSM" SG_ 2654486529 CBV_bit0_RepeatMessageRequestBit 0;
BA_ "GenSigTimeoutTime_DTCM" SG_ 2654486529 CBV_bit0_RepeatMessageRequestBit 0;
BA_ "GenSigTimeoutTime_ECM" SG_ 2654486529 CBV_bit0_RepeatMessageRequestBit 0;
BA_ "GenSigTimeoutTime_EVCU2" SG_ 2654486529 CBV_bit0_RepeatMessageRequestBit 0;
BA_ "GenSigTimeoutTime_GNMM" SG_ 2654486529 CBV_bit0_RepeatMessageRequestBit 0;
BA_ "GenSigTimeoutTime_HCP" SG_ 2654486529 CBV_bit0_RepeatMessageRequestBit 0;
BA_ "GenSigTimeoutTime_IPC" SG_ 2654486529 CBV_bit0_RepeatMessageRequestBit 0;
BA_ "GenSigTimeoutTime_RFHM" SG_ 2654486529 CBV_bit0_RepeatMessageRequestBit 0;
BA_ "GenSigTimeoutTime_SGW" SG_ 2654486529 CBV_bit0_RepeatMessageRequestBit 0;
BA_ "GenSigTimeoutTime_TCM" SG_ 2654486529 CBV_bit0_RepeatMessageRequestBit 0;
BA_ "GenSigTimeoutTime_AGSM" SG_ 2654486529 CBV_bit1 0;
BA_ "GenSigTimeoutTime_BCM" SG_ 2654486529 CBV_bit1 0;
BA_ "GenSigTimeoutTime_BSM" SG_ 2654486529 CBV_bit1 0;
BA_ "GenSigTimeoutTime_CADM" SG_ 2654486529 CBV_bit1 0;
BA_ "GenSigTimeoutTime_DMSM" SG_ 2654486529 CBV_bit1 0;
BA_ "GenSigTimeoutTime_DTCM" SG_ 2654486529 CBV_bit1 0;
BA_ "GenSigTimeoutTime_ECM" SG_ 2654486529 CBV_bit1 0;
BA_ "GenSigTimeoutTime_EVCU2" SG_ 2654486529 CBV_bit1 0;
BA_ "GenSigTimeoutTime_GNMM" SG_ 2654486529 CBV_bit1 0;
BA_ "GenSigTimeoutTime_HCP" SG_ 2654486529 CBV_bit1 0;
BA_ "GenSigTimeoutTime_IPC" SG_ 2654486529 CBV_bit1 0;
BA_ "GenSigTimeoutTime_RFHM" SG_ 2654486529 CBV_bit1 0;
BA_ "GenSigTimeoutTime_SGW" SG_ 2654486529 CBV_bit1 0;
BA_ "GenSigTimeoutTime_TCM" SG_ 2654486529 CBV_bit1 0;
BA_ "GenSigTimeoutTime_AGSM" SG_ 2654486529 CBV_bit2 0;
BA_ "GenSigTimeoutTime_BCM" SG_ 2654486529 CBV_bit2 0;
BA_ "GenSigTimeoutTime_BSM" SG_ 2654486529 CBV_bit2 0;
BA_ "GenSigTimeoutTime_CADM" SG_ 2654486529 CBV_bit2 0;
BA_ "GenSigTimeoutTime_DMSM" SG_ 2654486529 CBV_bit2 0;
BA_ "GenSigTimeoutTime_DTCM" SG_ 2654486529 CBV_bit2 0;
BA_ "GenSigTimeoutTime_ECM" SG_ 2654486529 CBV_bit2 0;
BA_ "GenSigTimeoutTime_EVCU2" SG_ 2654486529 CBV_bit2 0;
BA_ "GenSigTimeoutTime_GNMM" SG_ 2654486529 CBV_bit2 0;
BA_ "GenSigTimeoutTime_HCP" SG_ 2654486529 CBV_bit2 0;
BA_ "GenSigTimeoutTime_IPC" SG_ 2654486529 CBV_bit2 0;
BA_ "GenSigTimeoutTime_RFHM" SG_ 2654486529 CBV_bit2 0;
BA_ "GenSigTimeoutTime_SGW" SG_ 2654486529 CBV_bit2 0;
BA_ "GenSigTimeoutTime_TCM" SG_ 2654486529 CBV_bit2 0;
BA_ "GenSigTimeoutTime_AGSM" SG_ 2654486529 CBV_bit3_NMCoordinatorBit 0;
BA_ "GenSigTimeoutTime_BCM" SG_ 2654486529 CBV_bit3_NMCoordinatorBit 0;
BA_ "GenSigTimeoutTime_BSM" SG_ 2654486529 CBV_bit3_NMCoordinatorBit 0;
BA_ "GenSigTimeoutTime_CADM" SG_ 2654486529 CBV_bit3_NMCoordinatorBit 0;
BA_ "GenSigTimeoutTime_DMSM" SG_ 2654486529 CBV_bit3_NMCoordinatorBit 0;
BA_ "GenSigTimeoutTime_DTCM" SG_ 2654486529 CBV_bit3_NMCoordinatorBit 0;
BA_ "GenSigTimeoutTime_ECM" SG_ 2654486529 CBV_bit3_NMCoordinatorBit 0;
BA_ "GenSigTimeoutTime_EVCU2" SG_ 2654486529 CBV_bit3_NMCoordinatorBit 0;
BA_ "GenSigTimeoutTime_GNMM" SG_ 2654486529 CBV_bit3_NMCoordinatorBit 0;
BA_ "GenSigTimeoutTime_HCP" SG_ 2654486529 CBV_bit3_NMCoordinatorBit 0;
BA_ "GenSigTimeoutTime_IPC" SG_ 2654486529 CBV_bit3_NMCoordinatorBit 0;
BA_ "GenSigTimeoutTime_RFHM" SG_ 2654486529 CBV_bit3_NMCoordinatorBit 0;
BA_ "GenSigTimeoutTime_SGW" SG_ 2654486529 CBV_bit3_NMCoordinatorBit 0;
BA_ "GenSigTimeoutTime_TCM" SG_ 2654486529 CBV_bit3_NMCoordinatorBit 0;
BA_ "GenSigTimeoutTime_AGSM" SG_ 2654486529 CBV_bit4_ActiveWakeupBit 0;
BA_ "GenSigTimeoutTime_BCM" SG_ 2654486529 CBV_bit4_ActiveWakeupBit 0;
BA_ "GenSigTimeoutTime_BSM" SG_ 2654486529 CBV_bit4_ActiveWakeupBit 0;
BA_ "GenSigTimeoutTime_CADM" SG_ 2654486529 CBV_bit4_ActiveWakeupBit 0;
BA_ "GenSigTimeoutTime_DMSM" SG_ 2654486529 CBV_bit4_ActiveWakeupBit 0;
BA_ "GenSigTimeoutTime_DTCM" SG_ 2654486529 CBV_bit4_ActiveWakeupBit 0;
BA_ "GenSigTimeoutTime_ECM" SG_ 2654486529 CBV_bit4_ActiveWakeupBit 0;
BA_ "GenSigTimeoutTime_EVCU2" SG_ 2654486529 CBV_bit4_ActiveWakeupBit 0;
BA_ "GenSigTimeoutTime_GNMM" SG_ 2654486529 CBV_bit4_ActiveWakeupBit 0;
BA_ "GenSigTimeoutTime_HCP" SG_ 2654486529 CBV_bit4_ActiveWakeupBit 0;
BA_ "GenSigTimeoutTime_IPC" SG_ 2654486529 CBV_bit4_ActiveWakeupBit 0;
BA_ "GenSigTimeoutTime_RFHM" SG_ 2654486529 CBV_bit4_ActiveWakeupBit 0;
BA_ "GenSigTimeoutTime_SGW" SG_ 2654486529 CBV_bit4_ActiveWakeupBit 0;
BA_ "GenSigTimeoutTime_TCM" SG_ 2654486529 CBV_bit4_ActiveWakeupBit 0;
BA_ "GenSigTimeoutTime_AGSM" SG_ 2654486529 CBV_bit5 0;
BA_ "GenSigTimeoutTime_BCM" SG_ 2654486529 CBV_bit5 0;
BA_ "GenSigTimeoutTime_BSM" SG_ 2654486529 CBV_bit5 0;
BA_ "GenSigTimeoutTime_CADM" SG_ 2654486529 CBV_bit5 0;
BA_ "GenSigTimeoutTime_DMSM" SG_ 2654486529 CBV_bit5 0;
BA_ "GenSigTimeoutTime_DTCM" SG_ 2654486529 CBV_bit5 0;
BA_ "GenSigTimeoutTime_ECM" SG_ 2654486529 CBV_bit5 0;
BA_ "GenSigTimeoutTime_EVCU2" SG_ 2654486529 CBV_bit5 0;
BA_ "GenSigTimeoutTime_GNMM" SG_ 2654486529 CBV_bit5 0;
BA_ "GenSigTimeoutTime_HCP" SG_ 2654486529 CBV_bit5 0;
BA_ "GenSigTimeoutTime_IPC" SG_ 2654486529 CBV_bit5 0;
BA_ "GenSigTimeoutTime_RFHM" SG_ 2654486529 CBV_bit5 0;
BA_ "GenSigTimeoutTime_SGW" SG_ 2654486529 CBV_bit5 0;
BA_ "GenSigTimeoutTime_TCM" SG_ 2654486529 CBV_bit5 0;
BA_ "GenSigTimeoutTime_AGSM" SG_ 2654486529 CBV_bit6_PartialNtwInfBit 0;
BA_ "GenSigTimeoutTime_BCM" SG_ 2654486529 CBV_bit6_PartialNtwInfBit 0;
BA_ "GenSigTimeoutTime_BSM" SG_ 2654486529 CBV_bit6_PartialNtwInfBit 0;
BA_ "GenSigTimeoutTime_CADM" SG_ 2654486529 CBV_bit6_PartialNtwInfBit 0;
BA_ "GenSigTimeoutTime_DMSM" SG_ 2654486529 CBV_bit6_PartialNtwInfBit 0;
BA_ "GenSigTimeoutTime_DTCM" SG_ 2654486529 CBV_bit6_PartialNtwInfBit 0;
BA_ "GenSigTimeoutTime_ECM" SG_ 2654486529 CBV_bit6_PartialNtwInfBit 0;
BA_ "GenSigTimeoutTime_EVCU2" SG_ 2654486529 CBV_bit6_PartialNtwInfBit 0;
BA_ "GenSigTimeoutTime_GNMM" SG_ 2654486529 CBV_bit6_PartialNtwInfBit 0;
BA_ "GenSigTimeoutTime_HCP" SG_ 2654486529 CBV_bit6_PartialNtwInfBit 0;
BA_ "GenSigTimeoutTime_IPC" SG_ 2654486529 CBV_bit6_PartialNtwInfBit 0;
BA_ "GenSigTimeoutTime_RFHM" SG_ 2654486529 CBV_bit6_PartialNtwInfBit 0;
BA_ "GenSigTimeoutTime_SGW" SG_ 2654486529 CBV_bit6_PartialNtwInfBit 0;
BA_ "GenSigTimeoutTime_TCM" SG_ 2654486529 CBV_bit6_PartialNtwInfBit 0;
BA_ "GenSigTimeoutTime_AGSM" SG_ 2654486529 CBV_bit7 0;
BA_ "GenSigTimeoutTime_BCM" SG_ 2654486529 CBV_bit7 0;
BA_ "GenSigTimeoutTime_BSM" SG_ 2654486529 CBV_bit7 0;
BA_ "GenSigTimeoutTime_CADM" SG_ 2654486529 CBV_bit7 0;
BA_ "GenSigTimeoutTime_DMSM" SG_ 2654486529 CBV_bit7 0;
BA_ "GenSigTimeoutTime_DTCM" SG_ 2654486529 CBV_bit7 0;
BA_ "GenSigTimeoutTime_ECM" SG_ 2654486529 CBV_bit7 0;
BA_ "GenSigTimeoutTime_EVCU2" SG_ 2654486529 CBV_bit7 0;
BA_ "GenSigTimeoutTime_GNMM" SG_ 2654486529 CBV_bit7 0;
BA_ "GenSigTimeoutTime_HCP" SG_ 2654486529 CBV_bit7 0;
BA_ "GenSigTimeoutTime_IPC" SG_ 2654486529 CBV_bit7 0;
BA_ "GenSigTimeoutTime_RFHM" SG_ 2654486529 CBV_bit7 0;
BA_ "GenSigTimeoutTime_SGW" SG_ 2654486529 CBV_bit7 0;
BA_ "GenSigTimeoutTime_TCM" SG_ 2654486529 CBV_bit7 0;
BA_ "GenSigTimeoutTime_AGSM" SG_ 2654486529 SourceNodeIdentifier 0;
BA_ "GenSigTimeoutTime_BCM" SG_ 2654486529 SourceNodeIdentifier 0;
BA_ "GenSigTimeoutTime_BSM" SG_ 2654486529 SourceNodeIdentifier 0;
BA_ "GenSigTimeoutTime_CADM" SG_ 2654486529 SourceNodeIdentifier 0;
BA_ "GenSigTimeoutTime_DMSM" SG_ 2654486529 SourceNodeIdentifier 0;
BA_ "GenSigTimeoutTime_DTCM" SG_ 2654486529 SourceNodeIdentifier 0;
BA_ "GenSigTimeoutTime_ECM" SG_ 2654486529 SourceNodeIdentifier 0;
BA_ "GenSigTimeoutTime_EVCU2" SG_ 2654486529 SourceNodeIdentifier 0;
BA_ "GenSigTimeoutTime_GNMM" SG_ 2654486529 SourceNodeIdentifier 0;
BA_ "GenSigTimeoutTime_HCP" SG_ 2654486529 SourceNodeIdentifier 0;
BA_ "GenSigTimeoutTime_IPC" SG_ 2654486529 SourceNodeIdentifier 0;
BA_ "GenSigTimeoutTime_RFHM" SG_ 2654486529 SourceNodeIdentifier 0;
BA_ "GenSigTimeoutTime_SGW" SG_ 2654486529 SourceNodeIdentifier 0;
BA_ "GenSigTimeoutTime_TCM" SG_ 2654486529 SourceNodeIdentifier 0;
BA_ "GenSigTimeoutTime_AGSM" SG_ 2654486592 CBV_bit0_RepeatMessageRequestBit 0;
BA_ "GenSigTimeoutTime_BCM" SG_ 2654486592 CBV_bit0_RepeatMessageRequestBit 0;
BA_ "GenSigTimeoutTime_BSM" SG_ 2654486592 CBV_bit0_RepeatMessageRequestBit 0;
BA_ "GenSigTimeoutTime_CADM" SG_ 2654486592 CBV_bit0_RepeatMessageRequestBit 0;
BA_ "GenSigTimeoutTime_DMSM" SG_ 2654486592 CBV_bit0_RepeatMessageRequestBit 0;
BA_ "GenSigTimeoutTime_DTCM" SG_ 2654486592 CBV_bit0_RepeatMessageRequestBit 0;
BA_ "GenSigTimeoutTime_ECM" SG_ 2654486592 CBV_bit0_RepeatMessageRequestBit 0;
BA_ "GenSigTimeoutTime_EVCU2" SG_ 2654486592 CBV_bit0_RepeatMessageRequestBit 0;
BA_ "GenSigTimeoutTime_GNMM" SG_ 2654486592 CBV_bit0_RepeatMessageRequestBit 0;
BA_ "GenSigTimeoutTime_HCP" SG_ 2654486592 CBV_bit0_RepeatMessageRequestBit 0;
BA_ "GenSigTimeoutTime_IPC" SG_ 2654486592 CBV_bit0_RepeatMessageRequestBit 0;
BA_ "GenSigTimeoutTime_RFHM" SG_ 2654486592 CBV_bit0_RepeatMessageRequestBit 0;
BA_ "GenSigTimeoutTime_SGW" SG_ 2654486592 CBV_bit0_RepeatMessageRequestBit 0;
BA_ "GenSigTimeoutTime_TCM" SG_ 2654486592 CBV_bit0_RepeatMessageRequestBit 0;
BA_ "GenSigTimeoutTime_AGSM" SG_ 2654486592 CBV_bit1 0;
BA_ "GenSigTimeoutTime_BCM" SG_ 2654486592 CBV_bit1 0;
BA_ "GenSigTimeoutTime_BSM" SG_ 2654486592 CBV_bit1 0;
BA_ "GenSigTimeoutTime_CADM" SG_ 2654486592 CBV_bit1 0;
BA_ "GenSigTimeoutTime_DMSM" SG_ 2654486592 CBV_bit1 0;
BA_ "GenSigTimeoutTime_DTCM" SG_ 2654486592 CBV_bit1 0;
BA_ "GenSigTimeoutTime_ECM" SG_ 2654486592 CBV_bit1 0;
BA_ "GenSigTimeoutTime_EVCU2" SG_ 2654486592 CBV_bit1 0;
BA_ "GenSigTimeoutTime_GNMM" SG_ 2654486592 CBV_bit1 0;
BA_ "GenSigTimeoutTime_HCP" SG_ 2654486592 CBV_bit1 0;
BA_ "GenSigTimeoutTime_IPC" SG_ 2654486592 CBV_bit1 0;
BA_ "GenSigTimeoutTime_RFHM" SG_ 2654486592 CBV_bit1 0;
BA_ "GenSigTimeoutTime_SGW" SG_ 2654486592 CBV_bit1 0;
BA_ "GenSigTimeoutTime_TCM" SG_ 2654486592 CBV_bit1 0;
BA_ "GenSigTimeoutTime_AGSM" SG_ 2654486592 CBV_bit2 0;
BA_ "GenSigTimeoutTime_BCM" SG_ 2654486592 CBV_bit2 0;
BA_ "GenSigTimeoutTime_BSM" SG_ 2654486592 CBV_bit2 0;
BA_ "GenSigTimeoutTime_CADM" SG_ 2654486592 CBV_bit2 0;
BA_ "GenSigTimeoutTime_DMSM" SG_ 2654486592 CBV_bit2 0;
BA_ "GenSigTimeoutTime_DTCM" SG_ 2654486592 CBV_bit2 0;
BA_ "GenSigTimeoutTime_ECM" SG_ 2654486592 CBV_bit2 0;
BA_ "GenSigTimeoutTime_EVCU2" SG_ 2654486592 CBV_bit2 0;
BA_ "GenSigTimeoutTime_GNMM" SG_ 2654486592 CBV_bit2 0;
BA_ "GenSigTimeoutTime_HCP" SG_ 2654486592 CBV_bit2 0;
BA_ "GenSigTimeoutTime_IPC" SG_ 2654486592 CBV_bit2 0;
BA_ "GenSigTimeoutTime_RFHM" SG_ 2654486592 CBV_bit2 0;
BA_ "GenSigTimeoutTime_SGW" SG_ 2654486592 CBV_bit2 0;
BA_ "GenSigTimeoutTime_TCM" SG_ 2654486592 CBV_bit2 0;
BA_ "GenSigTimeoutTime_AGSM" SG_ 2654486592 CBV_bit3_NMCoordinatorBit 0;
BA_ "GenSigTimeoutTime_BCM" SG_ 2654486592 CBV_bit3_NMCoordinatorBit 0;
BA_ "GenSigTimeoutTime_BSM" SG_ 2654486592 CBV_bit3_NMCoordinatorBit 0;
BA_ "GenSigTimeoutTime_CADM" SG_ 2654486592 CBV_bit3_NMCoordinatorBit 0;
BA_ "GenSigTimeoutTime_DMSM" SG_ 2654486592 CBV_bit3_NMCoordinatorBit 0;
BA_ "GenSigTimeoutTime_DTCM" SG_ 2654486592 CBV_bit3_NMCoordinatorBit 0;
BA_ "GenSigTimeoutTime_ECM" SG_ 2654486592 CBV_bit3_NMCoordinatorBit 0;
BA_ "GenSigTimeoutTime_EVCU2" SG_ 2654486592 CBV_bit3_NMCoordinatorBit 0;
BA_ "GenSigTimeoutTime_GNMM" SG_ 2654486592 CBV_bit3_NMCoordinatorBit 0;
BA_ "GenSigTimeoutTime_HCP" SG_ 2654486592 CBV_bit3_NMCoordinatorBit 0;
BA_ "GenSigTimeoutTime_IPC" SG_ 2654486592 CBV_bit3_NMCoordinatorBit 0;
BA_ "GenSigTimeoutTime_RFHM" SG_ 2654486592 CBV_bit3_NMCoordinatorBit 0;
BA_ "GenSigTimeoutTime_SGW" SG_ 2654486592 CBV_bit3_NMCoordinatorBit 0;
BA_ "GenSigTimeoutTime_TCM" SG_ 2654486592 CBV_bit3_NMCoordinatorBit 0;
BA_ "GenSigTimeoutTime_AGSM" SG_ 2654486592 CBV_bit4_ActiveWakeupBit 0;
BA_ "GenSigTimeoutTime_BCM" SG_ 2654486592 CBV_bit4_ActiveWakeupBit 0;
BA_ "GenSigTimeoutTime_BSM" SG_ 2654486592 CBV_bit4_ActiveWakeupBit 0;
BA_ "GenSigTimeoutTime_CADM" SG_ 2654486592 CBV_bit4_ActiveWakeupBit 0;
BA_ "GenSigTimeoutTime_DMSM" SG_ 2654486592 CBV_bit4_ActiveWakeupBit 0;
BA_ "GenSigTimeoutTime_DTCM" SG_ 2654486592 CBV_bit4_ActiveWakeupBit 0;
BA_ "GenSigTimeoutTime_ECM" SG_ 2654486592 CBV_bit4_ActiveWakeupBit 0;
BA_ "GenSigTimeoutTime_EVCU2" SG_ 2654486592 CBV_bit4_ActiveWakeupBit 0;
BA_ "GenSigTimeoutTime_GNMM" SG_ 2654486592 CBV_bit4_ActiveWakeupBit 0;
BA_ "GenSigTimeoutTime_HCP" SG_ 2654486592 CBV_bit4_ActiveWakeupBit 0;
BA_ "GenSigTimeoutTime_IPC" SG_ 2654486592 CBV_bit4_ActiveWakeupBit 0;
BA_ "GenSigTimeoutTime_RFHM" SG_ 2654486592 CBV_bit4_ActiveWakeupBit 0;
BA_ "GenSigTimeoutTime_SGW" SG_ 2654486592 CBV_bit4_ActiveWakeupBit 0;
BA_ "GenSigTimeoutTime_TCM" SG_ 2654486592 CBV_bit4_ActiveWakeupBit 0;
BA_ "GenSigTimeoutTime_AGSM" SG_ 2654486592 CBV_bit5 0;
BA_ "GenSigTimeoutTime_BCM" SG_ 2654486592 CBV_bit5 0;
BA_ "GenSigTimeoutTime_BSM" SG_ 2654486592 CBV_bit5 0;
BA_ "GenSigTimeoutTime_CADM" SG_ 2654486592 CBV_bit5 0;
BA_ "GenSigTimeoutTime_DMSM" SG_ 2654486592 CBV_bit5 0;
BA_ "GenSigTimeoutTime_DTCM" SG_ 2654486592 CBV_bit5 0;
BA_ "GenSigTimeoutTime_ECM" SG_ 2654486592 CBV_bit5 0;
BA_ "GenSigTimeoutTime_EVCU2" SG_ 2654486592 CBV_bit5 0;
BA_ "GenSigTimeoutTime_GNMM" SG_ 2654486592 CBV_bit5 0;
BA_ "GenSigTimeoutTime_HCP" SG_ 2654486592 CBV_bit5 0;
BA_ "GenSigTimeoutTime_IPC" SG_ 2654486592 CBV_bit5 0;
BA_ "GenSigTimeoutTime_RFHM" SG_ 2654486592 CBV_bit5 0;
BA_ "GenSigTimeoutTime_SGW" SG_ 2654486592 CBV_bit5 0;
BA_ "GenSigTimeoutTime_TCM" SG_ 2654486592 CBV_bit5 0;
BA_ "GenSigTimeoutTime_AGSM" SG_ 2654486592 CBV_bit6_PartialNtwInfBit 0;
BA_ "GenSigTimeoutTime_BCM" SG_ 2654486592 CBV_bit6_PartialNtwInfBit 0;
BA_ "GenSigTimeoutTime_BSM" SG_ 2654486592 CBV_bit6_PartialNtwInfBit 0;
BA_ "GenSigTimeoutTime_CADM" SG_ 2654486592 CBV_bit6_PartialNtwInfBit 0;
BA_ "GenSigTimeoutTime_DMSM" SG_ 2654486592 CBV_bit6_PartialNtwInfBit 0;
BA_ "GenSigTimeoutTime_DTCM" SG_ 2654486592 CBV_bit6_PartialNtwInfBit 0;
BA_ "GenSigTimeoutTime_ECM" SG_ 2654486592 CBV_bit6_PartialNtwInfBit 0;
BA_ "GenSigTimeoutTime_EVCU2" SG_ 2654486592 CBV_bit6_PartialNtwInfBit 0;
BA_ "GenSigTimeoutTime_GNMM" SG_ 2654486592 CBV_bit6_PartialNtwInfBit 0;
BA_ "GenSigTimeoutTime_HCP" SG_ 2654486592 CBV_bit6_PartialNtwInfBit 0;
BA_ "GenSigTimeoutTime_IPC" SG_ 2654486592 CBV_bit6_PartialNtwInfBit 0;
BA_ "GenSigTimeoutTime_RFHM" SG_ 2654486592 CBV_bit6_PartialNtwInfBit 0;
BA_ "GenSigTimeoutTime_SGW" SG_ 2654486592 CBV_bit6_PartialNtwInfBit 0;
BA_ "GenSigTimeoutTime_TCM" SG_ 2654486592 CBV_bit6_PartialNtwInfBit 0;
BA_ "GenSigTimeoutTime_AGSM" SG_ 2654486592 CBV_bit7 0;
BA_ "GenSigTimeoutTime_BCM" SG_ 2654486592 CBV_bit7 0;
BA_ "GenSigTimeoutTime_BSM" SG_ 2654486592 CBV_bit7 0;
BA_ "GenSigTimeoutTime_CADM" SG_ 2654486592 CBV_bit7 0;
BA_ "GenSigTimeoutTime_DMSM" SG_ 2654486592 CBV_bit7 0;
BA_ "GenSigTimeoutTime_DTCM" SG_ 2654486592 CBV_bit7 0;
BA_ "GenSigTimeoutTime_ECM" SG_ 2654486592 CBV_bit7 0;
BA_ "GenSigTimeoutTime_EVCU2" SG_ 2654486592 CBV_bit7 0;
BA_ "GenSigTimeoutTime_GNMM" SG_ 2654486592 CBV_bit7 0;
BA_ "GenSigTimeoutTime_HCP" SG_ 2654486592 CBV_bit7 0;
BA_ "GenSigTimeoutTime_IPC" SG_ 2654486592 CBV_bit7 0;
BA_ "GenSigTimeoutTime_RFHM" SG_ 2654486592 CBV_bit7 0;
BA_ "GenSigTimeoutTime_SGW" SG_ 2654486592 CBV_bit7 0;
BA_ "GenSigTimeoutTime_TCM" SG_ 2654486592 CBV_bit7 0;
BA_ "GenSigTimeoutTime_AGSM" SG_ 2654486592 SourceNodeIdentifier 0;
BA_ "GenSigTimeoutTime_BCM" SG_ 2654486592 SourceNodeIdentifier 0;
BA_ "GenSigTimeoutTime_BSM" SG_ 2654486592 SourceNodeIdentifier 0;
BA_ "GenSigTimeoutTime_CADM" SG_ 2654486592 SourceNodeIdentifier 0;
BA_ "GenSigTimeoutTime_DMSM" SG_ 2654486592 SourceNodeIdentifier 0;
BA_ "GenSigTimeoutTime_DTCM" SG_ 2654486592 SourceNodeIdentifier 0;
BA_ "GenSigTimeoutTime_ECM" SG_ 2654486592 SourceNodeIdentifier 0;
BA_ "GenSigTimeoutTime_EVCU2" SG_ 2654486592 SourceNodeIdentifier 0;
BA_ "GenSigTimeoutTime_GNMM" SG_ 2654486592 SourceNodeIdentifier 0;
BA_ "GenSigTimeoutTime_HCP" SG_ 2654486592 SourceNodeIdentifier 0;
BA_ "GenSigTimeoutTime_IPC" SG_ 2654486592 SourceNodeIdentifier 0;
BA_ "GenSigTimeoutTime_RFHM" SG_ 2654486592 SourceNodeIdentifier 0;
BA_ "GenSigTimeoutTime_SGW" SG_ 2654486592 SourceNodeIdentifier 0;
BA_ "GenSigTimeoutTime_TCM" SG_ 2654486592 SourceNodeIdentifier 0;
BA_ "GenSigTimeoutTime_AGSM" SG_ 2654486672 CBV_bit0_RepeatMessageRequestBit 0;
BA_ "GenSigTimeoutTime_BCM" SG_ 2654486672 CBV_bit0_RepeatMessageRequestBit 0;
BA_ "GenSigTimeoutTime_BSM" SG_ 2654486672 CBV_bit0_RepeatMessageRequestBit 0;
BA_ "GenSigTimeoutTime_CADM" SG_ 2654486672 CBV_bit0_RepeatMessageRequestBit 0;
BA_ "GenSigTimeoutTime_DMSM" SG_ 2654486672 CBV_bit0_RepeatMessageRequestBit 0;
BA_ "GenSigTimeoutTime_DTCM" SG_ 2654486672 CBV_bit0_RepeatMessageRequestBit 0;
BA_ "GenSigTimeoutTime_ECM" SG_ 2654486672 CBV_bit0_RepeatMessageRequestBit 0;
BA_ "GenSigTimeoutTime_EVCU2" SG_ 2654486672 CBV_bit0_RepeatMessageRequestBit 0;
BA_ "GenSigTimeoutTime_GNMM" SG_ 2654486672 CBV_bit0_RepeatMessageRequestBit 0;
BA_ "GenSigTimeoutTime_HCP" SG_ 2654486672 CBV_bit0_RepeatMessageRequestBit 0;
BA_ "GenSigTimeoutTime_IPC" SG_ 2654486672 CBV_bit0_RepeatMessageRequestBit 0;
BA_ "GenSigTimeoutTime_RFHM" SG_ 2654486672 CBV_bit0_RepeatMessageRequestBit 0;
BA_ "GenSigTimeoutTime_SGW" SG_ 2654486672 CBV_bit0_RepeatMessageRequestBit 0;
BA_ "GenSigTimeoutTime_TCM" SG_ 2654486672 CBV_bit0_RepeatMessageRequestBit 0;
BA_ "GenSigTimeoutTime_AGSM" SG_ 2654486672 CBV_bit1 0;
BA_ "GenSigTimeoutTime_BCM" SG_ 2654486672 CBV_bit1 0;
BA_ "GenSigTimeoutTime_BSM" SG_ 2654486672 CBV_bit1 0;
BA_ "GenSigTimeoutTime_CADM" SG_ 2654486672 CBV_bit1 0;
BA_ "GenSigTimeoutTime_DMSM" SG_ 2654486672 CBV_bit1 0;
BA_ "GenSigTimeoutTime_DTCM" SG_ 2654486672 CBV_bit1 0;
BA_ "GenSigTimeoutTime_ECM" SG_ 2654486672 CBV_bit1 0;
BA_ "GenSigTimeoutTime_EVCU2" SG_ 2654486672 CBV_bit1 0;
BA_ "GenSigTimeoutTime_GNMM" SG_ 2654486672 CBV_bit1 0;
BA_ "GenSigTimeoutTime_HCP" SG_ 2654486672 CBV_bit1 0;
BA_ "GenSigTimeoutTime_IPC" SG_ 2654486672 CBV_bit1 0;
BA_ "GenSigTimeoutTime_RFHM" SG_ 2654486672 CBV_bit1 0;
BA_ "GenSigTimeoutTime_SGW" SG_ 2654486672 CBV_bit1 0;
BA_ "GenSigTimeoutTime_TCM" SG_ 2654486672 CBV_bit1 0;
BA_ "GenSigTimeoutTime_AGSM" SG_ 2654486672 CBV_bit2 0;
BA_ "GenSigTimeoutTime_BCM" SG_ 2654486672 CBV_bit2 0;
BA_ "GenSigTimeoutTime_BSM" SG_ 2654486672 CBV_bit2 0;
BA_ "GenSigTimeoutTime_CADM" SG_ 2654486672 CBV_bit2 0;
BA_ "GenSigTimeoutTime_DMSM" SG_ 2654486672 CBV_bit2 0;
BA_ "GenSigTimeoutTime_DTCM" SG_ 2654486672 CBV_bit2 0;
BA_ "GenSigTimeoutTime_ECM" SG_ 2654486672 CBV_bit2 0;
BA_ "GenSigTimeoutTime_EVCU2" SG_ 2654486672 CBV_bit2 0;
BA_ "GenSigTimeoutTime_GNMM" SG_ 2654486672 CBV_bit2 0;
BA_ "GenSigTimeoutTime_HCP" SG_ 2654486672 CBV_bit2 0;
BA_ "GenSigTimeoutTime_IPC" SG_ 2654486672 CBV_bit2 0;
BA_ "GenSigTimeoutTime_RFHM" SG_ 2654486672 CBV_bit2 0;
BA_ "GenSigTimeoutTime_SGW" SG_ 2654486672 CBV_bit2 0;
BA_ "GenSigTimeoutTime_TCM" SG_ 2654486672 CBV_bit2 0;
BA_ "GenSigTimeoutTime_AGSM" SG_ 2654486672 CBV_bit3_NMCoordinatorBit 0;
BA_ "GenSigTimeoutTime_BCM" SG_ 2654486672 CBV_bit3_NMCoordinatorBit 0;
BA_ "GenSigTimeoutTime_BSM" SG_ 2654486672 CBV_bit3_NMCoordinatorBit 0;
BA_ "GenSigTimeoutTime_CADM" SG_ 2654486672 CBV_bit3_NMCoordinatorBit 0;
BA_ "GenSigTimeoutTime_DMSM" SG_ 2654486672 CBV_bit3_NMCoordinatorBit 0;
BA_ "GenSigTimeoutTime_DTCM" SG_ 2654486672 CBV_bit3_NMCoordinatorBit 0;
BA_ "GenSigTimeoutTime_ECM" SG_ 2654486672 CBV_bit3_NMCoordinatorBit 0;
BA_ "GenSigTimeoutTime_EVCU2" SG_ 2654486672 CBV_bit3_NMCoordinatorBit 0;
BA_ "GenSigTimeoutTime_GNMM" SG_ 2654486672 CBV_bit3_NMCoordinatorBit 0;
BA_ "GenSigTimeoutTime_HCP" SG_ 2654486672 CBV_bit3_NMCoordinatorBit 0;
BA_ "GenSigTimeoutTime_IPC" SG_ 2654486672 CBV_bit3_NMCoordinatorBit 0;
BA_ "GenSigTimeoutTime_RFHM" SG_ 2654486672 CBV_bit3_NMCoordinatorBit 0;
BA_ "GenSigTimeoutTime_SGW" SG_ 2654486672 CBV_bit3_NMCoordinatorBit 0;
BA_ "GenSigTimeoutTime_TCM" SG_ 2654486672 CBV_bit3_NMCoordinatorBit 0;
BA_ "GenSigTimeoutTime_AGSM" SG_ 2654486672 CBV_bit4_ActiveWakeupBit 0;
BA_ "GenSigTimeoutTime_BCM" SG_ 2654486672 CBV_bit4_ActiveWakeupBit 0;
BA_ "GenSigTimeoutTime_BSM" SG_ 2654486672 CBV_bit4_ActiveWakeupBit 0;
BA_ "GenSigTimeoutTime_CADM" SG_ 2654486672 CBV_bit4_ActiveWakeupBit 0;
BA_ "GenSigTimeoutTime_DMSM" SG_ 2654486672 CBV_bit4_ActiveWakeupBit 0;
BA_ "GenSigTimeoutTime_DTCM" SG_ 2654486672 CBV_bit4_ActiveWakeupBit 0;
BA_ "GenSigTimeoutTime_ECM" SG_ 2654486672 CBV_bit4_ActiveWakeupBit 0;
BA_ "GenSigTimeoutTime_EVCU2" SG_ 2654486672 CBV_bit4_ActiveWakeupBit 0;
BA_ "GenSigTimeoutTime_GNMM" SG_ 2654486672 CBV_bit4_ActiveWakeupBit 0;
BA_ "GenSigTimeoutTime_HCP" SG_ 2654486672 CBV_bit4_ActiveWakeupBit 0;
BA_ "GenSigTimeoutTime_IPC" SG_ 2654486672 CBV_bit4_ActiveWakeupBit 0;
BA_ "GenSigTimeoutTime_RFHM" SG_ 2654486672 CBV_bit4_ActiveWakeupBit 0;
BA_ "GenSigTimeoutTime_SGW" SG_ 2654486672 CBV_bit4_ActiveWakeupBit 0;
BA_ "GenSigTimeoutTime_TCM" SG_ 2654486672 CBV_bit4_ActiveWakeupBit 0;
BA_ "GenSigTimeoutTime_AGSM" SG_ 2654486672 CBV_bit5 0;
BA_ "GenSigTimeoutTime_BCM" SG_ 2654486672 CBV_bit5 0;
BA_ "GenSigTimeoutTime_BSM" SG_ 2654486672 CBV_bit5 0;
BA_ "GenSigTimeoutTime_CADM" SG_ 2654486672 CBV_bit5 0;
BA_ "GenSigTimeoutTime_DMSM" SG_ 2654486672 CBV_bit5 0;
BA_ "GenSigTimeoutTime_DTCM" SG_ 2654486672 CBV_bit5 0;
BA_ "GenSigTimeoutTime_ECM" SG_ 2654486672 CBV_bit5 0;
BA_ "GenSigTimeoutTime_EVCU2" SG_ 2654486672 CBV_bit5 0;
BA_ "GenSigTimeoutTime_GNMM" SG_ 2654486672 CBV_bit5 0;
BA_ "GenSigTimeoutTime_HCP" SG_ 2654486672 CBV_bit5 0;
BA_ "GenSigTimeoutTime_IPC" SG_ 2654486672 CBV_bit5 0;
BA_ "GenSigTimeoutTime_RFHM" SG_ 2654486672 CBV_bit5 0;
BA_ "GenSigTimeoutTime_SGW" SG_ 2654486672 CBV_bit5 0;
BA_ "GenSigTimeoutTime_TCM" SG_ 2654486672 CBV_bit5 0;
BA_ "GenSigTimeoutTime_AGSM" SG_ 2654486672 CBV_bit6_PartialNtwInfBit 0;
BA_ "GenSigTimeoutTime_BCM" SG_ 2654486672 CBV_bit6_PartialNtwInfBit 0;
BA_ "GenSigTimeoutTime_BSM" SG_ 2654486672 CBV_bit6_PartialNtwInfBit 0;
BA_ "GenSigTimeoutTime_CADM" SG_ 2654486672 CBV_bit6_PartialNtwInfBit 0;
BA_ "GenSigTimeoutTime_DMSM" SG_ 2654486672 CBV_bit6_PartialNtwInfBit 0;
BA_ "GenSigTimeoutTime_DTCM" SG_ 2654486672 CBV_bit6_PartialNtwInfBit 0;
BA_ "GenSigTimeoutTime_ECM" SG_ 2654486672 CBV_bit6_PartialNtwInfBit 0;
BA_ "GenSigTimeoutTime_EVCU2" SG_ 2654486672 CBV_bit6_PartialNtwInfBit 0;
BA_ "GenSigTimeoutTime_GNMM" SG_ 2654486672 CBV_bit6_PartialNtwInfBit 0;
BA_ "GenSigTimeoutTime_HCP" SG_ 2654486672 CBV_bit6_PartialNtwInfBit 0;
BA_ "GenSigTimeoutTime_IPC" SG_ 2654486672 CBV_bit6_PartialNtwInfBit 0;
BA_ "GenSigTimeoutTime_RFHM" SG_ 2654486672 CBV_bit6_PartialNtwInfBit 0;
BA_ "GenSigTimeoutTime_SGW" SG_ 2654486672 CBV_bit6_PartialNtwInfBit 0;
BA_ "GenSigTimeoutTime_TCM" SG_ 2654486672 CBV_bit6_PartialNtwInfBit 0;
BA_ "GenSigTimeoutTime_AGSM" SG_ 2654486672 CBV_bit7 0;
BA_ "GenSigTimeoutTime_BCM" SG_ 2654486672 CBV_bit7 0;
BA_ "GenSigTimeoutTime_BSM" SG_ 2654486672 CBV_bit7 0;
BA_ "GenSigTimeoutTime_CADM" SG_ 2654486672 CBV_bit7 0;
BA_ "GenSigTimeoutTime_DMSM" SG_ 2654486672 CBV_bit7 0;
BA_ "GenSigTimeoutTime_DTCM" SG_ 2654486672 CBV_bit7 0;
BA_ "GenSigTimeoutTime_ECM" SG_ 2654486672 CBV_bit7 0;
BA_ "GenSigTimeoutTime_EVCU2" SG_ 2654486672 CBV_bit7 0;
BA_ "GenSigTimeoutTime_GNMM" SG_ 2654486672 CBV_bit7 0;
BA_ "GenSigTimeoutTime_HCP" SG_ 2654486672 CBV_bit7 0;
BA_ "GenSigTimeoutTime_IPC" SG_ 2654486672 CBV_bit7 0;
BA_ "GenSigTimeoutTime_RFHM" SG_ 2654486672 CBV_bit7 0;
BA_ "GenSigTimeoutTime_SGW" SG_ 2654486672 CBV_bit7 0;
BA_ "GenSigTimeoutTime_TCM" SG_ 2654486672 CBV_bit7 0;
BA_ "GenSigTimeoutTime_AGSM" SG_ 2654486672 SourceNodeIdentifier 0;
BA_ "GenSigTimeoutTime_BCM" SG_ 2654486672 SourceNodeIdentifier 0;
BA_ "GenSigTimeoutTime_BSM" SG_ 2654486672 SourceNodeIdentifier 0;
BA_ "GenSigTimeoutTime_CADM" SG_ 2654486672 SourceNodeIdentifier 0;
BA_ "GenSigTimeoutTime_DMSM" SG_ 2654486672 SourceNodeIdentifier 0;
BA_ "GenSigTimeoutTime_DTCM" SG_ 2654486672 SourceNodeIdentifier 0;
BA_ "GenSigTimeoutTime_ECM" SG_ 2654486672 SourceNodeIdentifier 0;
BA_ "GenSigTimeoutTime_EVCU2" SG_ 2654486672 SourceNodeIdentifier 0;
BA_ "GenSigTimeoutTime_GNMM" SG_ 2654486672 SourceNodeIdentifier 0;
BA_ "GenSigTimeoutTime_HCP" SG_ 2654486672 SourceNodeIdentifier 0;
BA_ "GenSigTimeoutTime_IPC" SG_ 2654486672 SourceNodeIdentifier 0;
BA_ "GenSigTimeoutTime_RFHM" SG_ 2654486672 SourceNodeIdentifier 0;
BA_ "GenSigTimeoutTime_SGW" SG_ 2654486672 SourceNodeIdentifier 0;
BA_ "GenSigTimeoutTime_TCM" SG_ 2654486672 SourceNodeIdentifier 0;
BA_ "GenSigTimeoutTime_AGSM" SG_ 2654486626 CBV_bit0_RepeatMessageRequestBit 0;
BA_ "GenSigTimeoutTime_BCM" SG_ 2654486626 CBV_bit0_RepeatMessageRequestBit 0;
BA_ "GenSigTimeoutTime_BSM" SG_ 2654486626 CBV_bit0_RepeatMessageRequestBit 0;
BA_ "GenSigTimeoutTime_CADM" SG_ 2654486626 CBV_bit0_RepeatMessageRequestBit 0;
BA_ "GenSigTimeoutTime_DMSM" SG_ 2654486626 CBV_bit0_RepeatMessageRequestBit 0;
BA_ "GenSigTimeoutTime_DTCM" SG_ 2654486626 CBV_bit0_RepeatMessageRequestBit 0;
BA_ "GenSigTimeoutTime_ECM" SG_ 2654486626 CBV_bit0_RepeatMessageRequestBit 0;
BA_ "GenSigTimeoutTime_EVCU2" SG_ 2654486626 CBV_bit0_RepeatMessageRequestBit 0;
BA_ "GenSigTimeoutTime_GNMM" SG_ 2654486626 CBV_bit0_RepeatMessageRequestBit 0;
BA_ "GenSigTimeoutTime_HCP" SG_ 2654486626 CBV_bit0_RepeatMessageRequestBit 0;
BA_ "GenSigTimeoutTime_IPC" SG_ 2654486626 CBV_bit0_RepeatMessageRequestBit 0;
BA_ "GenSigTimeoutTime_RFHM" SG_ 2654486626 CBV_bit0_RepeatMessageRequestBit 0;
BA_ "GenSigTimeoutTime_SGW" SG_ 2654486626 CBV_bit0_RepeatMessageRequestBit 0;
BA_ "GenSigTimeoutTime_TCM" SG_ 2654486626 CBV_bit0_RepeatMessageRequestBit 0;
BA_ "GenSigTimeoutTime_AGSM" SG_ 2654486626 CBV_bit1 0;
BA_ "GenSigTimeoutTime_BCM" SG_ 2654486626 CBV_bit1 0;
BA_ "GenSigTimeoutTime_BSM" SG_ 2654486626 CBV_bit1 0;
BA_ "GenSigTimeoutTime_CADM" SG_ 2654486626 CBV_bit1 0;
BA_ "GenSigTimeoutTime_DMSM" SG_ 2654486626 CBV_bit1 0;
BA_ "GenSigTimeoutTime_DTCM" SG_ 2654486626 CBV_bit1 0;
BA_ "GenSigTimeoutTime_ECM" SG_ 2654486626 CBV_bit1 0;
BA_ "GenSigTimeoutTime_EVCU2" SG_ 2654486626 CBV_bit1 0;
BA_ "GenSigTimeoutTime_GNMM" SG_ 2654486626 CBV_bit1 0;
BA_ "GenSigTimeoutTime_HCP" SG_ 2654486626 CBV_bit1 0;
BA_ "GenSigTimeoutTime_IPC" SG_ 2654486626 CBV_bit1 0;
BA_ "GenSigTimeoutTime_RFHM" SG_ 2654486626 CBV_bit1 0;
BA_ "GenSigTimeoutTime_SGW" SG_ 2654486626 CBV_bit1 0;
BA_ "GenSigTimeoutTime_TCM" SG_ 2654486626 CBV_bit1 0;
BA_ "GenSigTimeoutTime_AGSM" SG_ 2654486626 CBV_bit2 0;
BA_ "GenSigTimeoutTime_BCM" SG_ 2654486626 CBV_bit2 0;
BA_ "GenSigTimeoutTime_BSM" SG_ 2654486626 CBV_bit2 0;
BA_ "GenSigTimeoutTime_CADM" SG_ 2654486626 CBV_bit2 0;
BA_ "GenSigTimeoutTime_DMSM" SG_ 2654486626 CBV_bit2 0;
BA_ "GenSigTimeoutTime_DTCM" SG_ 2654486626 CBV_bit2 0;
BA_ "GenSigTimeoutTime_ECM" SG_ 2654486626 CBV_bit2 0;
BA_ "GenSigTimeoutTime_EVCU2" SG_ 2654486626 CBV_bit2 0;
BA_ "GenSigTimeoutTime_GNMM" SG_ 2654486626 CBV_bit2 0;
BA_ "GenSigTimeoutTime_HCP" SG_ 2654486626 CBV_bit2 0;
BA_ "GenSigTimeoutTime_IPC" SG_ 2654486626 CBV_bit2 0;
BA_ "GenSigTimeoutTime_RFHM" SG_ 2654486626 CBV_bit2 0;
BA_ "GenSigTimeoutTime_SGW" SG_ 2654486626 CBV_bit2 0;
BA_ "GenSigTimeoutTime_TCM" SG_ 2654486626 CBV_bit2 0;
BA_ "GenSigTimeoutTime_AGSM" SG_ 2654486626 CBV_bit3_NMCoordinatorBit 0;
BA_ "GenSigTimeoutTime_BCM" SG_ 2654486626 CBV_bit3_NMCoordinatorBit 0;
BA_ "GenSigTimeoutTime_BSM" SG_ 2654486626 CBV_bit3_NMCoordinatorBit 0;
BA_ "GenSigTimeoutTime_CADM" SG_ 2654486626 CBV_bit3_NMCoordinatorBit 0;
BA_ "GenSigTimeoutTime_DMSM" SG_ 2654486626 CBV_bit3_NMCoordinatorBit 0;
BA_ "GenSigTimeoutTime_DTCM" SG_ 2654486626 CBV_bit3_NMCoordinatorBit 0;
BA_ "GenSigTimeoutTime_ECM" SG_ 2654486626 CBV_bit3_NMCoordinatorBit 0;
BA_ "GenSigTimeoutTime_EVCU2" SG_ 2654486626 CBV_bit3_NMCoordinatorBit 0;
BA_ "GenSigTimeoutTime_GNMM" SG_ 2654486626 CBV_bit3_NMCoordinatorBit 0;
BA_ "GenSigTimeoutTime_HCP" SG_ 2654486626 CBV_bit3_NMCoordinatorBit 0;
BA_ "GenSigTimeoutTime_IPC" SG_ 2654486626 CBV_bit3_NMCoordinatorBit 0;
BA_ "GenSigTimeoutTime_RFHM" SG_ 2654486626 CBV_bit3_NMCoordinatorBit 0;
BA_ "GenSigTimeoutTime_SGW" SG_ 2654486626 CBV_bit3_NMCoordinatorBit 0;
BA_ "GenSigTimeoutTime_TCM" SG_ 2654486626 CBV_bit3_NMCoordinatorBit 0;
BA_ "GenSigTimeoutTime_AGSM" SG_ 2654486626 CBV_bit4_ActiveWakeupBit 0;
BA_ "GenSigTimeoutTime_BCM" SG_ 2654486626 CBV_bit4_ActiveWakeupBit 0;
BA_ "GenSigTimeoutTime_BSM" SG_ 2654486626 CBV_bit4_ActiveWakeupBit 0;
BA_ "GenSigTimeoutTime_CADM" SG_ 2654486626 CBV_bit4_ActiveWakeupBit 0;
BA_ "GenSigTimeoutTime_DMSM" SG_ 2654486626 CBV_bit4_ActiveWakeupBit 0;
BA_ "GenSigTimeoutTime_DTCM" SG_ 2654486626 CBV_bit4_ActiveWakeupBit 0;
BA_ "GenSigTimeoutTime_ECM" SG_ 2654486626 CBV_bit4_ActiveWakeupBit 0;
BA_ "GenSigTimeoutTime_EVCU2" SG_ 2654486626 CBV_bit4_ActiveWakeupBit 0;
BA_ "GenSigTimeoutTime_GNMM" SG_ 2654486626 CBV_bit4_ActiveWakeupBit 0;
BA_ "GenSigTimeoutTime_HCP" SG_ 2654486626 CBV_bit4_ActiveWakeupBit 0;
BA_ "GenSigTimeoutTime_IPC" SG_ 2654486626 CBV_bit4_ActiveWakeupBit 0;
BA_ "GenSigTimeoutTime_RFHM" SG_ 2654486626 CBV_bit4_ActiveWakeupBit 0;
BA_ "GenSigTimeoutTime_SGW" SG_ 2654486626 CBV_bit4_ActiveWakeupBit 0;
BA_ "GenSigTimeoutTime_TCM" SG_ 2654486626 CBV_bit4_ActiveWakeupBit 0;
BA_ "GenSigTimeoutTime_AGSM" SG_ 2654486626 CBV_bit5 0;
BA_ "GenSigTimeoutTime_BCM" SG_ 2654486626 CBV_bit5 0;
BA_ "GenSigTimeoutTime_BSM" SG_ 2654486626 CBV_bit5 0;
BA_ "GenSigTimeoutTime_CADM" SG_ 2654486626 CBV_bit5 0;
BA_ "GenSigTimeoutTime_DMSM" SG_ 2654486626 CBV_bit5 0;
BA_ "GenSigTimeoutTime_DTCM" SG_ 2654486626 CBV_bit5 0;
BA_ "GenSigTimeoutTime_ECM" SG_ 2654486626 CBV_bit5 0;
BA_ "GenSigTimeoutTime_EVCU2" SG_ 2654486626 CBV_bit5 0;
BA_ "GenSigTimeoutTime_GNMM" SG_ 2654486626 CBV_bit5 0;
BA_ "GenSigTimeoutTime_HCP" SG_ 2654486626 CBV_bit5 0;
BA_ "GenSigTimeoutTime_IPC" SG_ 2654486626 CBV_bit5 0;
BA_ "GenSigTimeoutTime_RFHM" SG_ 2654486626 CBV_bit5 0;
BA_ "GenSigTimeoutTime_SGW" SG_ 2654486626 CBV_bit5 0;
BA_ "GenSigTimeoutTime_TCM" SG_ 2654486626 CBV_bit5 0;
BA_ "GenSigTimeoutTime_AGSM" SG_ 2654486626 CBV_bit6_PartialNtwInfBit 0;
BA_ "GenSigTimeoutTime_BCM" SG_ 2654486626 CBV_bit6_PartialNtwInfBit 0;
BA_ "GenSigTimeoutTime_BSM" SG_ 2654486626 CBV_bit6_PartialNtwInfBit 0;
BA_ "GenSigTimeoutTime_CADM" SG_ 2654486626 CBV_bit6_PartialNtwInfBit 0;
BA_ "GenSigTimeoutTime_DMSM" SG_ 2654486626 CBV_bit6_PartialNtwInfBit 0;
BA_ "GenSigTimeoutTime_DTCM" SG_ 2654486626 CBV_bit6_PartialNtwInfBit 0;
BA_ "GenSigTimeoutTime_ECM" SG_ 2654486626 CBV_bit6_PartialNtwInfBit 0;
BA_ "GenSigTimeoutTime_EVCU2" SG_ 2654486626 CBV_bit6_PartialNtwInfBit 0;
BA_ "GenSigTimeoutTime_GNMM" SG_ 2654486626 CBV_bit6_PartialNtwInfBit 0;
BA_ "GenSigTimeoutTime_HCP" SG_ 2654486626 CBV_bit6_PartialNtwInfBit 0;
BA_ "GenSigTimeoutTime_IPC" SG_ 2654486626 CBV_bit6_PartialNtwInfBit 0;
BA_ "GenSigTimeoutTime_RFHM" SG_ 2654486626 CBV_bit6_PartialNtwInfBit 0;
BA_ "GenSigTimeoutTime_SGW" SG_ 2654486626 CBV_bit6_PartialNtwInfBit 0;
BA_ "GenSigTimeoutTime_TCM" SG_ 2654486626 CBV_bit6_PartialNtwInfBit 0;
BA_ "GenSigTimeoutTime_AGSM" SG_ 2654486626 CBV_bit7 0;
BA_ "GenSigTimeoutTime_BCM" SG_ 2654486626 CBV_bit7 0;
BA_ "GenSigTimeoutTime_BSM" SG_ 2654486626 CBV_bit7 0;
BA_ "GenSigTimeoutTime_CADM" SG_ 2654486626 CBV_bit7 0;
BA_ "GenSigTimeoutTime_DMSM" SG_ 2654486626 CBV_bit7 0;
BA_ "GenSigTimeoutTime_DTCM" SG_ 2654486626 CBV_bit7 0;
BA_ "GenSigTimeoutTime_ECM" SG_ 2654486626 CBV_bit7 0;
BA_ "GenSigTimeoutTime_EVCU2" SG_ 2654486626 CBV_bit7 0;
BA_ "GenSigTimeoutTime_GNMM" SG_ 2654486626 CBV_bit7 0;
BA_ "GenSigTimeoutTime_HCP" SG_ 2654486626 CBV_bit7 0;
BA_ "GenSigTimeoutTime_IPC" SG_ 2654486626 CBV_bit7 0;
BA_ "GenSigTimeoutTime_RFHM" SG_ 2654486626 CBV_bit7 0;
BA_ "GenSigTimeoutTime_SGW" SG_ 2654486626 CBV_bit7 0;
BA_ "GenSigTimeoutTime_TCM" SG_ 2654486626 CBV_bit7 0;
BA_ "GenSigTimeoutTime_AGSM" SG_ 2654486626 SourceNodeIdentifier 0;
BA_ "GenSigTimeoutTime_BCM" SG_ 2654486626 SourceNodeIdentifier 0;
BA_ "GenSigTimeoutTime_BSM" SG_ 2654486626 SourceNodeIdentifier 0;
BA_ "GenSigTimeoutTime_CADM" SG_ 2654486626 SourceNodeIdentifier 0;
BA_ "GenSigTimeoutTime_DMSM" SG_ 2654486626 SourceNodeIdentifier 0;
BA_ "GenSigTimeoutTime_DTCM" SG_ 2654486626 SourceNodeIdentifier 0;
BA_ "GenSigTimeoutTime_ECM" SG_ 2654486626 SourceNodeIdentifier 0;
BA_ "GenSigTimeoutTime_EVCU2" SG_ 2654486626 SourceNodeIdentifier 0;
BA_ "GenSigTimeoutTime_GNMM" SG_ 2654486626 SourceNodeIdentifier 0;
BA_ "GenSigTimeoutTime_HCP" SG_ 2654486626 SourceNodeIdentifier 0;
BA_ "GenSigTimeoutTime_IPC" SG_ 2654486626 SourceNodeIdentifier 0;
BA_ "GenSigTimeoutTime_RFHM" SG_ 2654486626 SourceNodeIdentifier 0;
BA_ "GenSigTimeoutTime_SGW" SG_ 2654486626 SourceNodeIdentifier 0;
BA_ "GenSigTimeoutTime_TCM" SG_ 2654486626 SourceNodeIdentifier 0;
BA_ "GenSigTimeoutTime_AGSM" SG_ 2654486531 CBV_bit0_RepeatMessageRequestBit 0;
BA_ "GenSigTimeoutTime_BCM" SG_ 2654486531 CBV_bit0_RepeatMessageRequestBit 0;
BA_ "GenSigTimeoutTime_BSM" SG_ 2654486531 CBV_bit0_RepeatMessageRequestBit 0;
BA_ "GenSigTimeoutTime_CADM" SG_ 2654486531 CBV_bit0_RepeatMessageRequestBit 0;
BA_ "GenSigTimeoutTime_DMSM" SG_ 2654486531 CBV_bit0_RepeatMessageRequestBit 0;
BA_ "GenSigTimeoutTime_DTCM" SG_ 2654486531 CBV_bit0_RepeatMessageRequestBit 0;
BA_ "GenSigTimeoutTime_ECM" SG_ 2654486531 CBV_bit0_RepeatMessageRequestBit 0;
BA_ "GenSigTimeoutTime_EVCU2" SG_ 2654486531 CBV_bit0_RepeatMessageRequestBit 0;
BA_ "GenSigTimeoutTime_GNMM" SG_ 2654486531 CBV_bit0_RepeatMessageRequestBit 0;
BA_ "GenSigTimeoutTime_HCP" SG_ 2654486531 CBV_bit0_RepeatMessageRequestBit 0;
BA_ "GenSigTimeoutTime_IPC" SG_ 2654486531 CBV_bit0_RepeatMessageRequestBit 0;
BA_ "GenSigTimeoutTime_RFHM" SG_ 2654486531 CBV_bit0_RepeatMessageRequestBit 0;
BA_ "GenSigTimeoutTime_SGW" SG_ 2654486531 CBV_bit0_RepeatMessageRequestBit 0;
BA_ "GenSigTimeoutTime_TCM" SG_ 2654486531 CBV_bit0_RepeatMessageRequestBit 0;
BA_ "GenSigTimeoutTime_AGSM" SG_ 2654486531 CBV_bit1 0;
BA_ "GenSigTimeoutTime_BCM" SG_ 2654486531 CBV_bit1 0;
BA_ "GenSigTimeoutTime_BSM" SG_ 2654486531 CBV_bit1 0;
BA_ "GenSigTimeoutTime_CADM" SG_ 2654486531 CBV_bit1 0;
BA_ "GenSigTimeoutTime_DMSM" SG_ 2654486531 CBV_bit1 0;
BA_ "GenSigTimeoutTime_DTCM" SG_ 2654486531 CBV_bit1 0;
BA_ "GenSigTimeoutTime_ECM" SG_ 2654486531 CBV_bit1 0;
BA_ "GenSigTimeoutTime_EVCU2" SG_ 2654486531 CBV_bit1 0;
BA_ "GenSigTimeoutTime_GNMM" SG_ 2654486531 CBV_bit1 0;
BA_ "GenSigTimeoutTime_HCP" SG_ 2654486531 CBV_bit1 0;
BA_ "GenSigTimeoutTime_IPC" SG_ 2654486531 CBV_bit1 0;
BA_ "GenSigTimeoutTime_RFHM" SG_ 2654486531 CBV_bit1 0;
BA_ "GenSigTimeoutTime_SGW" SG_ 2654486531 CBV_bit1 0;
BA_ "GenSigTimeoutTime_TCM" SG_ 2654486531 CBV_bit1 0;
BA_ "GenSigTimeoutTime_AGSM" SG_ 2654486531 CBV_bit2 0;
BA_ "GenSigTimeoutTime_BCM" SG_ 2654486531 CBV_bit2 0;
BA_ "GenSigTimeoutTime_BSM" SG_ 2654486531 CBV_bit2 0;
BA_ "GenSigTimeoutTime_CADM" SG_ 2654486531 CBV_bit2 0;
BA_ "GenSigTimeoutTime_DMSM" SG_ 2654486531 CBV_bit2 0;
BA_ "GenSigTimeoutTime_DTCM" SG_ 2654486531 CBV_bit2 0;
BA_ "GenSigTimeoutTime_ECM" SG_ 2654486531 CBV_bit2 0;
BA_ "GenSigTimeoutTime_EVCU2" SG_ 2654486531 CBV_bit2 0;
BA_ "GenSigTimeoutTime_GNMM" SG_ 2654486531 CBV_bit2 0;
BA_ "GenSigTimeoutTime_HCP" SG_ 2654486531 CBV_bit2 0;
BA_ "GenSigTimeoutTime_IPC" SG_ 2654486531 CBV_bit2 0;
BA_ "GenSigTimeoutTime_RFHM" SG_ 2654486531 CBV_bit2 0;
BA_ "GenSigTimeoutTime_SGW" SG_ 2654486531 CBV_bit2 0;
BA_ "GenSigTimeoutTime_TCM" SG_ 2654486531 CBV_bit2 0;
BA_ "GenSigTimeoutTime_AGSM" SG_ 2654486531 CBV_bit3_NMCoordinatorBit 0;
BA_ "GenSigTimeoutTime_BCM" SG_ 2654486531 CBV_bit3_NMCoordinatorBit 0;
BA_ "GenSigTimeoutTime_BSM" SG_ 2654486531 CBV_bit3_NMCoordinatorBit 0;
BA_ "GenSigTimeoutTime_CADM" SG_ 2654486531 CBV_bit3_NMCoordinatorBit 0;
BA_ "GenSigTimeoutTime_DMSM" SG_ 2654486531 CBV_bit3_NMCoordinatorBit 0;
BA_ "GenSigTimeoutTime_DTCM" SG_ 2654486531 CBV_bit3_NMCoordinatorBit 0;
BA_ "GenSigTimeoutTime_ECM" SG_ 2654486531 CBV_bit3_NMCoordinatorBit 0;
BA_ "GenSigTimeoutTime_EVCU2" SG_ 2654486531 CBV_bit3_NMCoordinatorBit 0;
BA_ "GenSigTimeoutTime_GNMM" SG_ 2654486531 CBV_bit3_NMCoordinatorBit 0;
BA_ "GenSigTimeoutTime_HCP" SG_ 2654486531 CBV_bit3_NMCoordinatorBit 0;
BA_ "GenSigTimeoutTime_IPC" SG_ 2654486531 CBV_bit3_NMCoordinatorBit 0;
BA_ "GenSigTimeoutTime_RFHM" SG_ 2654486531 CBV_bit3_NMCoordinatorBit 0;
BA_ "GenSigTimeoutTime_SGW" SG_ 2654486531 CBV_bit3_NMCoordinatorBit 0;
BA_ "GenSigTimeoutTime_TCM" SG_ 2654486531 CBV_bit3_NMCoordinatorBit 0;
BA_ "GenSigTimeoutTime_AGSM" SG_ 2654486531 CBV_bit4_ActiveWakeupBit 0;
BA_ "GenSigTimeoutTime_BCM" SG_ 2654486531 CBV_bit4_ActiveWakeupBit 0;
BA_ "GenSigTimeoutTime_BSM" SG_ 2654486531 CBV_bit4_ActiveWakeupBit 0;
BA_ "GenSigTimeoutTime_CADM" SG_ 2654486531 CBV_bit4_ActiveWakeupBit 0;
BA_ "GenSigTimeoutTime_DMSM" SG_ 2654486531 CBV_bit4_ActiveWakeupBit 0;
BA_ "GenSigTimeoutTime_DTCM" SG_ 2654486531 CBV_bit4_ActiveWakeupBit 0;
BA_ "GenSigTimeoutTime_ECM" SG_ 2654486531 CBV_bit4_ActiveWakeupBit 0;
BA_ "GenSigTimeoutTime_EVCU2" SG_ 2654486531 CBV_bit4_ActiveWakeupBit 0;
BA_ "GenSigTimeoutTime_GNMM" SG_ 2654486531 CBV_bit4_ActiveWakeupBit 0;
BA_ "GenSigTimeoutTime_HCP" SG_ 2654486531 CBV_bit4_ActiveWakeupBit 0;
BA_ "GenSigTimeoutTime_IPC" SG_ 2654486531 CBV_bit4_ActiveWakeupBit 0;
BA_ "GenSigTimeoutTime_RFHM" SG_ 2654486531 CBV_bit4_ActiveWakeupBit 0;
BA_ "GenSigTimeoutTime_SGW" SG_ 2654486531 CBV_bit4_ActiveWakeupBit 0;
BA_ "GenSigTimeoutTime_TCM" SG_ 2654486531 CBV_bit4_ActiveWakeupBit 0;
BA_ "GenSigTimeoutTime_AGSM" SG_ 2654486531 CBV_bit5 0;
BA_ "GenSigTimeoutTime_BCM" SG_ 2654486531 CBV_bit5 0;
BA_ "GenSigTimeoutTime_BSM" SG_ 2654486531 CBV_bit5 0;
BA_ "GenSigTimeoutTime_CADM" SG_ 2654486531 CBV_bit5 0;
BA_ "GenSigTimeoutTime_DMSM" SG_ 2654486531 CBV_bit5 0;
BA_ "GenSigTimeoutTime_DTCM" SG_ 2654486531 CBV_bit5 0;
BA_ "GenSigTimeoutTime_ECM" SG_ 2654486531 CBV_bit5 0;
BA_ "GenSigTimeoutTime_EVCU2" SG_ 2654486531 CBV_bit5 0;
BA_ "GenSigTimeoutTime_GNMM" SG_ 2654486531 CBV_bit5 0;
BA_ "GenSigTimeoutTime_HCP" SG_ 2654486531 CBV_bit5 0;
BA_ "GenSigTimeoutTime_IPC" SG_ 2654486531 CBV_bit5 0;
BA_ "GenSigTimeoutTime_RFHM" SG_ 2654486531 CBV_bit5 0;
BA_ "GenSigTimeoutTime_SGW" SG_ 2654486531 CBV_bit5 0;
BA_ "GenSigTimeoutTime_TCM" SG_ 2654486531 CBV_bit5 0;
BA_ "GenSigTimeoutTime_AGSM" SG_ 2654486531 CBV_bit6_PartialNtwInfBit 0;
BA_ "GenSigTimeoutTime_BCM" SG_ 2654486531 CBV_bit6_PartialNtwInfBit 0;
BA_ "GenSigTimeoutTime_BSM" SG_ 2654486531 CBV_bit6_PartialNtwInfBit 0;
BA_ "GenSigTimeoutTime_CADM" SG_ 2654486531 CBV_bit6_PartialNtwInfBit 0;
BA_ "GenSigTimeoutTime_DMSM" SG_ 2654486531 CBV_bit6_PartialNtwInfBit 0;
BA_ "GenSigTimeoutTime_DTCM" SG_ 2654486531 CBV_bit6_PartialNtwInfBit 0;
BA_ "GenSigTimeoutTime_ECM" SG_ 2654486531 CBV_bit6_PartialNtwInfBit 0;
BA_ "GenSigTimeoutTime_EVCU2" SG_ 2654486531 CBV_bit6_PartialNtwInfBit 0;
BA_ "GenSigTimeoutTime_GNMM" SG_ 2654486531 CBV_bit6_PartialNtwInfBit 0;
BA_ "GenSigTimeoutTime_HCP" SG_ 2654486531 CBV_bit6_PartialNtwInfBit 0;
BA_ "GenSigTimeoutTime_IPC" SG_ 2654486531 CBV_bit6_PartialNtwInfBit 0;
BA_ "GenSigTimeoutTime_RFHM" SG_ 2654486531 CBV_bit6_PartialNtwInfBit 0;
BA_ "GenSigTimeoutTime_SGW" SG_ 2654486531 CBV_bit6_PartialNtwInfBit 0;
BA_ "GenSigTimeoutTime_TCM" SG_ 2654486531 CBV_bit6_PartialNtwInfBit 0;
BA_ "GenSigTimeoutTime_AGSM" SG_ 2654486531 CBV_bit7 0;
BA_ "GenSigTimeoutTime_BCM" SG_ 2654486531 CBV_bit7 0;
BA_ "GenSigTimeoutTime_BSM" SG_ 2654486531 CBV_bit7 0;
BA_ "GenSigTimeoutTime_CADM" SG_ 2654486531 CBV_bit7 0;
BA_ "GenSigTimeoutTime_DMSM" SG_ 2654486531 CBV_bit7 0;
BA_ "GenSigTimeoutTime_DTCM" SG_ 2654486531 CBV_bit7 0;
BA_ "GenSigTimeoutTime_ECM" SG_ 2654486531 CBV_bit7 0;
BA_ "GenSigTimeoutTime_EVCU2" SG_ 2654486531 CBV_bit7 0;
BA_ "GenSigTimeoutTime_GNMM" SG_ 2654486531 CBV_bit7 0;
BA_ "GenSigTimeoutTime_HCP" SG_ 2654486531 CBV_bit7 0;
BA_ "GenSigTimeoutTime_IPC" SG_ 2654486531 CBV_bit7 0;
BA_ "GenSigTimeoutTime_RFHM" SG_ 2654486531 CBV_bit7 0;
BA_ "GenSigTimeoutTime_SGW" SG_ 2654486531 CBV_bit7 0;
BA_ "GenSigTimeoutTime_TCM" SG_ 2654486531 CBV_bit7 0;
BA_ "GenSigTimeoutTime_AGSM" SG_ 2654486531 SourceNodeIdentifier 0;
BA_ "GenSigTimeoutTime_BCM" SG_ 2654486531 SourceNodeIdentifier 0;
BA_ "GenSigTimeoutTime_BSM" SG_ 2654486531 SourceNodeIdentifier 0;
BA_ "GenSigTimeoutTime_CADM" SG_ 2654486531 SourceNodeIdentifier 0;
BA_ "GenSigTimeoutTime_DMSM" SG_ 2654486531 SourceNodeIdentifier 0;
BA_ "GenSigTimeoutTime_DTCM" SG_ 2654486531 SourceNodeIdentifier 0;
BA_ "GenSigTimeoutTime_ECM" SG_ 2654486531 SourceNodeIdentifier 0;
BA_ "GenSigTimeoutTime_EVCU2" SG_ 2654486531 SourceNodeIdentifier 0;
BA_ "GenSigTimeoutTime_GNMM" SG_ 2654486531 SourceNodeIdentifier 0;
BA_ "GenSigTimeoutTime_HCP" SG_ 2654486531 SourceNodeIdentifier 0;
BA_ "GenSigTimeoutTime_IPC" SG_ 2654486531 SourceNodeIdentifier 0;
BA_ "GenSigTimeoutTime_RFHM" SG_ 2654486531 SourceNodeIdentifier 0;
BA_ "GenSigTimeoutTime_SGW" SG_ 2654486531 SourceNodeIdentifier 0;
BA_ "GenSigTimeoutTime_TCM" SG_ 2654486531 SourceNodeIdentifier 0;
BA_ "GenSigTimeoutTime_AGSM" SG_ 2654486593 CBV_bit0_RepeatMessageRequestBit 0;
BA_ "GenSigTimeoutTime_BCM" SG_ 2654486593 CBV_bit0_RepeatMessageRequestBit 0;
BA_ "GenSigTimeoutTime_BSM" SG_ 2654486593 CBV_bit0_RepeatMessageRequestBit 0;
BA_ "GenSigTimeoutTime_CADM" SG_ 2654486593 CBV_bit0_RepeatMessageRequestBit 0;
BA_ "GenSigTimeoutTime_DMSM" SG_ 2654486593 CBV_bit0_RepeatMessageRequestBit 0;
BA_ "GenSigTimeoutTime_DTCM" SG_ 2654486593 CBV_bit0_RepeatMessageRequestBit 0;
BA_ "GenSigTimeoutTime_ECM" SG_ 2654486593 CBV_bit0_RepeatMessageRequestBit 0;
BA_ "GenSigTimeoutTime_EVCU2" SG_ 2654486593 CBV_bit0_RepeatMessageRequestBit 0;
BA_ "GenSigTimeoutTime_GNMM" SG_ 2654486593 CBV_bit0_RepeatMessageRequestBit 0;
BA_ "GenSigTimeoutTime_HCP" SG_ 2654486593 CBV_bit0_RepeatMessageRequestBit 0;
BA_ "GenSigTimeoutTime_IPC" SG_ 2654486593 CBV_bit0_RepeatMessageRequestBit 0;
BA_ "GenSigTimeoutTime_RFHM" SG_ 2654486593 CBV_bit0_RepeatMessageRequestBit 0;
BA_ "GenSigTimeoutTime_SGW" SG_ 2654486593 CBV_bit0_RepeatMessageRequestBit 0;
BA_ "GenSigTimeoutTime_TCM" SG_ 2654486593 CBV_bit0_RepeatMessageRequestBit 0;
BA_ "GenSigTimeoutTime_AGSM" SG_ 2654486593 CBV_bit1 0;
BA_ "GenSigTimeoutTime_BCM" SG_ 2654486593 CBV_bit1 0;
BA_ "GenSigTimeoutTime_BSM" SG_ 2654486593 CBV_bit1 0;
BA_ "GenSigTimeoutTime_CADM" SG_ 2654486593 CBV_bit1 0;
BA_ "GenSigTimeoutTime_DMSM" SG_ 2654486593 CBV_bit1 0;
BA_ "GenSigTimeoutTime_DTCM" SG_ 2654486593 CBV_bit1 0;
BA_ "GenSigTimeoutTime_ECM" SG_ 2654486593 CBV_bit1 0;
BA_ "GenSigTimeoutTime_EVCU2" SG_ 2654486593 CBV_bit1 0;
BA_ "GenSigTimeoutTime_GNMM" SG_ 2654486593 CBV_bit1 0;
BA_ "GenSigTimeoutTime_HCP" SG_ 2654486593 CBV_bit1 0;
BA_ "GenSigTimeoutTime_IPC" SG_ 2654486593 CBV_bit1 0;
BA_ "GenSigTimeoutTime_RFHM" SG_ 2654486593 CBV_bit1 0;
BA_ "GenSigTimeoutTime_SGW" SG_ 2654486593 CBV_bit1 0;
BA_ "GenSigTimeoutTime_TCM" SG_ 2654486593 CBV_bit1 0;
BA_ "GenSigTimeoutTime_AGSM" SG_ 2654486593 CBV_bit2 0;
BA_ "GenSigTimeoutTime_BCM" SG_ 2654486593 CBV_bit2 0;
BA_ "GenSigTimeoutTime_BSM" SG_ 2654486593 CBV_bit2 0;
BA_ "GenSigTimeoutTime_CADM" SG_ 2654486593 CBV_bit2 0;
BA_ "GenSigTimeoutTime_DMSM" SG_ 2654486593 CBV_bit2 0;
BA_ "GenSigTimeoutTime_DTCM" SG_ 2654486593 CBV_bit2 0;
BA_ "GenSigTimeoutTime_ECM" SG_ 2654486593 CBV_bit2 0;
BA_ "GenSigTimeoutTime_EVCU2" SG_ 2654486593 CBV_bit2 0;
BA_ "GenSigTimeoutTime_GNMM" SG_ 2654486593 CBV_bit2 0;
BA_ "GenSigTimeoutTime_HCP" SG_ 2654486593 CBV_bit2 0;
BA_ "GenSigTimeoutTime_IPC" SG_ 2654486593 CBV_bit2 0;
BA_ "GenSigTimeoutTime_RFHM" SG_ 2654486593 CBV_bit2 0;
BA_ "GenSigTimeoutTime_SGW" SG_ 2654486593 CBV_bit2 0;
BA_ "GenSigTimeoutTime_TCM" SG_ 2654486593 CBV_bit2 0;
BA_ "GenSigTimeoutTime_AGSM" SG_ 2654486593 CBV_bit3_NMCoordinatorBit 0;
BA_ "GenSigTimeoutTime_BCM" SG_ 2654486593 CBV_bit3_NMCoordinatorBit 0;
BA_ "GenSigTimeoutTime_BSM" SG_ 2654486593 CBV_bit3_NMCoordinatorBit 0;
BA_ "GenSigTimeoutTime_CADM" SG_ 2654486593 CBV_bit3_NMCoordinatorBit 0;
BA_ "GenSigTimeoutTime_DMSM" SG_ 2654486593 CBV_bit3_NMCoordinatorBit 0;
BA_ "GenSigTimeoutTime_DTCM" SG_ 2654486593 CBV_bit3_NMCoordinatorBit 0;
BA_ "GenSigTimeoutTime_ECM" SG_ 2654486593 CBV_bit3_NMCoordinatorBit 0;
BA_ "GenSigTimeoutTime_EVCU2" SG_ 2654486593 CBV_bit3_NMCoordinatorBit 0;
BA_ "GenSigTimeoutTime_GNMM" SG_ 2654486593 CBV_bit3_NMCoordinatorBit 0;
BA_ "GenSigTimeoutTime_HCP" SG_ 2654486593 CBV_bit3_NMCoordinatorBit 0;
BA_ "GenSigTimeoutTime_IPC" SG_ 2654486593 CBV_bit3_NMCoordinatorBit 0;
BA_ "GenSigTimeoutTime_RFHM" SG_ 2654486593 CBV_bit3_NMCoordinatorBit 0;
BA_ "GenSigTimeoutTime_SGW" SG_ 2654486593 CBV_bit3_NMCoordinatorBit 0;
BA_ "GenSigTimeoutTime_TCM" SG_ 2654486593 CBV_bit3_NMCoordinatorBit 0;
BA_ "GenSigTimeoutTime_AGSM" SG_ 2654486593 CBV_bit4_ActiveWakeupBit 0;
BA_ "GenSigTimeoutTime_BCM" SG_ 2654486593 CBV_bit4_ActiveWakeupBit 0;
BA_ "GenSigTimeoutTime_BSM" SG_ 2654486593 CBV_bit4_ActiveWakeupBit 0;
BA_ "GenSigTimeoutTime_CADM" SG_ 2654486593 CBV_bit4_ActiveWakeupBit 0;
BA_ "GenSigTimeoutTime_DMSM" SG_ 2654486593 CBV_bit4_ActiveWakeupBit 0;
BA_ "GenSigTimeoutTime_DTCM" SG_ 2654486593 CBV_bit4_ActiveWakeupBit 0;
BA_ "GenSigTimeoutTime_ECM" SG_ 2654486593 CBV_bit4_ActiveWakeupBit 0;
BA_ "GenSigTimeoutTime_EVCU2" SG_ 2654486593 CBV_bit4_ActiveWakeupBit 0;
BA_ "GenSigTimeoutTime_GNMM" SG_ 2654486593 CBV_bit4_ActiveWakeupBit 0;
BA_ "GenSigTimeoutTime_HCP" SG_ 2654486593 CBV_bit4_ActiveWakeupBit 0;
BA_ "GenSigTimeoutTime_IPC" SG_ 2654486593 CBV_bit4_ActiveWakeupBit 0;
BA_ "GenSigTimeoutTime_RFHM" SG_ 2654486593 CBV_bit4_ActiveWakeupBit 0;
BA_ "GenSigTimeoutTime_SGW" SG_ 2654486593 CBV_bit4_ActiveWakeupBit 0;
BA_ "GenSigTimeoutTime_TCM" SG_ 2654486593 CBV_bit4_ActiveWakeupBit 0;
BA_ "GenSigTimeoutTime_AGSM" SG_ 2654486593 CBV_bit5 0;
BA_ "GenSigTimeoutTime_BCM" SG_ 2654486593 CBV_bit5 0;
BA_ "GenSigTimeoutTime_BSM" SG_ 2654486593 CBV_bit5 0;
BA_ "GenSigTimeoutTime_CADM" SG_ 2654486593 CBV_bit5 0;
BA_ "GenSigTimeoutTime_DMSM" SG_ 2654486593 CBV_bit5 0;
BA_ "GenSigTimeoutTime_DTCM" SG_ 2654486593 CBV_bit5 0;
BA_ "GenSigTimeoutTime_ECM" SG_ 2654486593 CBV_bit5 0;
BA_ "GenSigTimeoutTime_EVCU2" SG_ 2654486593 CBV_bit5 0;
BA_ "GenSigTimeoutTime_GNMM" SG_ 2654486593 CBV_bit5 0;
BA_ "GenSigTimeoutTime_HCP" SG_ 2654486593 CBV_bit5 0;
BA_ "GenSigTimeoutTime_IPC" SG_ 2654486593 CBV_bit5 0;
BA_ "GenSigTimeoutTime_RFHM" SG_ 2654486593 CBV_bit5 0;
BA_ "GenSigTimeoutTime_SGW" SG_ 2654486593 CBV_bit5 0;
BA_ "GenSigTimeoutTime_TCM" SG_ 2654486593 CBV_bit5 0;
BA_ "GenSigTimeoutTime_AGSM" SG_ 2654486593 CBV_bit6_PartialNtwInfBit 0;
BA_ "GenSigTimeoutTime_BCM" SG_ 2654486593 CBV_bit6_PartialNtwInfBit 0;
BA_ "GenSigTimeoutTime_BSM" SG_ 2654486593 CBV_bit6_PartialNtwInfBit 0;
BA_ "GenSigTimeoutTime_CADM" SG_ 2654486593 CBV_bit6_PartialNtwInfBit 0;
BA_ "GenSigTimeoutTime_DMSM" SG_ 2654486593 CBV_bit6_PartialNtwInfBit 0;
BA_ "GenSigTimeoutTime_DTCM" SG_ 2654486593 CBV_bit6_PartialNtwInfBit 0;
BA_ "GenSigTimeoutTime_ECM" SG_ 2654486593 CBV_bit6_PartialNtwInfBit 0;
BA_ "GenSigTimeoutTime_EVCU2" SG_ 2654486593 CBV_bit6_PartialNtwInfBit 0;
BA_ "GenSigTimeoutTime_GNMM" SG_ 2654486593 CBV_bit6_PartialNtwInfBit 0;
BA_ "GenSigTimeoutTime_HCP" SG_ 2654486593 CBV_bit6_PartialNtwInfBit 0;
BA_ "GenSigTimeoutTime_IPC" SG_ 2654486593 CBV_bit6_PartialNtwInfBit 0;
BA_ "GenSigTimeoutTime_RFHM" SG_ 2654486593 CBV_bit6_PartialNtwInfBit 0;
BA_ "GenSigTimeoutTime_SGW" SG_ 2654486593 CBV_bit6_PartialNtwInfBit 0;
BA_ "GenSigTimeoutTime_TCM" SG_ 2654486593 CBV_bit6_PartialNtwInfBit 0;
BA_ "GenSigTimeoutTime_AGSM" SG_ 2654486593 CBV_bit7 0;
BA_ "GenSigTimeoutTime_BCM" SG_ 2654486593 CBV_bit7 0;
BA_ "GenSigTimeoutTime_BSM" SG_ 2654486593 CBV_bit7 0;
BA_ "GenSigTimeoutTime_CADM" SG_ 2654486593 CBV_bit7 0;
BA_ "GenSigTimeoutTime_DMSM" SG_ 2654486593 CBV_bit7 0;
BA_ "GenSigTimeoutTime_DTCM" SG_ 2654486593 CBV_bit7 0;
BA_ "GenSigTimeoutTime_ECM" SG_ 2654486593 CBV_bit7 0;
BA_ "GenSigTimeoutTime_EVCU2" SG_ 2654486593 CBV_bit7 0;
BA_ "GenSigTimeoutTime_GNMM" SG_ 2654486593 CBV_bit7 0;
BA_ "GenSigTimeoutTime_HCP" SG_ 2654486593 CBV_bit7 0;
BA_ "GenSigTimeoutTime_IPC" SG_ 2654486593 CBV_bit7 0;
BA_ "GenSigTimeoutTime_RFHM" SG_ 2654486593 CBV_bit7 0;
BA_ "GenSigTimeoutTime_SGW" SG_ 2654486593 CBV_bit7 0;
BA_ "GenSigTimeoutTime_TCM" SG_ 2654486593 CBV_bit7 0;
BA_ "GenSigTimeoutTime_AGSM" SG_ 2654486593 SourceNodeIdentifier 0;
BA_ "GenSigTimeoutTime_BCM" SG_ 2654486593 SourceNodeIdentifier 0;
BA_ "GenSigTimeoutTime_BSM" SG_ 2654486593 SourceNodeIdentifier 0;
BA_ "GenSigTimeoutTime_CADM" SG_ 2654486593 SourceNodeIdentifier 0;
BA_ "GenSigTimeoutTime_DMSM" SG_ 2654486593 SourceNodeIdentifier 0;
BA_ "GenSigTimeoutTime_DTCM" SG_ 2654486593 SourceNodeIdentifier 0;
BA_ "GenSigTimeoutTime_ECM" SG_ 2654486593 SourceNodeIdentifier 0;
BA_ "GenSigTimeoutTime_EVCU2" SG_ 2654486593 SourceNodeIdentifier 0;
BA_ "GenSigTimeoutTime_GNMM" SG_ 2654486593 SourceNodeIdentifier 0;
BA_ "GenSigTimeoutTime_HCP" SG_ 2654486593 SourceNodeIdentifier 0;
BA_ "GenSigTimeoutTime_IPC" SG_ 2654486593 SourceNodeIdentifier 0;
BA_ "GenSigTimeoutTime_RFHM" SG_ 2654486593 SourceNodeIdentifier 0;
BA_ "GenSigTimeoutTime_SGW" SG_ 2654486593 SourceNodeIdentifier 0;
BA_ "GenSigTimeoutTime_TCM" SG_ 2654486593 SourceNodeIdentifier 0;
BA_ "GenSigTimeoutTime_AGSM" SG_ 2654486640 CBV_bit0_RepeatMessageRequestBit 0;
BA_ "GenSigTimeoutTime_BCM" SG_ 2654486640 CBV_bit0_RepeatMessageRequestBit 0;
BA_ "GenSigTimeoutTime_BSM" SG_ 2654486640 CBV_bit0_RepeatMessageRequestBit 0;
BA_ "GenSigTimeoutTime_CADM" SG_ 2654486640 CBV_bit0_RepeatMessageRequestBit 0;
BA_ "GenSigTimeoutTime_DMSM" SG_ 2654486640 CBV_bit0_RepeatMessageRequestBit 0;
BA_ "GenSigTimeoutTime_DTCM" SG_ 2654486640 CBV_bit0_RepeatMessageRequestBit 0;
BA_ "GenSigTimeoutTime_ECM" SG_ 2654486640 CBV_bit0_RepeatMessageRequestBit 0;
BA_ "GenSigTimeoutTime_EVCU2" SG_ 2654486640 CBV_bit0_RepeatMessageRequestBit 0;
BA_ "GenSigTimeoutTime_GNMM" SG_ 2654486640 CBV_bit0_RepeatMessageRequestBit 0;
BA_ "GenSigTimeoutTime_HCP" SG_ 2654486640 CBV_bit0_RepeatMessageRequestBit 0;
BA_ "GenSigTimeoutTime_IPC" SG_ 2654486640 CBV_bit0_RepeatMessageRequestBit 0;
BA_ "GenSigTimeoutTime_RFHM" SG_ 2654486640 CBV_bit0_RepeatMessageRequestBit 0;
BA_ "GenSigTimeoutTime_SGW" SG_ 2654486640 CBV_bit0_RepeatMessageRequestBit 0;
BA_ "GenSigTimeoutTime_TCM" SG_ 2654486640 CBV_bit0_RepeatMessageRequestBit 0;
BA_ "GenSigTimeoutTime_AGSM" SG_ 2654486640 CBV_bit1 0;
BA_ "GenSigTimeoutTime_BCM" SG_ 2654486640 CBV_bit1 0;
BA_ "GenSigTimeoutTime_BSM" SG_ 2654486640 CBV_bit1 0;
BA_ "GenSigTimeoutTime_CADM" SG_ 2654486640 CBV_bit1 0;
BA_ "GenSigTimeoutTime_DMSM" SG_ 2654486640 CBV_bit1 0;
BA_ "GenSigTimeoutTime_DTCM" SG_ 2654486640 CBV_bit1 0;
BA_ "GenSigTimeoutTime_ECM" SG_ 2654486640 CBV_bit1 0;
BA_ "GenSigTimeoutTime_EVCU2" SG_ 2654486640 CBV_bit1 0;
BA_ "GenSigTimeoutTime_GNMM" SG_ 2654486640 CBV_bit1 0;
BA_ "GenSigTimeoutTime_HCP" SG_ 2654486640 CBV_bit1 0;
BA_ "GenSigTimeoutTime_IPC" SG_ 2654486640 CBV_bit1 0;
BA_ "GenSigTimeoutTime_RFHM" SG_ 2654486640 CBV_bit1 0;
BA_ "GenSigTimeoutTime_SGW" SG_ 2654486640 CBV_bit1 0;
BA_ "GenSigTimeoutTime_TCM" SG_ 2654486640 CBV_bit1 0;
BA_ "GenSigTimeoutTime_AGSM" SG_ 2654486640 CBV_bit2 0;
BA_ "GenSigTimeoutTime_BCM" SG_ 2654486640 CBV_bit2 0;
BA_ "GenSigTimeoutTime_BSM" SG_ 2654486640 CBV_bit2 0;
BA_ "GenSigTimeoutTime_CADM" SG_ 2654486640 CBV_bit2 0;
BA_ "GenSigTimeoutTime_DMSM" SG_ 2654486640 CBV_bit2 0;
BA_ "GenSigTimeoutTime_DTCM" SG_ 2654486640 CBV_bit2 0;
BA_ "GenSigTimeoutTime_ECM" SG_ 2654486640 CBV_bit2 0;
BA_ "GenSigTimeoutTime_EVCU2" SG_ 2654486640 CBV_bit2 0;
BA_ "GenSigTimeoutTime_GNMM" SG_ 2654486640 CBV_bit2 0;
BA_ "GenSigTimeoutTime_HCP" SG_ 2654486640 CBV_bit2 0;
BA_ "GenSigTimeoutTime_IPC" SG_ 2654486640 CBV_bit2 0;
BA_ "GenSigTimeoutTime_RFHM" SG_ 2654486640 CBV_bit2 0;
BA_ "GenSigTimeoutTime_SGW" SG_ 2654486640 CBV_bit2 0;
BA_ "GenSigTimeoutTime_TCM" SG_ 2654486640 CBV_bit2 0;
BA_ "GenSigTimeoutTime_AGSM" SG_ 2654486640 CBV_bit3_NMCoordinatorBit 0;
BA_ "GenSigTimeoutTime_BCM" SG_ 2654486640 CBV_bit3_NMCoordinatorBit 0;
BA_ "GenSigTimeoutTime_BSM" SG_ 2654486640 CBV_bit3_NMCoordinatorBit 0;
BA_ "GenSigTimeoutTime_CADM" SG_ 2654486640 CBV_bit3_NMCoordinatorBit 0;
BA_ "GenSigTimeoutTime_DMSM" SG_ 2654486640 CBV_bit3_NMCoordinatorBit 0;
BA_ "GenSigTimeoutTime_DTCM" SG_ 2654486640 CBV_bit3_NMCoordinatorBit 0;
BA_ "GenSigTimeoutTime_ECM" SG_ 2654486640 CBV_bit3_NMCoordinatorBit 0;
BA_ "GenSigTimeoutTime_EVCU2" SG_ 2654486640 CBV_bit3_NMCoordinatorBit 0;
BA_ "GenSigTimeoutTime_GNMM" SG_ 2654486640 CBV_bit3_NMCoordinatorBit 0;
BA_ "GenSigTimeoutTime_HCP" SG_ 2654486640 CBV_bit3_NMCoordinatorBit 0;
BA_ "GenSigTimeoutTime_IPC" SG_ 2654486640 CBV_bit3_NMCoordinatorBit 0;
BA_ "GenSigTimeoutTime_RFHM" SG_ 2654486640 CBV_bit3_NMCoordinatorBit 0;
BA_ "GenSigTimeoutTime_SGW" SG_ 2654486640 CBV_bit3_NMCoordinatorBit 0;
BA_ "GenSigTimeoutTime_TCM" SG_ 2654486640 CBV_bit3_NMCoordinatorBit 0;
BA_ "GenSigTimeoutTime_AGSM" SG_ 2654486640 CBV_bit4_ActiveWakeupBit 0;
BA_ "GenSigTimeoutTime_BCM" SG_ 2654486640 CBV_bit4_ActiveWakeupBit 0;
BA_ "GenSigTimeoutTime_BSM" SG_ 2654486640 CBV_bit4_ActiveWakeupBit 0;
BA_ "GenSigTimeoutTime_CADM" SG_ 2654486640 CBV_bit4_ActiveWakeupBit 0;
BA_ "GenSigTimeoutTime_DMSM" SG_ 2654486640 CBV_bit4_ActiveWakeupBit 0;
BA_ "GenSigTimeoutTime_DTCM" SG_ 2654486640 CBV_bit4_ActiveWakeupBit 0;
BA_ "GenSigTimeoutTime_ECM" SG_ 2654486640 CBV_bit4_ActiveWakeupBit 0;
BA_ "GenSigTimeoutTime_EVCU2" SG_ 2654486640 CBV_bit4_ActiveWakeupBit 0;
BA_ "GenSigTimeoutTime_GNMM" SG_ 2654486640 CBV_bit4_ActiveWakeupBit 0;
BA_ "GenSigTimeoutTime_HCP" SG_ 2654486640 CBV_bit4_ActiveWakeupBit 0;
BA_ "GenSigTimeoutTime_IPC" SG_ 2654486640 CBV_bit4_ActiveWakeupBit 0;
BA_ "GenSigTimeoutTime_RFHM" SG_ 2654486640 CBV_bit4_ActiveWakeupBit 0;
BA_ "GenSigTimeoutTime_SGW" SG_ 2654486640 CBV_bit4_ActiveWakeupBit 0;
BA_ "GenSigTimeoutTime_TCM" SG_ 2654486640 CBV_bit4_ActiveWakeupBit 0;
BA_ "GenSigTimeoutTime_AGSM" SG_ 2654486640 CBV_bit5 0;
BA_ "GenSigTimeoutTime_BCM" SG_ 2654486640 CBV_bit5 0;
BA_ "GenSigTimeoutTime_BSM" SG_ 2654486640 CBV_bit5 0;
BA_ "GenSigTimeoutTime_CADM" SG_ 2654486640 CBV_bit5 0;
BA_ "GenSigTimeoutTime_DMSM" SG_ 2654486640 CBV_bit5 0;
BA_ "GenSigTimeoutTime_DTCM" SG_ 2654486640 CBV_bit5 0;
BA_ "GenSigTimeoutTime_ECM" SG_ 2654486640 CBV_bit5 0;
BA_ "GenSigTimeoutTime_EVCU2" SG_ 2654486640 CBV_bit5 0;
BA_ "GenSigTimeoutTime_GNMM" SG_ 2654486640 CBV_bit5 0;
BA_ "GenSigTimeoutTime_HCP" SG_ 2654486640 CBV_bit5 0;
BA_ "GenSigTimeoutTime_IPC" SG_ 2654486640 CBV_bit5 0;
BA_ "GenSigTimeoutTime_RFHM" SG_ 2654486640 CBV_bit5 0;
BA_ "GenSigTimeoutTime_SGW" SG_ 2654486640 CBV_bit5 0;
BA_ "GenSigTimeoutTime_TCM" SG_ 2654486640 CBV_bit5 0;
BA_ "GenSigTimeoutTime_AGSM" SG_ 2654486640 CBV_bit6_PartialNtwInfBit 0;
BA_ "GenSigTimeoutTime_BCM" SG_ 2654486640 CBV_bit6_PartialNtwInfBit 0;
BA_ "GenSigTimeoutTime_BSM" SG_ 2654486640 CBV_bit6_PartialNtwInfBit 0;
BA_ "GenSigTimeoutTime_CADM" SG_ 2654486640 CBV_bit6_PartialNtwInfBit 0;
BA_ "GenSigTimeoutTime_DMSM" SG_ 2654486640 CBV_bit6_PartialNtwInfBit 0;
BA_ "GenSigTimeoutTime_DTCM" SG_ 2654486640 CBV_bit6_PartialNtwInfBit 0;
BA_ "GenSigTimeoutTime_ECM" SG_ 2654486640 CBV_bit6_PartialNtwInfBit 0;
BA_ "GenSigTimeoutTime_EVCU2" SG_ 2654486640 CBV_bit6_PartialNtwInfBit 0;
BA_ "GenSigTimeoutTime_GNMM" SG_ 2654486640 CBV_bit6_PartialNtwInfBit 0;
BA_ "GenSigTimeoutTime_HCP" SG_ 2654486640 CBV_bit6_PartialNtwInfBit 0;
BA_ "GenSigTimeoutTime_IPC" SG_ 2654486640 CBV_bit6_PartialNtwInfBit 0;
BA_ "GenSigTimeoutTime_RFHM" SG_ 2654486640 CBV_bit6_PartialNtwInfBit 0;
BA_ "GenSigTimeoutTime_SGW" SG_ 2654486640 CBV_bit6_PartialNtwInfBit 0;
BA_ "GenSigTimeoutTime_TCM" SG_ 2654486640 CBV_bit6_PartialNtwInfBit 0;
BA_ "GenSigTimeoutTime_AGSM" SG_ 2654486640 CBV_bit7 0;
BA_ "GenSigTimeoutTime_BCM" SG_ 2654486640 CBV_bit7 0;
BA_ "GenSigTimeoutTime_BSM" SG_ 2654486640 CBV_bit7 0;
BA_ "GenSigTimeoutTime_CADM" SG_ 2654486640 CBV_bit7 0;
BA_ "GenSigTimeoutTime_DMSM" SG_ 2654486640 CBV_bit7 0;
BA_ "GenSigTimeoutTime_DTCM" SG_ 2654486640 CBV_bit7 0;
BA_ "GenSigTimeoutTime_ECM" SG_ 2654486640 CBV_bit7 0;
BA_ "GenSigTimeoutTime_EVCU2" SG_ 2654486640 CBV_bit7 0;
BA_ "GenSigTimeoutTime_GNMM" SG_ 2654486640 CBV_bit7 0;
BA_ "GenSigTimeoutTime_HCP" SG_ 2654486640 CBV_bit7 0;
BA_ "GenSigTimeoutTime_IPC" SG_ 2654486640 CBV_bit7 0;
BA_ "GenSigTimeoutTime_RFHM" SG_ 2654486640 CBV_bit7 0;
BA_ "GenSigTimeoutTime_SGW" SG_ 2654486640 CBV_bit7 0;
BA_ "GenSigTimeoutTime_TCM" SG_ 2654486640 CBV_bit7 0;
BA_ "GenSigTimeoutTime_AGSM" SG_ 2654486640 SourceNodeIdentifier 0;
BA_ "GenSigTimeoutTime_BCM" SG_ 2654486640 SourceNodeIdentifier 0;
BA_ "GenSigTimeoutTime_BSM" SG_ 2654486640 SourceNodeIdentifier 0;
BA_ "GenSigTimeoutTime_CADM" SG_ 2654486640 SourceNodeIdentifier 0;
BA_ "GenSigTimeoutTime_DMSM" SG_ 2654486640 SourceNodeIdentifier 0;
BA_ "GenSigTimeoutTime_DTCM" SG_ 2654486640 SourceNodeIdentifier 0;
BA_ "GenSigTimeoutTime_ECM" SG_ 2654486640 SourceNodeIdentifier 0;
BA_ "GenSigTimeoutTime_EVCU2" SG_ 2654486640 SourceNodeIdentifier 0;
BA_ "GenSigTimeoutTime_GNMM" SG_ 2654486640 SourceNodeIdentifier 0;
BA_ "GenSigTimeoutTime_HCP" SG_ 2654486640 SourceNodeIdentifier 0;
BA_ "GenSigTimeoutTime_IPC" SG_ 2654486640 SourceNodeIdentifier 0;
BA_ "GenSigTimeoutTime_RFHM" SG_ 2654486640 SourceNodeIdentifier 0;
BA_ "GenSigTimeoutTime_SGW" SG_ 2654486640 SourceNodeIdentifier 0;
BA_ "GenSigTimeoutTime_TCM" SG_ 2654486640 SourceNodeIdentifier 0;
BA_ "GenSigTimeoutTime_AGSM" SG_ 2654486539 CBV_bit0_RepeatMessageRequestBit 0;
BA_ "GenSigTimeoutTime_BCM" SG_ 2654486539 CBV_bit0_RepeatMessageRequestBit 0;
BA_ "GenSigTimeoutTime_BSM" SG_ 2654486539 CBV_bit0_RepeatMessageRequestBit 0;
BA_ "GenSigTimeoutTime_CADM" SG_ 2654486539 CBV_bit0_RepeatMessageRequestBit 0;
BA_ "GenSigTimeoutTime_DMSM" SG_ 2654486539 CBV_bit0_RepeatMessageRequestBit 0;
BA_ "GenSigTimeoutTime_DTCM" SG_ 2654486539 CBV_bit0_RepeatMessageRequestBit 0;
BA_ "GenSigTimeoutTime_ECM" SG_ 2654486539 CBV_bit0_RepeatMessageRequestBit 0;
BA_ "GenSigTimeoutTime_EVCU2" SG_ 2654486539 CBV_bit0_RepeatMessageRequestBit 0;
BA_ "GenSigTimeoutTime_GNMM" SG_ 2654486539 CBV_bit0_RepeatMessageRequestBit 0;
BA_ "GenSigTimeoutTime_HCP" SG_ 2654486539 CBV_bit0_RepeatMessageRequestBit 0;
BA_ "GenSigTimeoutTime_IPC" SG_ 2654486539 CBV_bit0_RepeatMessageRequestBit 0;
BA_ "GenSigTimeoutTime_RFHM" SG_ 2654486539 CBV_bit0_RepeatMessageRequestBit 0;
BA_ "GenSigTimeoutTime_SGW" SG_ 2654486539 CBV_bit0_RepeatMessageRequestBit 0;
BA_ "GenSigTimeoutTime_TCM" SG_ 2654486539 CBV_bit0_RepeatMessageRequestBit 0;
BA_ "GenSigTimeoutTime_AGSM" SG_ 2654486539 CBV_bit1 0;
BA_ "GenSigTimeoutTime_BCM" SG_ 2654486539 CBV_bit1 0;
BA_ "GenSigTimeoutTime_BSM" SG_ 2654486539 CBV_bit1 0;
BA_ "GenSigTimeoutTime_CADM" SG_ 2654486539 CBV_bit1 0;
BA_ "GenSigTimeoutTime_DMSM" SG_ 2654486539 CBV_bit1 0;
BA_ "GenSigTimeoutTime_DTCM" SG_ 2654486539 CBV_bit1 0;
BA_ "GenSigTimeoutTime_ECM" SG_ 2654486539 CBV_bit1 0;
BA_ "GenSigTimeoutTime_EVCU2" SG_ 2654486539 CBV_bit1 0;
BA_ "GenSigTimeoutTime_GNMM" SG_ 2654486539 CBV_bit1 0;
BA_ "GenSigTimeoutTime_HCP" SG_ 2654486539 CBV_bit1 0;
BA_ "GenSigTimeoutTime_IPC" SG_ 2654486539 CBV_bit1 0;
BA_ "GenSigTimeoutTime_RFHM" SG_ 2654486539 CBV_bit1 0;
BA_ "GenSigTimeoutTime_SGW" SG_ 2654486539 CBV_bit1 0;
BA_ "GenSigTimeoutTime_TCM" SG_ 2654486539 CBV_bit1 0;
BA_ "GenSigTimeoutTime_AGSM" SG_ 2654486539 CBV_bit2 0;
BA_ "GenSigTimeoutTime_BCM" SG_ 2654486539 CBV_bit2 0;
BA_ "GenSigTimeoutTime_BSM" SG_ 2654486539 CBV_bit2 0;
BA_ "GenSigTimeoutTime_CADM" SG_ 2654486539 CBV_bit2 0;
BA_ "GenSigTimeoutTime_DMSM" SG_ 2654486539 CBV_bit2 0;
BA_ "GenSigTimeoutTime_DTCM" SG_ 2654486539 CBV_bit2 0;
BA_ "GenSigTimeoutTime_ECM" SG_ 2654486539 CBV_bit2 0;
BA_ "GenSigTimeoutTime_EVCU2" SG_ 2654486539 CBV_bit2 0;
BA_ "GenSigTimeoutTime_GNMM" SG_ 2654486539 CBV_bit2 0;
BA_ "GenSigTimeoutTime_HCP" SG_ 2654486539 CBV_bit2 0;
BA_ "GenSigTimeoutTime_IPC" SG_ 2654486539 CBV_bit2 0;
BA_ "GenSigTimeoutTime_RFHM" SG_ 2654486539 CBV_bit2 0;
BA_ "GenSigTimeoutTime_SGW" SG_ 2654486539 CBV_bit2 0;
BA_ "GenSigTimeoutTime_TCM" SG_ 2654486539 CBV_bit2 0;
BA_ "GenSigTimeoutTime_AGSM" SG_ 2654486539 CBV_bit3_NMCoordinatorBit 0;
BA_ "GenSigTimeoutTime_BCM" SG_ 2654486539 CBV_bit3_NMCoordinatorBit 0;
BA_ "GenSigTimeoutTime_BSM" SG_ 2654486539 CBV_bit3_NMCoordinatorBit 0;
BA_ "GenSigTimeoutTime_CADM" SG_ 2654486539 CBV_bit3_NMCoordinatorBit 0;
BA_ "GenSigTimeoutTime_DMSM" SG_ 2654486539 CBV_bit3_NMCoordinatorBit 0;
BA_ "GenSigTimeoutTime_DTCM" SG_ 2654486539 CBV_bit3_NMCoordinatorBit 0;
BA_ "GenSigTimeoutTime_ECM" SG_ 2654486539 CBV_bit3_NMCoordinatorBit 0;
BA_ "GenSigTimeoutTime_EVCU2" SG_ 2654486539 CBV_bit3_NMCoordinatorBit 0;
BA_ "GenSigTimeoutTime_GNMM" SG_ 2654486539 CBV_bit3_NMCoordinatorBit 0;
BA_ "GenSigTimeoutTime_HCP" SG_ 2654486539 CBV_bit3_NMCoordinatorBit 0;
BA_ "GenSigTimeoutTime_IPC" SG_ 2654486539 CBV_bit3_NMCoordinatorBit 0;
BA_ "GenSigTimeoutTime_RFHM" SG_ 2654486539 CBV_bit3_NMCoordinatorBit 0;
BA_ "GenSigTimeoutTime_SGW" SG_ 2654486539 CBV_bit3_NMCoordinatorBit 0;
BA_ "GenSigTimeoutTime_TCM" SG_ 2654486539 CBV_bit3_NMCoordinatorBit 0;
BA_ "GenSigTimeoutTime_AGSM" SG_ 2654486539 CBV_bit4_ActiveWakeupBit 0;
BA_ "GenSigTimeoutTime_BCM" SG_ 2654486539 CBV_bit4_ActiveWakeupBit 0;
BA_ "GenSigTimeoutTime_BSM" SG_ 2654486539 CBV_bit4_ActiveWakeupBit 0;
BA_ "GenSigTimeoutTime_CADM" SG_ 2654486539 CBV_bit4_ActiveWakeupBit 0;
BA_ "GenSigTimeoutTime_DMSM" SG_ 2654486539 CBV_bit4_ActiveWakeupBit 0;
BA_ "GenSigTimeoutTime_DTCM" SG_ 2654486539 CBV_bit4_ActiveWakeupBit 0;
BA_ "GenSigTimeoutTime_ECM" SG_ 2654486539 CBV_bit4_ActiveWakeupBit 0;
BA_ "GenSigTimeoutTime_EVCU2" SG_ 2654486539 CBV_bit4_ActiveWakeupBit 0;
BA_ "GenSigTimeoutTime_GNMM" SG_ 2654486539 CBV_bit4_ActiveWakeupBit 0;
BA_ "GenSigTimeoutTime_HCP" SG_ 2654486539 CBV_bit4_ActiveWakeupBit 0;
BA_ "GenSigTimeoutTime_IPC" SG_ 2654486539 CBV_bit4_ActiveWakeupBit 0;
BA_ "GenSigTimeoutTime_RFHM" SG_ 2654486539 CBV_bit4_ActiveWakeupBit 0;
BA_ "GenSigTimeoutTime_SGW" SG_ 2654486539 CBV_bit4_ActiveWakeupBit 0;
BA_ "GenSigTimeoutTime_TCM" SG_ 2654486539 CBV_bit4_ActiveWakeupBit 0;
BA_ "GenSigTimeoutTime_AGSM" SG_ 2654486539 CBV_bit5 0;
BA_ "GenSigTimeoutTime_BCM" SG_ 2654486539 CBV_bit5 0;
BA_ "GenSigTimeoutTime_BSM" SG_ 2654486539 CBV_bit5 0;
BA_ "GenSigTimeoutTime_CADM" SG_ 2654486539 CBV_bit5 0;
BA_ "GenSigTimeoutTime_DMSM" SG_ 2654486539 CBV_bit5 0;
BA_ "GenSigTimeoutTime_DTCM" SG_ 2654486539 CBV_bit5 0;
BA_ "GenSigTimeoutTime_ECM" SG_ 2654486539 CBV_bit5 0;
BA_ "GenSigTimeoutTime_EVCU2" SG_ 2654486539 CBV_bit5 0;
BA_ "GenSigTimeoutTime_GNMM" SG_ 2654486539 CBV_bit5 0;
BA_ "GenSigTimeoutTime_HCP" SG_ 2654486539 CBV_bit5 0;
BA_ "GenSigTimeoutTime_IPC" SG_ 2654486539 CBV_bit5 0;
BA_ "GenSigTimeoutTime_RFHM" SG_ 2654486539 CBV_bit5 0;
BA_ "GenSigTimeoutTime_SGW" SG_ 2654486539 CBV_bit5 0;
BA_ "GenSigTimeoutTime_TCM" SG_ 2654486539 CBV_bit5 0;
BA_ "GenSigTimeoutTime_AGSM" SG_ 2654486539 CBV_bit6_PartialNtwInfBit 0;
BA_ "GenSigTimeoutTime_BCM" SG_ 2654486539 CBV_bit6_PartialNtwInfBit 0;
BA_ "GenSigTimeoutTime_BSM" SG_ 2654486539 CBV_bit6_PartialNtwInfBit 0;
BA_ "GenSigTimeoutTime_CADM" SG_ 2654486539 CBV_bit6_PartialNtwInfBit 0;
BA_ "GenSigTimeoutTime_DMSM" SG_ 2654486539 CBV_bit6_PartialNtwInfBit 0;
BA_ "GenSigTimeoutTime_DTCM" SG_ 2654486539 CBV_bit6_PartialNtwInfBit 0;
BA_ "GenSigTimeoutTime_ECM" SG_ 2654486539 CBV_bit6_PartialNtwInfBit 0;
BA_ "GenSigTimeoutTime_EVCU2" SG_ 2654486539 CBV_bit6_PartialNtwInfBit 0;
BA_ "GenSigTimeoutTime_GNMM" SG_ 2654486539 CBV_bit6_PartialNtwInfBit 0;
BA_ "GenSigTimeoutTime_HCP" SG_ 2654486539 CBV_bit6_PartialNtwInfBit 0;
BA_ "GenSigTimeoutTime_IPC" SG_ 2654486539 CBV_bit6_PartialNtwInfBit 0;
BA_ "GenSigTimeoutTime_RFHM" SG_ 2654486539 CBV_bit6_PartialNtwInfBit 0;
BA_ "GenSigTimeoutTime_SGW" SG_ 2654486539 CBV_bit6_PartialNtwInfBit 0;
BA_ "GenSigTimeoutTime_TCM" SG_ 2654486539 CBV_bit6_PartialNtwInfBit 0;
BA_ "GenSigTimeoutTime_AGSM" SG_ 2654486539 CBV_bit7 0;
BA_ "GenSigTimeoutTime_BCM" SG_ 2654486539 CBV_bit7 0;
BA_ "GenSigTimeoutTime_BSM" SG_ 2654486539 CBV_bit7 0;
BA_ "GenSigTimeoutTime_CADM" SG_ 2654486539 CBV_bit7 0;
BA_ "GenSigTimeoutTime_DMSM" SG_ 2654486539 CBV_bit7 0;
BA_ "GenSigTimeoutTime_DTCM" SG_ 2654486539 CBV_bit7 0;
BA_ "GenSigTimeoutTime_ECM" SG_ 2654486539 CBV_bit7 0;
BA_ "GenSigTimeoutTime_EVCU2" SG_ 2654486539 CBV_bit7 0;
BA_ "GenSigTimeoutTime_GNMM" SG_ 2654486539 CBV_bit7 0;
BA_ "GenSigTimeoutTime_HCP" SG_ 2654486539 CBV_bit7 0;
BA_ "GenSigTimeoutTime_IPC" SG_ 2654486539 CBV_bit7 0;
BA_ "GenSigTimeoutTime_RFHM" SG_ 2654486539 CBV_bit7 0;
BA_ "GenSigTimeoutTime_SGW" SG_ 2654486539 CBV_bit7 0;
BA_ "GenSigTimeoutTime_TCM" SG_ 2654486539 CBV_bit7 0;
BA_ "GenSigTimeoutTime_AGSM" SG_ 2654486539 SourceNodeIdentifier 0;
BA_ "GenSigTimeoutTime_BCM" SG_ 2654486539 SourceNodeIdentifier 0;
BA_ "GenSigTimeoutTime_BSM" SG_ 2654486539 SourceNodeIdentifier 0;
BA_ "GenSigTimeoutTime_CADM" SG_ 2654486539 SourceNodeIdentifier 0;
BA_ "GenSigTimeoutTime_DMSM" SG_ 2654486539 SourceNodeIdentifier 0;
BA_ "GenSigTimeoutTime_DTCM" SG_ 2654486539 SourceNodeIdentifier 0;
BA_ "GenSigTimeoutTime_ECM" SG_ 2654486539 SourceNodeIdentifier 0;
BA_ "GenSigTimeoutTime_EVCU2" SG_ 2654486539 SourceNodeIdentifier 0;
BA_ "GenSigTimeoutTime_GNMM" SG_ 2654486539 SourceNodeIdentifier 0;
BA_ "GenSigTimeoutTime_HCP" SG_ 2654486539 SourceNodeIdentifier 0;
BA_ "GenSigTimeoutTime_IPC" SG_ 2654486539 SourceNodeIdentifier 0;
BA_ "GenSigTimeoutTime_RFHM" SG_ 2654486539 SourceNodeIdentifier 0;
BA_ "GenSigTimeoutTime_SGW" SG_ 2654486539 SourceNodeIdentifier 0;
BA_ "GenSigTimeoutTime_TCM" SG_ 2654486539 SourceNodeIdentifier 0;
VAL_ 1474 AUX1_HLEnbl 0 "Disable" 1 "Enable";
VAL_ 1474 AUX1_PWRMD 0 "Ignition" 1 "Battery";
VAL_ 1474 AUX1_TYPE 0 "Latching" 1 "Momentary";
VAL_ 1474 AUX2_HLEnbl 0 "Disable" 1 "Enable";
VAL_ 1474 AUX2_PWRMD 0 "Ignition" 1 "Battery";
VAL_ 1474 AUX2_TYPE 0 "Latching" 1 "Momentary";
VAL_ 1474 AUX3_HLEnbl 0 "Disable" 1 "Enable";
VAL_ 1474 AUX3_PWRMD 0 "Ignition" 1 "Battery";
VAL_ 1474 AUX3_TYPE 0 "Latching" 1 "Momentary";
VAL_ 1474 AUX4_HLEnbl 0 "Disable" 1 "Enable";
VAL_ 1474 AUX4_PWRMD 0 "Ignition" 1 "Battery";
VAL_ 1474 AUX4_TYPE 0 "Latching" 1 "Momentary";
VAL_ 1474 AUX5_HLEnbl 0 "Disable" 1 "Enable";
VAL_ 1474 AUX5_PWRMD 0 "IGNITION" 1 "BATTERY";
VAL_ 1474 AUX5_TYPE 0 "Latching" 1 "Momentary";
VAL_ 1474 AUX6_HLEnbl 0 "Disable" 1 "Enable";
VAL_ 1474 AUX6_PWRMD 0 "IGNITION" 1 "BATTERY";
VAL_ 1474 AUX6_TYPE 0 "Latching" 1 "Momentary";
VAL_ 1474 Default_Ride_Height 0 "Normal" 1 "Aerodynamic";
VAL_ 1474 Display_Synch 0 "OFF" 1 "ON";
VAL_ 1474 FOA_Alert_Type 0 "Off" 1 "Cluster_Warning" 2 "Cluster_SMS_Warning";
VAL_ 1474 Fuel_Saver_Display 0 "Disable" 1 "Enable";
VAL_ 1474 ParkSenseSignalView 0 "DISABLE" 1 "ENABLE";
VAL_ 1474 PFTM_Alert 0 "Disabled" 1 "Enabled";
VAL_ 1474 PFTM_Enable 0 "Disabled" 1 "Enabled";
VAL_ 1474 Power_Tailgate_Enable 0 "Disabled" 1 "Enabled";
VAL_ 1474 Rear_G_LGT_with_Cargo_Lights 0 "Disable" 1 "Enable";
VAL_ 1474 Rear_Guidance_Light_Status 0 "OFF" 1 "ON";
VAL_ 1474 Rear_Lights_with_Approach 0 "Off_with_Approach" 1 "On_with_Approach";
VAL_ 1474 SignatureLightingEnable 0 "DISABLE" 1 "ENABLE";
VAL_ 1474 Trailer_Light_Check 0 "Disable" 1 "Enable";
VAL_ 1474 TSI_Offset_Kph 0 "0" 1 "1" 2 "2" 3 "3" 4 "4" 5 "5" 6 "6" 7 "7" 8 "8" 9 "9" 10 "10" 11 "11" 12 "12" 13 "13" 14 "14" 15 "15";
VAL_ 1474 TSI_Offset_Mph 0 "0" 1 "1" 2 "2" 3 "3" 4 "4" 5 "5" 6 "6" 7 "7" 8 "8" 9 "9" 10 "10";
VAL_ 1474 TurnSignalView 0 "Disable" 1 "Enable" 2 "Only_with_Trailer";
VAL_ 1474 WorksiteINVM_Audible_LFW 0 "OFF" 1 "ON";
VAL_ 1474 WorksiteINVM_Visual_LFW 0 "OFF" 1 "ON";
VAL_ 753 DCDC_OperationModeSts 0 "IDLE" 1 "Buck_CV" 2 "Buck_CC" 3 "Buck_CP" 4 "Buck_Special" 5 "Boost" 6 "Precharge" 7 "Discharge" 8 "Failure" 15 "SNA";
VAL_ 753 HVDC_CurrentFeedback 4095 "SNA";
VAL_ 753 HVDC_VoltageFeedback 4095 "SNA";
VAL_ 753 LVDC_CurrentFeedback 4095 "SNA";
VAL_ 1062 MCPA_Temp 255 "SNA";
VAL_ 2654486550 CBV_bit0_RepeatMessageRequestBit 0 "Repeat_Message_State_not_requested" 1 "Repeat_Message_State_requested";
VAL_ 2654486550 CBV_bit3_NMCoordinatorBit 0 "Start_of_synchronized_shutdown_is_not_requested_by_main_coordinator" 1 "Start_of_synchronized_shutdown_is_requested_by_main_coordinator";
VAL_ 2654486550 CBV_bit4_ActiveWakeupBit 0 "PassiveWakeup" 1 "ActiveWakeup";
VAL_ 2654486550 CBV_bit6_PartialNtwInfBit 0 "NM_PDU_contains_no_Partial_Network_request_information" 1 "NM_PDU_contains_Partial_Network_request_information";
VAL_ 2654486528 CBV_bit0_RepeatMessageRequestBit 0 "Repeat_Message_State_not_requested" 1 "Repeat_Message_State_requested";
VAL_ 2654486528 CBV_bit3_NMCoordinatorBit 0 "Start_of_synchronized_shutdown_is_not_requested_by_main_coordinator" 1 "Start_of_synchronized_shutdown_is_requested_by_main_coordinator";
VAL_ 2654486528 CBV_bit4_ActiveWakeupBit 0 "PassiveWakeup" 1 "ActiveWakeup";
VAL_ 2654486528 CBV_bit6_PartialNtwInfBit 0 "NM_PDU_contains_no_Partial_Network_request_information" 1 "NM_PDU_contains_Partial_Network_request_information";
VAL_ 2654486534 CBV_bit0_RepeatMessageRequestBit 0 "Repeat_Message_State_not_requested" 1 "Repeat_Message_State_requested";
VAL_ 2654486534 CBV_bit3_NMCoordinatorBit 0 "Start_of_synchronized_shutdown_is_not_requested_by_main_coordinator" 1 "Start_of_synchronized_shutdown_is_requested_by_main_coordinator";
VAL_ 2654486534 CBV_bit4_ActiveWakeupBit 0 "PassiveWakeup" 1 "ActiveWakeup";
VAL_ 2654486534 CBV_bit6_PartialNtwInfBit 0 "NM_PDU_contains_no_Partial_Network_request_information" 1 "NM_PDU_contains_Partial_Network_request_information";
VAL_ 2654486669 CBV_bit0_RepeatMessageRequestBit 0 "Repeat_Message_State_not_requested" 1 "Repeat_Message_State_requested";
VAL_ 2654486669 CBV_bit3_NMCoordinatorBit 0 "Start_of_synchronized_shutdown_is_not_requested_by_main_coordinator" 1 "Start_of_synchronized_shutdown_is_requested_by_main_coordinator";
VAL_ 2654486669 CBV_bit4_ActiveWakeupBit 0 "PassiveWakeup" 1 "ActiveWakeup";
VAL_ 2654486669 CBV_bit6_PartialNtwInfBit 0 "NM_PDU_contains_no_Partial_Network_request_information" 1 "NM_PDU_contains_Partial_Network_request_information";
VAL_ 2654486595 CBV_bit0_RepeatMessageRequestBit 0 "Repeat_Message_State_not_requested" 1 "Repeat_Message_State_requested";
VAL_ 2654486595 CBV_bit3_NMCoordinatorBit 0 "Start_of_synchronized_shutdown_is_not_requested_by_main_coordinator" 1 "Start_of_synchronized_shutdown_is_requested_by_main_coordinator";
VAL_ 2654486595 CBV_bit4_ActiveWakeupBit 0 "PassiveWakeup" 1 "ActiveWakeup";
VAL_ 2654486595 CBV_bit6_PartialNtwInfBit 0 "NM_PDU_contains_no_Partial_Network_request_information" 1 "NM_PDU_contains_Partial_Network_request_information";
VAL_ 2654486529 CBV_bit0_RepeatMessageRequestBit 0 "Repeat_Message_State_not_requested" 1 "Repeat_Message_State_requested";
VAL_ 2654486529 CBV_bit3_NMCoordinatorBit 0 "Start_of_synchronized_shutdown_is_not_requested_by_main_coordinator" 1 "Start_of_synchronized_shutdown_is_requested_by_main_coordinator";
VAL_ 2654486529 CBV_bit4_ActiveWakeupBit 0 "PassiveWakeup" 1 "ActiveWakeup";
VAL_ 2654486529 CBV_bit6_PartialNtwInfBit 0 "NM_PDU_contains_no_Partial_Network_request_information" 1 "NM_PDU_contains_Partial_Network_request_information";
VAL_ 2654486592 CBV_bit4_ActiveWakeupBit 0 "PassiveWakeup" 1 "ActiveWakeup";
VAL_ 2654486672 CBV_bit0_RepeatMessageRequestBit 0 "Repeat_Message_State_not_requested" 1 "Repeat_Message_State_requested";
VAL_ 2654486672 CBV_bit3_NMCoordinatorBit 0 "Start_of_synchronized_shutdown_is_not_requested_by_main_coordinator" 1 "Start_of_synchronized_shutdown_is_requested_by_main_coordinator";
VAL_ 2654486672 CBV_bit4_ActiveWakeupBit 0 "PassiveWakeup" 1 "ActiveWakeup";
VAL_ 2654486672 CBV_bit6_PartialNtwInfBit 0 "NM_PDU_contains_no_Partial_Network_request_information" 1 "NM_PDU_contains_Partial_Network_request_information";
VAL_ 2654486626 CBV_bit0_RepeatMessageRequestBit 0 "Repeat Message State not requested" 1 "Repeat Message State requested";
VAL_ 2654486626 CBV_bit3_NMCoordinatorBit 0 "Start of synchronized shutdown is not requested by main coordinator" 1 "Start of synchronized shutdown is requested by main coordinator";
VAL_ 2654486626 CBV_bit4_ActiveWakeupBit 0 "PassiveWakeup" 1 "ActiveWakeup";
VAL_ 2654486626 CBV_bit6_PartialNtwInfBit 0 "NM PDU contains no Partial Network request information" 1 "NM PDU contains Partial Network request information";
VAL_ 2654486531 CBV_bit0_RepeatMessageRequestBit 0 "Repeat_Message_State_not_requested" 1 "Repeat_Message_State_requested";
VAL_ 2654486531 CBV_bit3_NMCoordinatorBit 0 "Start_of_synchronized_shutdown_is_not_requested_by_main_coordinator" 1 "Start_of_synchronized_shutdown_is_requested_by_main_coordinator";
VAL_ 2654486531 CBV_bit4_ActiveWakeupBit 0 "PassiveWakeup" 1 "ActiveWakeup";
VAL_ 2654486531 CBV_bit6_PartialNtwInfBit 0 "NM_PDU_contains_no_Partial_Network_request_information" 1 "NM_PDU_contains_Partial_Network_request_information";
VAL_ 2654486593 CBV_bit0_RepeatMessageRequestBit 0 "Repeat_Message_State_not_requested" 1 "Repeat_Message_State_requested";
VAL_ 2654486593 CBV_bit3_NMCoordinatorBit 0 "Start_of_synchronized_shutdown_is_not_requested_by_main_coordinator" 1 "Start_of_synchronized_shutdown_is_requested_by_main_coordinator";
VAL_ 2654486593 CBV_bit4_ActiveWakeupBit 0 "PassiveWakeup" 1 "ActiveWakeup";
VAL_ 2654486593 CBV_bit6_PartialNtwInfBit 0 "NM_PDU_contains_no_Partial_Network_request_information" 1 "NM_PDU_contains_Partial_Network_request_information";
VAL_ 2654486640 CBV_bit0_RepeatMessageRequestBit 0 "Repeat_Message_State_not_requested" 1 "Repeat_Message_State_requested";
VAL_ 2654486640 CBV_bit3_NMCoordinatorBit 0 "Start_of_synchronized_shutdown_is_not_requested_by_main_coordinator" 1 "Start_of_synchronized_shutdown_is_requested_by_main_coordinator";
VAL_ 2654486640 CBV_bit4_ActiveWakeupBit 0 "PassiveWakeup" 1 "ActiveWakeup";
VAL_ 2654486640 CBV_bit6_PartialNtwInfBit 0 "NM_PDU_contains_no_Partial_Network_request_information" 1 "NM_PDU_contains_Partial_Network_request_information";
VAL_ 2654486539 CBV_bit0_RepeatMessageRequestBit 0 "Repeat_Message_State_not_requested" 1 "Repeat_Message_State_requested";
VAL_ 2654486539 CBV_bit3_NMCoordinatorBit 0 "Start_of_synchronized_shutdown_is_not_requested_by_main_coordinator" 1 "Start_of_synchronized_shutdown_is_requested_by_main_coordinator";
VAL_ 2654486539 CBV_bit4_ActiveWakeupBit 0 "PassiveWakeup" 1 "ActiveWakeup";
VAL_ 2654486539 CBV_bit6_PartialNtwInfBit 0 "NM_PDU_contains_no_Partial_Network_request_information" 1 "NM_PDU_contains_Partial_Network_request_information";
